[part 5 of 12: package /Cluster]
AUTOSAR XML (schema 4-3-0)
package /Cluster  (continued)
  can cluster HCP5_CANFD01: baudrate=500000, protocol-name=CAN, protocol-version=2.0, bus-off-recovery={bor-counter-l-1-to-l-2=1, bor-time-l-1=0.05, bor-time-l-2=0.2}, can-fd-baudrate=2000000  (continued)
    can physical channel CHNL: comm-connectors=CN_HCP5_CANFD01  (continued)
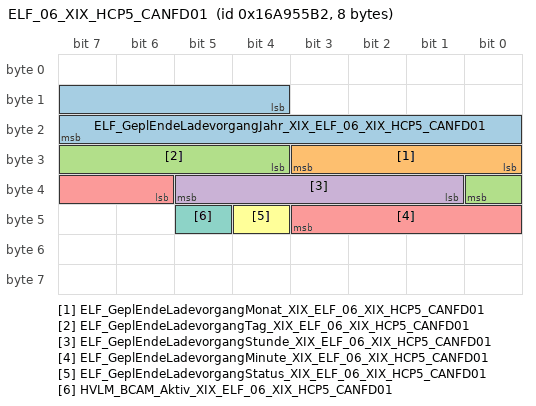
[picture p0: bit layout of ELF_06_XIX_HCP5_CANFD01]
      frame ELF_06_XIX_HCP5_CANFD01: id 0x16A955B2, to BMC_HV, frame-length=8, can-addressing-mode=EXTENDED, can-frame-rx-behavior=CAN-FD, can-frame-tx-behavior=CAN-FD
        pdu ELF_06_XIX_HCP5_CANFD01: length=8, transmission-mode-true-timing=cyclic-timing={time-offset=0, time-period=0.2}, unused-bit-pattern=0
          signal ELF_GeplEndeLadevorgangJahr_XIX_ELF_06_XIX_HCP5_CANFD01: start 12, 12 bit, little-endian, data-type-policy=OVERRIDE, i-signal-type=PRIMITIVE, init-value=4095, base-type=BT_ELF_GeplEndeLadevorgangJahr, compu {phys=raw for raw 0..4094, 4095=Cxfff_InitWert (CM_ELF_GeplEndeLadevorgangJahr_Cxfff_InitWert); unit Unit_Year}, range phys 0..4094 Unit_Year, raw 0..4095, unit=Unit_Year, transfer-property=PENDING  # Geplantes Ende des Ladevorgangs bei Laden nach Ladeplan, Jahr.
          signal ELF_GeplEndeLadevorgangMonat_XIX_ELF_06_XIX_HCP5_CANFD01: start 24, 4 bit, little-endian, data-type-policy=OVERRIDE, i-signal-type=PRIMITIVE, init-value=15, base-type=BT_ELF_GeplEndeLadevorgangMonat, compu {phys=raw for raw 1..12, 15=Cxf_Init (CM_ELF_GeplEndeLadevorgangMonat_Cxf_Init); unit Unit_Month}, range phys 1..12 Unit_Month, raw 1..15, unit=Unit_Month, transfer-property=PENDING  # Geplantes Ende bei Laden nach Ladeplan(Monat).
          signal ELF_GeplEndeLadevorgangTag_XIX_ELF_06_XIX_HCP5_CANFD01: start 28, 5 bit, little-endian, data-type-policy=OVERRIDE, i-signal-type=PRIMITIVE, init-value=0, base-type=BT_ELF_GeplEndeLadevorgangTag, compu {0=Cx0_Init (CM_ELF_GeplEndeLadevorgangTag_Cx0_Init), phys=raw for raw 1..31; unit Unit_Day}, range phys 1..31 Unit_Day, raw 0..31, unit=Unit_Day, transfer-property=PENDING  # Geplantes Ladeende bei Laden nach Ladeplan (Tag).
          signal ELF_GeplEndeLadevorgangStunde_XIX_ELF_06_XIX_HCP5_CANFD01: start 33, 5 bit, little-endian, data-type-policy=OVERRIDE, i-signal-type=PRIMITIVE, init-value=31, base-type=BT_ELF_GeplEndeLadevorgangStunde, compu {phys=raw for raw 0..23, 31=Cx1f_InitWert (CM_ELF_GeplEndeLadevorgangStunde_Cx1f_InitWert); unit Unit_Hours}, range phys 0..23 Unit_Hours, raw 0..31, unit=Unit_Hours, transfer-property=PENDING  # Geplantes Ladeende bei Laden nach Ladeplan, Stunde.
          signal ELF_GeplEndeLadevorgangMinute_XIX_ELF_06_XIX_HCP5_CANFD01: start 38, 6 bit, little-endian, data-type-policy=OVERRIDE, i-signal-type=PRIMITIVE, init-value=63, base-type=BT_ELF_GeplEndeLadevorgangMinute, compu {phys=raw for raw 0..59, 63=Cx3f_InitWert (CM_ELF_GeplEndeLadevorgangMinute_Cx3f_InitWert); unit Unit_Minut}, range phys 0..59 Unit_Minut, raw 0..63, unit=Unit_Minut, transfer-property=PENDING  # Geplantes Ladeende bei Laden nach Ladeplan, Minute.
          signal ELF_GeplEndeLadevorgangStatus_XIX_ELF_06_XIX_HCP5_CANFD01: start 44, 1 bit, little-endian, data-type-policy=OVERRIDE, i-signal-type=PRIMITIVE, init-value=0, base-type=BT_ELF_GeplEndeLadevorgangStatus, compu {0=Cx0_Startzeit_nicht_beruecksichtigen (CM_ELF_GeplEndeLadevorgangStatus_Cx0_Startzeit_nicht_beruecksichtigen), 1=Cx1_Startzeit_beruecksichtigen (CM_ELF_GeplEndeLadevorgangStatus_Cx1_Startzeit_beruecksichtigen)}, range raw 0..1, transfer-property=PENDING  # Gibt den Status des geplanten Ladeendes an und ob die hinterlegte Startzeit berücksichtigt werden soll.
          signal HVLM_BCAM_Aktiv_XIX_ELF_06_XIX_HCP5_CANFD01: start 45, 1 bit, little-endian, data-type-policy=OVERRIDE, i-signal-type=PRIMITIVE, init-value=0, base-type=BT_HVLM_BCAM_Aktiv, compu {0=Cx0_inaktiv (CM_HVLM_BCAM_Aktiv_Cx0_inaktiv), 1=Cx1_aktiv (CM_HVLM_BCAM_Aktiv_Cx1_aktiv)}, range raw 0..1, transfer-property=PENDING, to BMC_HV(timeout 2 s)  # Dieses Signal gibt den Aktivierungsstatus des Battery Charging Care Modes an und gehört zum HV-Laden
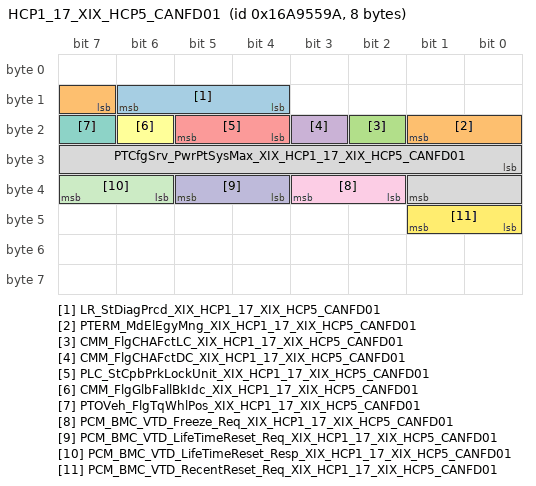
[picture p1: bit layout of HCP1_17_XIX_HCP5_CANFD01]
      frame HCP1_17_XIX_HCP5_CANFD01: id 0x16A9559A, to BMC_HV, frame-length=8, can-addressing-mode=EXTENDED, can-frame-rx-behavior=CAN-FD, can-frame-tx-behavior=CAN-FD
        pdu HCP1_17_XIX_HCP5_CANFD01: length=8, minimum-delay=0.1, transmission-mode-true-timing={cyclic-timing={time-offset=0, time-period=1}, event-controlled-timing={number-of-repetitions=0, repetition-period=0}}, unused-bit-pattern=0
          signal LR_StDiagPrcd_XIX_HCP1_17_XIX_HCP5_CANFD01: start 12, 3 bit, little-endian, data-type-policy=OVERRIDE, i-signal-type=PRIMITIVE, init-value=6, base-type=BT_LR_StDiagPrcd, invalid-value=Invalid_LR_StDiagPrcd_XIX_HCP1_17_XIX_HCP5_CANFD01:7, compu {0=Cx0_Inactive (CM_LR_StDiagPrcd_Cx0_Inactive), 1=Cx1_Not_available (CM_LR_StDiagPrcd_Cx1_Not_available), 2=Cx2_Conditions_not_fulfilled (CM_LR_StDiagPrcd_Cx2_Conditions_not_fulfilled), 3=Cx3_Running (CM_LR_StDiagPrcd_Cx3_Running), 4=Cx4_Finished_successful (CM_LR_StDiagPrcd_Cx4_Finished_successful), 5=Cx5_Finished_failed (CM_LR_StDiagPrcd_Cx5_Finished_failed), 6=Cx6_Init (CM_LR_StDiagPrcd_Cx6_Init), 7=Cx7_Fehler (CM_LR_StDiagPrcd_Cx7_Fehler)}, range raw 0..7, transfer-property=PENDING  # State of DMPLR component test
          signal PTERM_MdElEgyMng_XIX_HCP1_17_XIX_HCP5_CANFD01: start 15, 3 bit, little-endian, data-type-policy=OVERRIDE, i-signal-type=PRIMITIVE, init-value=0, base-type=BT_PTERM_MdElEgyMng, compu {0=Cx0_No_Hybrid (CM_PTERM_MdElEgyMng_Cx0_No_Hybrid), 1=Cx1_Depleting (CM_PTERM_MdElEgyMng_Cx1_Depleting), 2=Cx2_Soft_Depleting (CM_PTERM_MdElEgyMng_Cx2_Soft_Depleting), 3=Cx3_Sustaining (CM_PTERM_MdElEgyMng_Cx3_Sustaining), 4=Cx4_Increasing (CM_PTERM_MdElEgyMng_Cx4_Increasing), 5=Cx5_External_Control (CM_PTERM_MdElEgyMng_Cx5_External_Control)}, range raw 0..5, transfer-property=TRIGGERED-ON-CHANGE-WITHOUT-REPETITION  # mode of electic engergy management
          signal CMM_FlgCHAFctLC_XIX_HCP1_17_XIX_HCP5_CANFD01: start 18, 1 bit, little-endian, data-type-policy=OVERRIDE, i-signal-type=PRIMITIVE, init-value=0, base-type=BT_CMM_FlgCHAFctLC, compu {0=Cx0_charisma_off (CM_CMM_FlgCHAFctLC_Cx0_charisma_off), 1=Cx1_charisma_on (CM_CMM_FlgCHAFctLC_Cx1_charisma_on)}, range raw 0..1, transfer-property=TRIGGERED-ON-CHANGE-WITHOUT-REPETITION  # Signal to distinguish between LC system low and high. Information if LC is coded for charisma or not.
          signal CMM_FlgCHAFctDC_XIX_HCP1_17_XIX_HCP5_CANFD01: start 19, 1 bit, little-endian, data-type-policy=OVERRIDE, i-signal-type=PRIMITIVE, init-value=0, base-type=BT_CMM_FlgCHAFctDC, compu {0=Cx0_charisma_off (CM_CMM_FlgCHAFctDC_Cx0_charisma_off), 1=Cx1_charisma_on (CM_CMM_FlgCHAFctDC_Cx1_charisma_on)}, range raw 0..1, transfer-property=TRIGGERED-ON-CHANGE-WITHOUT-REPETITION  # Signal to distinguish between DC system low and high. Information if DC is coded for charisma or not.
          signal PLC_StCpbPrkLockUnit_XIX_HCP1_17_XIX_HCP5_CANFD01: start 20, 2 bit, little-endian, data-type-policy=OVERRIDE, i-signal-type=PRIMITIVE, init-value=2, base-type=BT_PLC_StCpbPrkLockUnit, invalid-value=Invalid_PLC_StCpbPrkLockUnit_XIX_HCP1_17_XIX_HCP5_CANFD01:3, compu {0=Cx0_Nicht_Verfuegbar (CM_PLC_StCpbPrkLockUnit_Cx0_Nicht_Verfuegbar) (Nicht Verfügbar), 1=Cx1_Verfuegbar (CM_PLC_StCpbPrkLockUnit_Cx1_Verfuegbar) (Verfügbar), 2=Cx2_Init (CM_PLC_StCpbPrkLockUnit_Cx2_Init), 3=Cx3_Fehler (CM_PLC_StCpbPrkLockUnit_Cx3_Fehler)}, range raw 0..3, transfer-property=TRIGGERED-ON-CHANGE-WITHOUT-REPETITION  # Beschreibt die Fähigkeit der Parksperreneinheit zu Verfahren und die eingenommene Position korrekt zu melden.
          signal CMM_FlgGlbFallBkIdc_XIX_HCP1_17_XIX_HCP5_CANFD01: start 22, 1 bit, little-endian, data-type-policy=OVERRIDE, i-signal-type=PRIMITIVE, init-value=0, base-type=BT_CMM_FlgGlbFallBkIdc, compu {0=Cx0_no_fallback (CM_CMM_FlgGlbFallBkIdc_Cx0_no_fallback), 1=Cx1_fallback_requested (CM_CMM_FlgGlbFallBkIdc_Cx1_fallback_requested)}, range raw 0..1, transfer-property=PENDING  # Signal to request a global fallback of the Charisma mode to default value.
          signal PTOVeh_FlgTqWhlPos_XIX_HCP1_17_XIX_HCP5_CANFD01: start 23, 1 bit, little-endian, data-type-policy=OVERRIDE, i-signal-type=PRIMITIVE, init-value=0, base-type=BT_PTOVeh_FlgTqWhlPos, compu {0=Cx0_overall_static_wheel_torque_is_negative_or_zero (CM_PTOVeh_FlgTqWhlPos_Cx0_overall_static_wheel_torque_is_negative_or_zero), 1=Cx1_overall_static_wheel_torque_is_positive (CM_PTOVeh_FlgTqWhlPos_Cx1_overall_static_wheel_torque_is_positive)}, range raw 0..1, transfer-property=PENDING  # flag indicating overall static wheel torque is positive
          signal PTCfgSrv_PwrPtSysMax_XIX_HCP1_17_XIX_HCP5_CANFD01: start 24, 10 bit, little-endian, data-type-policy=OVERRIDE, i-signal-type=PRIMITIVE, init-value=0, base-type=BT_PTCfgSrv_PwrPtSysMax, compu {phys=raw*2 for raw 0..1000; unit Unit_KiloWatt}, range phys 0..2000 Unit_KiloWatt, raw 0..1000, unit=Unit_KiloWatt, transfer-property=PENDING  # Gesamtleistung des Antriebsstrangs in kW
          signal PCM_BMC_VTD_Freeze_Req_XIX_HCP1_17_XIX_HCP5_CANFD01: start 34, 2 bit, little-endian, data-type-policy=OVERRIDE, i-signal-type=PRIMITIVE, init-value=2, base-type=BT_PCM_BMC_VTD_Freeze_Req, invalid-value=Invalid_PCM_BMC_VTD_Freeze_Req_XIX_HCP1_17_XIX_HCP5_CANFD01:3, compu {0=Cx0_NoResetResponse (CM_PCM_BMC_VTD_Freeze_Req_Cx0_NoResetResponse), 1=Cx1_ResetResponse (CM_PCM_BMC_VTD_Freeze_Req_Cx1_ResetResponse), 2=Cx2_Init (CM_PCM_BMC_VTD_Freeze_Req_Cx2_Init), 3=Cx3_Fehler (CM_PCM_BMC_VTD_Freeze_Req_Cx3_Fehler)}, range raw 0..3, transfer-property=PENDING, to BMC_HV(timeout 5 s)  # Synchronissation of Freeze-Condition for VTD-ITs between HCP1 and BMC
          signal PCM_BMC_VTD_LifeTimeReset_Req_XIX_HCP1_17_XIX_HCP5_CANFD01: start 36, 2 bit, little-endian, data-type-policy=OVERRIDE, i-signal-type=PRIMITIVE, init-value=2, base-type=BT_PCM_BMC_VTD_LifeTimeReset_Req, invalid-value=Invalid_PCM_BMC_VTD_LifeTimeReset_Req_XIX_HCP1_17_XIX_HCP5_CANFD01:3, compu {0=Cx0_NoResetResponse (CM_PCM_BMC_VTD_LifeTimeReset_Req_Cx0_NoResetResponse), 1=Cx1_ResetResponse (CM_PCM_BMC_VTD_LifeTimeReset_Req_Cx1_ResetResponse), 2=Cx2_Init (CM_PCM_BMC_VTD_LifeTimeReset_Req_Cx2_Init), 3=Cx3_Fehler (CM_PCM_BMC_VTD_LifeTimeReset_Req_Cx3_Fehler)}, range raw 0..3, transfer-property=PENDING, to BMC_HV(timeout 5 s)  # Synchronissation of Freeze-Condition for VTD-ITs between HCP1 and BMC
          signal PCM_BMC_VTD_LifeTimeReset_Resp_XIX_HCP1_17_XIX_HCP5_CANFD01: start 38, 2 bit, little-endian, data-type-policy=OVERRIDE, i-signal-type=PRIMITIVE, init-value=2, base-type=BT_PCM_BMC_VTD_LifeTimeReset_Resp, invalid-value=Invalid_PCM_BMC_VTD_LifeTimeReset_Resp_XIX_HCP1_17_XIX_HCP5_CANFD01:3, compu {0=Cx0_NoResetResponse (CM_PCM_BMC_VTD_LifeTimeReset_Resp_Cx0_NoResetResponse), 1=Cx1_ResetResponse (CM_PCM_BMC_VTD_LifeTimeReset_Resp_Cx1_ResetResponse), 2=Cx2_Init (CM_PCM_BMC_VTD_LifeTimeReset_Resp_Cx2_Init), 3=Cx3_Fehler (CM_PCM_BMC_VTD_LifeTimeReset_Resp_Cx3_Fehler)}, range raw 0..3, transfer-property=PENDING, to BMC_HV(timeout 5 s)  # Synchronissation of Freeze-Condition for VTD-ITs between HCP1 and BMC
          signal PCM_BMC_VTD_RecentReset_Req_XIX_HCP1_17_XIX_HCP5_CANFD01: start 40, 2 bit, little-endian, data-type-policy=OVERRIDE, i-signal-type=PRIMITIVE, init-value=2, base-type=BT_PCM_BMC_VTD_RecentReset_Req, invalid-value=Invalid_PCM_BMC_VTD_RecentReset_Req_XIX_HCP1_17_XIX_HCP5_CANFD01:3, compu {0=Cx0_NoResetResponse (CM_PCM_BMC_VTD_RecentReset_Req_Cx0_NoResetResponse), 1=Cx1_ResetResponse (CM_PCM_BMC_VTD_RecentReset_Req_Cx1_ResetResponse), 2=Cx2_Init (CM_PCM_BMC_VTD_RecentReset_Req_Cx2_Init), 3=Cx3_Fehler (CM_PCM_BMC_VTD_RecentReset_Req_Cx3_Fehler)}, range raw 0..3, transfer-property=PENDING, to BMC_HV(timeout 5 s)  # Synchronissation of Freeze-Condition for VTD-ITs between HCP1 and BMC
      frame HVEM_07_XIX_HCP5_CANFD01: id 0xAF954C7, to BMC_HV, frame-length=32, can-addressing-mode=EXTENDED, can-frame-rx-behavior=CAN-FD, can-frame-tx-behavior=CAN-FD
        pdu HVEM_07_XIX_HCP5_CANFD01: length=32, minimum-delay=0.01, transmission-mode-true-timing={cyclic-timing={time-offset=0, time-period=0.08}, event-controlled-timing={number-of-repetitions=0, repetition-period=0}}, unused-bit-pattern=0
          signal HVEM_Nachladen_Anf_XIX_HVEM_07_XIX_HCP5_CANFD01: start 12, 1 bit, little-endian, data-type-policy=OVERRIDE, i-signal-type=PRIMITIVE, init-value=0, base-type=BT_HVEM_Nachladen_Anf, compu {0=Cx0_keine_Anforderung (CM_HVEM_Nachladen_Anf_Cx0_keine_Anforderung), 1=Cx1_Nachladen_angefordert (CM_HVEM_Nachladen_Anf_Cx1_Nachladen_angefordert)}, range raw 0..1, transfer-property=TRIGGERED-ON-CHANGE-WITHOUT-REPETITION  # Anforderung für HV Laden bei gestecktem Stecker und deaktivierter Ladeanforderung
          signal HVEM_IstLeistung_HVVerbraucher_XIX_HVEM_07_XIX_HCP5_CANFD01: start 13, 12 bit, little-endian, data-type-policy=OVERRIDE, i-signal-type=PRIMITIVE, init-value=4094, base-type=BT_HVEM_IstLeistung_HVVerbraucher, invalid-value=Invalid_HVEM_IstLeistung_HVVerbraucher_XIX_HVEM_07_XIX_HCP5_CANFD01:4095, compu {phys=raw*50-102300 for raw 0..4093, 4094=Cxffe_Init (CM_HVEM_IstLeistung_HVVerbraucher_Cxffe_Init), 4095=Cxfff_Fehler (CM_HVEM_IstLeistung_HVVerbraucher_Cxfff_Fehler); unit Unit_Watt}, range phys -102300..102350 Unit_Watt, raw 0..4095, unit=Unit_Watt, transfer-property=PENDING  # Ist Verbrauch der Nebenverbraucher (hochvoltseitig)
          signal HVEM_Nachlad_Status_XIX_HVEM_07_XIX_HCP5_CANFD01: start 25, 2 bit, little-endian, data-type-policy=OVERRIDE, i-signal-type=PRIMITIVE, init-value=3, base-type=BT_HVEM_Nachlad_Status, compu {0=Cx0_nicht_moeglich_Fehler (CM_HVEM_Nachlad_Status_Cx0_nicht_moeglich_Fehler) (nicht_moeglich__Fehler), 1=Cx1_moeglich_begonnen (CM_HVEM_Nachlad_Status_Cx1_moeglich_begonnen) (moeglich__begonnen), 2=Cx2_Beendet (CM_HVEM_Nachlad_Status_Cx2_Beendet), 3=Cx3_Init (CM_HVEM_Nachlad_Status_Cx3_Init)}, range raw 0..3, transfer-property=TRIGGERED-ON-CHANGE-WITHOUT-REPETITION  # Status der Umsetzung der Nachladeanforderung der NV-Seite.
          signal HVEM_TME_Energie_Vorgabe_XIX_HVEM_07_XIX_HCP5_CANFD01: start 27, 11 bit, little-endian, data-type-policy=OVERRIDE, i-signal-type=PRIMITIVE, init-value=2046, base-type=BT_HVEM_TME_Energie_Vorgabe, invalid-value=Invalid_HVEM_TME_Energie_Vorgabe_XIX_HVEM_07_XIX_HCP5_CANFD01:2047, compu {phys=raw*10 for raw 0..2045, 2046=Cx7fe_Init (CM_HVEM_TME_Energie_Vorgabe_Cx7fe_Init), 2047=Cx7ff_Fehler (CM_HVEM_TME_Energie_Vorgabe_Cx7ff_Fehler); unit Unit_WattHour}, range phys 0..20450 Unit_WattHour, raw 0..2047, unit=Unit_WattHour, transfer-property=PENDING  # Erweiterte Auflösung von 10Wh für Signal HVEM_Energie_Klima_Vorgabe.
          signal HVEM_TME_Leistung_Vorgabe_XIX_HVEM_07_XIX_HCP5_CANFD01: start 38, 10 bit, little-endian, data-type-policy=OVERRIDE, i-signal-type=PRIMITIVE, init-value=1022, base-type=BT_HVEM_TME_Leistung_Vorgabe, invalid-value=Invalid_HVEM_TME_Leistung_Vorgabe_XIX_HVEM_07_XIX_HCP5_CANFD01:1023, compu {phys=raw*50 for raw 0..1021, 1022=Cx3fe_Init (CM_HVEM_TME_Leistung_Vorgabe_Cx3fe_Init), 1023=Cx3ff_Fehler (CM_HVEM_TME_Leistung_Vorgabe_Cx3ff_Fehler); unit Unit_Watt}, range phys 0..51050 Unit_Watt, raw 0..1023, unit=Unit_Watt, transfer-property=PENDING  # Die Leistung, welche das HVEM der TME zur Verfügung stellt.
          signal HVEM_IstStrom_HVVerbraucher_XIX_HVEM_07_XIX_HCP5_CANFD01: start 48, 12 bit, little-endian, data-type-policy=OVERRIDE, i-signal-type=PRIMITIVE, init-value=4094, base-type=BT_HVEM_IstStrom_HVVerbraucher, invalid-value=Invalid_HVEM_IstStrom_HVVerbraucher_XIX_HVEM_07_XIX_HCP5_CANFD01:4095, compu {phys=raw*0.1-204.7 for raw 0..4093, 4094=Cxffe_Init (CM_HVEM_IstStrom_HVVerbraucher_Cxffe_Init), 4095=Cxfff_Fehler (CM_HVEM_IstStrom_HVVerbraucher_Cxfff_Fehler); unit Unit_Amper}, range phys -204.7..204.6 Unit_Amper, raw 0..4095, unit=Unit_Amper, transfer-property=PENDING  # Iststromaufnahme der elektrischen Nebenaggregate aus dem HV Zwischenkreis
          signal HVEM_AIAD_Energieinhalt_XIX_HVEM_07_XIX_HCP5_CANFD01: start 60, 11 bit, little-endian, data-type-policy=OVERRIDE, i-signal-type=PRIMITIVE, init-value=2046, base-type=BT_HVEM_AIAD_Energieinhalt, invalid-value=Invalid_HVEM_AIAD_Energieinhalt_XIX_HVEM_07_XIX_HCP5_CANFD01:2047, compu {phys=raw*50 for raw 0..2045, 2046=Cx7fe_Init (CM_HVEM_AIAD_Energieinhalt_Cx7fe_Init), 2047=Cx7ff_Fehler (CM_HVEM_AIAD_Energieinhalt_Cx7ff_Fehler); unit Unit_WattHour}, range phys 0..102250 Unit_WattHour, raw 0..2047, unit=Unit_WattHour, transfer-property=PENDING  # Erweiterte Auflösung
          signal HVEM_AIAD_Leistungsvorgabe_XIX_HVEM_07_XIX_HCP5_CANFD01: start 71, 9 bit, little-endian, data-type-policy=OVERRIDE, i-signal-type=PRIMITIVE, init-value=510, base-type=BT_HVEM_AIAD_Leistungsvorgabe, invalid-value=Invalid_HVEM_AIAD_Leistungsvorgabe_XIX_HVEM_07_XIX_HCP5_CANFD01:511, compu {phys=raw*50 for raw 0..509, 510=Cx1fe_Init (CM_HVEM_AIAD_Leistungsvorgabe_Cx1fe_Init), 511=Cx1ff_Fehler (CM_HVEM_AIAD_Leistungsvorgabe_Cx1ff_Fehler); unit Unit_Watt}, range phys 0..25450 Unit_Watt, raw 0..511, unit=Unit_Watt, transfer-property=PENDING  # Leistungsvorgabe vom HVEM an das ADC
          signal HVEM_STK_Leistung_verfuegbar_XIX_HVEM_07_XIX_HCP5_CANFD01: start 80, 8 bit, little-endian, data-type-policy=OVERRIDE, i-signal-type=PRIMITIVE, init-value=254, base-type=BT_HVEM_STK_Leistung_verfuegbar, invalid-value=Invalid_HVEM_STK_Leistung_verfuegbar_XIX_HVEM_07_XIX_HCP5_CANFD01:255, compu {phys=raw*50 for raw 0..253, 254=Cxfe_Init (CM_HVEM_STK_Leistung_verfuegbar_Cxfe_Init), 255=Cxff_Fehler (CM_HVEM_STK_Leistung_verfuegbar_Cxff_Fehler); unit Unit_Watt}, range phys 0..12650 Unit_Watt, raw 0..255, unit=Unit_Watt, transfer-property=PENDING  # Verfügbare Leistung seitens Ladeinfrastruktur für die Standklimatisierung
          signal HVEM_Abschaltstufe_XIX_HVEM_07_XIX_HCP5_CANFD01: start 88, 3 bit, little-endian, data-type-policy=OVERRIDE, i-signal-type=PRIMITIVE, init-value=6, base-type=BT_HVEM_Abschaltstufe, invalid-value=Invalid_HVEM_Abschaltstufe_XIX_HVEM_07_XIX_HCP5_CANFD01:7, compu {0=Cx0_Stufe0 (CM_HVEM_Abschaltstufe_Cx0_Stufe0), 1=Cx1_Stufe1 (CM_HVEM_Abschaltstufe_Cx1_Stufe1), 2=Cx2_Stufe2 (CM_HVEM_Abschaltstufe_Cx2_Stufe2), 3=Cx3_Stufe3 (CM_HVEM_Abschaltstufe_Cx3_Stufe3), 4=Cx4_Stufe4 (CM_HVEM_Abschaltstufe_Cx4_Stufe4), 5=Cx5_Stufe5 (CM_HVEM_Abschaltstufe_Cx5_Stufe5), 6=Cx6_Init (CM_HVEM_Abschaltstufe_Cx6_Init), 7=Cx7_Fehler (CM_HVEM_Abschaltstufe_Cx7_Fehler)}, range raw 0..7, transfer-property=TRIGGERED-ON-CHANGE-WITHOUT-REPETITION  # Abschaltstufen an die Hochvoltteilnehmer
          signal HVEM_TME_Sollstatus_XIX_HVEM_07_XIX_HCP5_CANFD01: start 91, 2 bit, little-endian, data-type-policy=OVERRIDE, i-signal-type=PRIMITIVE, init-value=0, base-type=BT_HVEM_TME_Sollstatus, compu {0=Cx0_Regelbetrieb (CM_HVEM_TME_Sollstatus_Cx0_Regelbetrieb), 1=Cx1_Leistung_reduzieren (CM_HVEM_TME_Sollstatus_Cx1_Leistung_reduzieren), 2=Cx2_Verzoegerung_Lastabwurf (CM_HVEM_TME_Sollstatus_Cx2_Verzoegerung_Lastabwurf), 3=Cx3_Leistung_erhoehen (CM_HVEM_TME_Sollstatus_Cx3_Leistung_erhoehen)}, range raw 0..3, transfer-property=TRIGGERED-ON-CHANGE-WITHOUT-REPETITION  # Leistungskommandierung der TME aufgrund externer Einfluesse. Es kann eine Leistungserhöhung (Mindestschub), eine Leistungsreduzierung (Kick Down) oder ein verzoegerter Lastabwurf angefragt werden.
          signal HVEM_StCpbDrv_XIX_HVEM_07_XIX_HCP5_CANFD01: start 93, 3 bit, little-endian, data-type-policy=OVERRIDE, i-signal-type=PRIMITIVE, init-value=0, base-type=BT_HVEM_StCpbDrv, compu {0=Cx0_Init (CM_HVEM_StCpbDrv_Cx0_Init), 1=Cx1_erweiterte_Performance_verfuegbar (CM_HVEM_StCpbDrv_Cx1_erweiterte_Performance_verfuegbar) (erweiterte_Performance_verfügbar), 2=Cx2_normale_Performance_verfuegbar (CM_HVEM_StCpbDrv_Cx2_normale_Performance_verfuegbar) (normale_Performance_verfügbar), 3=Cx3_geringfuegige_Leistungseinschraenkung (CM_HVEM_StCpbDrv_Cx3_geringfuegige_Leistungseinschraenkung) (geringfügige_Leistungseinschränkung), 4=Cx4_Warnung_erhebliche_Leistungseinschraenkung (CM_HVEM_StCpbDrv_Cx4_Warnung_erhebliche_Leistungseinschraenkung) (Warnung_erhebliche_Leistungseinschränkung), 5=Cx5_Fehler_schwerwiegende_Leistungseinschraenkung (CM_HVEM_StCpbDrv_Cx5_Fehler_schwerwiegende_Leistungseinschraenkung) (Fehler_schwerwiegende_Leistungseinschränkung)}, range raw 0..5, transfer-property=PENDING  # Leistungsfähigkeit der HVB für Antrieb
          signal HVEM_ETM_Max_Ladeleistung_XIX_HVEM_07_XIX_HCP5_CANFD01: start 96, 13 bit, little-endian, data-type-policy=OVERRIDE, i-signal-type=PRIMITIVE, init-value=8190, base-type=BT_HVEM_ETM_Max_Ladeleistung, invalid-value=Invalid_HVEM_ETM_Max_Ladeleistung_XIX_HVEM_07_XIX_HCP5_CANFD01:8191, compu {phys=raw*100 for raw 0..8189, 8190=Cx1ffe_Init (CM_HVEM_ETM_Max_Ladeleistung_Cx1ffe_Init), 8191=Cx1fff_Fehler (CM_HVEM_ETM_Max_Ladeleistung_Cx1fff_Fehler); unit Unit_Watt}, range phys 0..818900 Unit_Watt, raw 0..8191, unit=Unit_Watt, transfer-property=TRIGGERED-ON-CHANGE-WITHOUT-REPETITION  # Elektrische Leistung, die dem ETM vom HVEM zur Abgabe von den elektrischen Antriebsmaschinen freigegeben wird (generatorischer Betrieb)
          signal HVEM_Leistungsvorhalt_Entladen_XIX_HVEM_07_XIX_HCP5_CANFD01: start 109, 11 bit, little-endian, data-type-policy=OVERRIDE, i-signal-type=PRIMITIVE, init-value=2046, base-type=BT_HVEM_Leistungsvorhalt_Entladen, invalid-value=Invalid_HVEM_Leistungsvorhalt_Entladen_XIX_HVEM_07_XIX_HCP5_CANFD01:2047, compu {phys=raw*50-51100 for raw 0..2045, 2046=Cx7fe_Init (CM_HVEM_Leistungsvorhalt_Entladen_Cx7fe_Init), 2047=Cx7ff_Fehler (CM_HVEM_Leistungsvorhalt_Entladen_Cx7ff_Fehler); unit Unit_Watt}, range phys -51100..51150 Unit_Watt, raw 0..2047, unit=Unit_Watt, transfer-property=PENDING  # Elektrische Leistung, die vom ETM auf der Entladegrenze der Traktionsbatterie zu berücksichtigen ist und sich somit auf die Leistungsaufnahme durch die elektrischen Antriebsmaschinen auswirkt
          signal HVEM_Leistungsvorhalt_Laden_XIX_HVEM_07_XIX_HCP5_CANFD01: start 120, 11 bit, little-endian, data-type-policy=OVERRIDE, i-signal-type=PRIMITIVE, init-value=2046, base-type=BT_HVEM_Leistungsvorhalt_Laden, invalid-value=Invalid_HVEM_Leistungsvorhalt_Laden_XIX_HVEM_07_XIX_HCP5_CANFD01:2047, compu {phys=raw*50-51100 for raw 0..2045, 2046=Cx7fe_Init (CM_HVEM_Leistungsvorhalt_Laden_Cx7fe_Init), 2047=Cx7ff_Fehler (CM_HVEM_Leistungsvorhalt_Laden_Cx7ff_Fehler); unit Unit_Watt}, range phys -51100..51150 Unit_Watt, raw 0..2047, unit=Unit_Watt, transfer-property=PENDING  # Elektrische Leistung, die vom ETM auf der Ladegrenze der Traktionsbatterie zu berücksichtigen ist und sich somit auf die Leistungsabgabe von den elektrischen Antriebsmaschinen auswirkt
          signal HVEM_ETM_Max_Entladeleistung_XIX_HVEM_07_XIX_HCP5_CANFD01: start 131, 13 bit, little-endian, data-type-policy=OVERRIDE, i-signal-type=PRIMITIVE, init-value=8190, base-type=BT_HVEM_ETM_Max_Entladeleistung, invalid-value=Invalid_HVEM_ETM_Max_Entladeleistung_XIX_HVEM_07_XIX_HCP5_CANFD01:8191, compu {phys=raw*100 for raw 0..8189, 8190=Cx1ffe_Init (CM_HVEM_ETM_Max_Entladeleistung_Cx1ffe_Init), 8191=Cx1fff_Fehler (CM_HVEM_ETM_Max_Entladeleistung_Cx1fff_Fehler); unit Unit_Watt}, range phys 0..818900 Unit_Watt, raw 0..8191, unit=Unit_Watt, transfer-property=TRIGGERED-ON-CHANGE-WITHOUT-REPETITION  # Elektrische Leistung, die dem ETM zur Aufnahme durch die elektrischen Antriebsmaschinen freigegeben wird (i.d.R. motorischer Betrieb)
          signal HVEM_AIAD_RekuVerbot_XIX_HVEM_07_XIX_HCP5_CANFD01: start 144, 2 bit, little-endian, data-type-policy=OVERRIDE, i-signal-type=PRIMITIVE, init-value=0, base-type=BT_HVEM_AIAD_RekuVerbot, compu {0=Cx0_kein_Verbot (CM_HVEM_AIAD_RekuVerbot_Cx0_kein_Verbot), 1=Cx1_Reku_Verbot (CM_HVEM_AIAD_RekuVerbot_Cx1_Reku_Verbot), 2=Cx2_reserviert (CM_HVEM_AIAD_RekuVerbot_Cx2_reserviert), 3=Cx3_reserviert (CM_HVEM_AIAD_RekuVerbot_Cx3_reserviert)}, range raw 0..3, transfer-property=PENDING  # Rückspeiseeinschränkung für ADR
          signal HVEM_TME_MSF_aktiv_XIX_HVEM_07_XIX_HCP5_CANFD01: start 146, 1 bit, little-endian, data-type-policy=OVERRIDE, i-signal-type=PRIMITIVE, init-value=0, base-type=BT_HVEM_TME_MSF_aktiv, compu {0=Cx0_InitWert_MSF_nicht_aktiv (CM_HVEM_TME_MSF_aktiv_Cx0_InitWert_MSF_nicht_aktiv), 1=Cx1_MSF_aktiv (CM_HVEM_TME_MSF_aktiv_Cx1_MSF_aktiv)}, range raw 0..1, transfer-property=PENDING  # Aufforderung an TME Leistung zu erhöhen aufgrund aktiver Mindestschubfunktion.
          signal HVEM_BMC_CHA_Wunschleistung_XIX_HVEM_07_XIX_HCP5_CANFD01: start 147, 13 bit, little-endian, data-type-policy=OVERRIDE, i-signal-type=PRIMITIVE, init-value=8190, base-type=BT_HVEM_BMC_CHA_Wunschleistung, invalid-value=Invalid_HVEM_BMC_CHA_Wunschleistung_XIX_HVEM_07_XIX_HCP5_CANFD01:8191, compu {phys=raw*100 for raw 0..8189, 8190=Cx1ffe_Init (CM_HVEM_BMC_CHA_Wunschleistung_Cx1ffe_Init), 8191=Cx1fff_Fehler (CM_HVEM_BMC_CHA_Wunschleistung_Cx1fff_Fehler); unit Unit_Watt}, range phys 0..818900 Unit_Watt, raw 0..8191, unit=Unit_Watt, transfer-property=PENDING, to BMC_HV(timeout 0.8 s)  # Charisma abhängiger Systemleistungsbedarf. Je nach Charismaeinstellung soll die Batterie so temperiert werden, dass die Systemleistung erreicht werden kann.
          signal HVEM_SystemMinLeistungsgrenze_XIX_HVEM_07_XIX_HCP5_CANFD01: start 160, 7 bit, little-endian, data-type-policy=OVERRIDE, i-signal-type=PRIMITIVE, init-value=126, base-type=BT_HVEM_SystemMinLeistungsgrenze, invalid-value=Invalid_HVEM_SystemMinLeistungsgrenze_XIX_HVEM_07_XIX_HCP5_CANFD01:127, compu {phys=raw*1000 for raw 0..125, 126=Cx7e_Init (CM_HVEM_SystemMinLeistungsgrenze_Cx7e_Init), 127=Cx7f_Fehler (CM_HVEM_SystemMinLeistungsgrenze_Cx7f_Fehler); unit Unit_Watt}, range phys 0..125000 Unit_Watt, raw 0..127, unit=Unit_Watt, transfer-property=PENDING, to BMC_HV(timeout 0.8 s)  # Benötigte Mindestleistung für den elektrischen Fahrzeugbetrieb. Diese Leistung besteht aus LimpHome-Grenze, TME_Minleistung, NVEM-FuSi-Grenze und ADR-Vorhalt.
          signal HVEM_StLimElAcy_XIX_HVEM_07_XIX_HCP5_CANFD01: start 167, 1 bit, little-endian, data-type-policy=OVERRIDE, i-signal-type=PRIMITIVE, init-value=0, base-type=BT_HVEM_StLimElAcy, compu {0=Cx0_InitWert_nicht_aktiv (CM_HVEM_StLimElAcy_Cx0_InitWert_nicht_aktiv), 1=Cx1_aktiv (CM_HVEM_StLimElAcy_Cx1_aktiv)}, range raw 0..1, transfer-property=PENDING  # Das HVEM kündigt an, dass das Kontingent für ETM vergrößert wird. (Acknowledge)
          signal HVEM_StCpbElAcy_XIX_HVEM_07_XIX_HCP5_CANFD01: start 168, 1 bit, little-endian, data-type-policy=OVERRIDE, i-signal-type=PRIMITIVE, init-value=0, base-type=BT_HVEM_StCpbElAcy, compu {0=Cx0_InitWert_keine_Abschaltung_moeglich (CM_HVEM_StCpbElAcy_Cx0_InitWert_keine_Abschaltung_moeglich) (InitWert_keine_Abschaltung_möglich), 1=Cx1_Abschaltung_moeglich (CM_HVEM_StCpbElAcy_Cx1_Abschaltung_moeglich) (Abschaltung_möglich)}, range raw 0..1, transfer-property=PENDING  # HVEM signalisiert, ob eine Abschaltung der Verbraucher möglich ist
          signal HVEM_ETM_Max_Leistung_Verteiler_XIX_HVEM_07_XIX_HCP5_CANFD01: start 169, 10 bit, little-endian, data-type-policy=OVERRIDE, i-signal-type=PRIMITIVE, init-value=1022, base-type=BT_HVEM_ETM_Max_Leistung_Verteiler, invalid-value=Invalid_HVEM_ETM_Max_Leistung_Verteiler_XIX_HVEM_07_XIX_HCP5_CANFD01:1023, compu {phys=raw*50 for raw 0..1021, 1022=Cx3fe_Init (CM_HVEM_ETM_Max_Leistung_Verteiler_Cx3fe_Init), 1023=Cx3ff_Fehler (CM_HVEM_ETM_Max_Leistung_Verteiler_Cx3ff_Fehler); unit Unit_Watt}, range phys 0..51050 Unit_Watt, raw 0..1023, unit=Unit_Watt, transfer-property=PENDING  # Maximal zulässige Leistung für die Verbraucher eKat und eTV
          signal HVEM_MMTR_State_XIX_HVEM_07_XIX_HCP5_CANFD01: start 179, 4 bit, little-endian, data-type-policy=OVERRIDE, i-signal-type=PRIMITIVE, init-value=0, base-type=BT_HVEM_MMTR_State, invalid-value=Invalid_HVEM_MMTR_State_XIX_HVEM_07_XIX_HCP5_CANFD01:15, compu {0=Cx0_Nicht_verfuegbar (CM_HVEM_MMTR_State_Cx0_Nicht_verfuegbar), 1=Cx1_Inaktiv (CM_HVEM_MMTR_State_Cx1_Inaktiv), 2=Cx2_Aktiv_Vorkonditionierung (CM_HVEM_MMTR_State_Cx2_Aktiv_Vorkonditionierung), 3=Cx3_Abgeschlossen_Vorkonditionierung (CM_HVEM_MMTR_State_Cx3_Abgeschlossen_Vorkonditionierung), 4=Cx4_Aktiv_TrackSession (CM_HVEM_MMTR_State_Cx4_Aktiv_TrackSession), 5=Cx5_Aktiv_Endurance (CM_HVEM_MMTR_State_Cx5_Aktiv_Endurance), 6=Cx6_Aktiv_HotLap (CM_HVEM_MMTR_State_Cx6_Aktiv_HotLap), 7=Cx7_Beendet_TrackSession (CM_HVEM_MMTR_State_Cx7_Beendet_TrackSession), 14=Cxe_Init (CM_HVEM_MMTR_State_Cxe_Init), 15=Cxf_Fehler (CM_HVEM_MMTR_State_Cxf_Fehler)}, range raw 0..15, transfer-property=PENDING, to BMC_HV(timeout 0.8 s)  # Signal zur Signalisierung des Status der MMTR Funktion durch das Mastermodul HVEM
          signal HVEM_ETM_Max_Ladeleistung_02_XIX_HVEM_07_XIX_HCP5_CANFD01: start 183, 15 bit, little-endian, data-type-policy=OVERRIDE, i-signal-type=PRIMITIVE, init-value=32766, base-type=BT_HVEM_ETM_Max_Ladeleistung_02, invalid-value=Invalid_HVEM_ETM_Max_Ladeleistung_02_XIX_HVEM_07_XIX_HCP5_CANFD01:32767, compu {phys=raw*100 for raw 0..32500, 32766=Cx7ffe_Init (CM_HVEM_ETM_Max_Ladeleistung_02_Cx7ffe_Init), 32767=Cx7fff_Fehler (CM_HVEM_ETM_Max_Ladeleistung_02_Cx7fff_Fehler); unit Unit_Watt}, range phys 0..3250000 Unit_Watt, raw 0..32767, unit=Unit_Watt, transfer-property=TRIGGERED-ON-CHANGE-WITHOUT-REPETITION  # Elektrische Leistung, die dem ETM vom HVEM zur Abgabe von den elektrischen Antriebsmaschinen freigegeben wird (generatorischer Betrieb)
          signal HVEM_ETM_Max_Entladeleistung_02_XIX_HVEM_07_XIX_HCP5_CANFD01: start 198, 15 bit, little-endian, data-type-policy=OVERRIDE, i-signal-type=PRIMITIVE, init-value=32766, base-type=BT_HVEM_ETM_Max_Entladeleistung_02, invalid-value=Invalid_HVEM_ETM_Max_Entladeleistung_02_XIX_HVEM_07_XIX_HCP5_CANFD01:32767, compu {phys=raw*100 for raw 0..32500, 32766=Cx7ffe_Init (CM_HVEM_ETM_Max_Entladeleistung_02_Cx7ffe_Init), 32767=Cx7fff_Fehler (CM_HVEM_ETM_Max_Entladeleistung_02_Cx7fff_Fehler); unit Unit_Watt}, range phys 0..3250000 Unit_Watt, raw 0..32767, unit=Unit_Watt, transfer-property=TRIGGERED-ON-CHANGE-WITHOUT-REPETITION  # Elektrische Leistung, die dem ETM zur Aufnahme durch die elektrischen Antriebsmaschinen freigegeben wird (i.d.R. motorischer Betrieb)
          signal HVEM_BMC_CHA_Wunschleistung_02_XIX_HVEM_07_XIX_HCP5_CANFD01: start 213, 15 bit, little-endian, data-type-policy=OVERRIDE, i-signal-type=PRIMITIVE, init-value=32766, base-type=BT_HVEM_BMC_CHA_Wunschleistung_02, invalid-value=Invalid_HVEM_BMC_CHA_Wunschleistung_02_XIX_HVEM_07_XIX_HCP5_CANFD01:32767, compu {phys=raw*100 for raw 0..32500, 32766=Cx7ffe_Init (CM_HVEM_BMC_CHA_Wunschleistung_02_Cx7ffe_Init), 32767=Cx7fff_Fehler (CM_HVEM_BMC_CHA_Wunschleistung_02_Cx7fff_Fehler); unit Unit_Watt}, range phys 0..3250000 Unit_Watt, raw 0..32767, unit=Unit_Watt, transfer-property=PENDING, to BMC_HV(timeout 0.8 s)  # Charisma abhängiger Systemleistungsbedarf. Je nach Charismaeinstellung soll die Batterie so temperiert werden, dass die Systemleistung erreicht werden kann.
      frame HVK_03_SOK_XIX_HCP5_CANFD01: id 0xAF954C9, to BMC_HV, frame-length=12, can-addressing-mode=EXTENDED, can-frame-rx-behavior=CAN-FD, can-frame-tx-behavior=CAN-FD
        secured i pdu HVK_03_E2E_SOK_XIX_HCP5_CANFD01:
          length=12
          authentication-props=SecureCommunicationAuthenticationProps_XIX_32
          freshness-props=SecureCommunicationFreshnessProps
          payload=PT_HVK_03_E2E
          secure-communication-props={auth-data-freshness-length=0, auth-data-freshness-start-position=0, auth-info-tx-length=32, authentication-build-attempts=1, authentication-retries=4, data-id=715, freshness-value-id=1, freshness-value-length=64, freshness-value-tx-length=0}
          use-as-cryptographic-i-pdu=false
      frame HVLM_13_XIX_HCP5_CANFD01: id 0x271, to BMC_HV, frame-length=32, can-addressing-mode=STANDARD, can-frame-rx-behavior=CAN-FD, can-frame-tx-behavior=CAN-FD
        pdu HVLM_13_XIX_HCP5_CANFD01: length=32, minimum-delay=0.01, transmission-mode-true-timing={cyclic-timing={time-offset=0, time-period=0.1}, event-controlled-timing={number-of-repetitions=5, repetition-period=0}}, unused-bit-pattern=0
          signal HVLM_13_CRC_XIX_HVLM_13_XIX_HCP5_CANFD01: start 0, 8 bit, little-endian, data-type-policy=OVERRIDE, i-signal-type=PRIMITIVE, init-value=0, base-type=BT_HVLM_13_CRC, compu {phys=raw for raw 0..255}, range phys 0..255, raw 0..255, transfer-property=PENDING  # Für MLB: Berechnung siehe Lastenheft "Kommunikationsabsicherung für FlexRay und CAN" Ab MQB und MLBevo: Berechnung siehe Lastenheft "End-to-End Kommunikationsabsicherung" Endwerte siehe Begleitdokument "S-PDU Kennungsfolgen"
          signal HVLM_13_BZ_XIX_HVLM_13_XIX_HCP5_CANFD01: start 8, 4 bit, little-endian, data-type-policy=OVERRIDE, i-signal-type=PRIMITIVE, init-value=0, base-type=BT_HVLM_13_BZ, compu {phys=raw for raw 0..15}, range phys 0..15, raw 0..15, transfer-property=PENDING  # 4bit Botschaftszähler, wird mit jeder Sendebotschaft inkrementiert
          signal HVLM_Stecker_VerEntriegelnAnf_A_XIX_HVLM_13_XIX_HCP5_CANFD01: start 12, 2 bit, little-endian, data-type-policy=OVERRIDE, i-signal-type=PRIMITIVE, init-value=0, base-type=BT_HVLM_Stecker_VerEntriegelnAnf_A, compu {0=Cx0_keine_Anforderung (CM_HVLM_Stecker_VerEntriegelnAnf_A_Cx0_keine_Anforderung), 1=Cx1_Ladestecker_verriegeln (CM_HVLM_Stecker_VerEntriegelnAnf_A_Cx1_Ladestecker_verriegeln), 2=Cx2_Ladestecker_entriegeln (CM_HVLM_Stecker_VerEntriegelnAnf_A_Cx2_Ladestecker_entriegeln), 3=Cx3_reserve (CM_HVLM_Stecker_VerEntriegelnAnf_A_Cx3_reserve)}, range raw 0..3, transfer-property=TRIGGERED-ON-CHANGE-WITHOUT-REPETITION  # Anforderung Ladestecker zu verriegeln für Ladedose A
          signal HVLM_Stecker_VerEntriegelnAnf_B_XIX_HVLM_13_XIX_HCP5_CANFD01: start 14, 2 bit, little-endian, data-type-policy=OVERRIDE, i-signal-type=PRIMITIVE, init-value=0, base-type=BT_HVLM_Stecker_VerEntriegelnAnf_B, compu {0=Cx0_keine_Anforderung (CM_HVLM_Stecker_VerEntriegelnAnf_B_Cx0_keine_Anforderung), 1=Cx1_Ladestecker_verriegeln (CM_HVLM_Stecker_VerEntriegelnAnf_B_Cx1_Ladestecker_verriegeln), 2=Cx2_Ladestecker_entriegeln (CM_HVLM_Stecker_VerEntriegelnAnf_B_Cx2_Ladestecker_entriegeln), 3=Cx3_reserve (CM_HVLM_Stecker_VerEntriegelnAnf_B_Cx3_reserve)}, range raw 0..3, transfer-property=TRIGGERED-ON-CHANGE-WITHOUT-REPETITION  # Anforderung Ladestecker zu verriegeln für Ladedose B
          signal HVLM_DC_SollStrom_XIX_HVLM_13_XIX_HCP5_CANFD01: start 16, 11 bit, little-endian, data-type-policy=OVERRIDE, i-signal-type=PRIMITIVE, init-value=2046, base-type=BT_HVLM_DC_SollStrom, invalid-value=Invalid_HVLM_DC_SollStrom_XIX_HVLM_13_XIX_HCP5_CANFD01:2047, compu {phys=raw*0.1 for raw 0..1600, 2046=Cx7fe_Init (CM_HVLM_DC_SollStrom_Cx7fe_Init), 2047=Cx7ff_Fehler (CM_HVLM_DC_SollStrom_Cx7ff_Fehler); unit Unit_Amper}, range phys 0..160 Unit_Amper, raw 0..2047, unit=Unit_Amper, transfer-property=PENDING  # Sollstromanforderung für DC-Laden 0.. 160A
          signal HVLM_OBG_SollModus_XIX_HVLM_13_XIX_HCP5_CANFD01: start 27, 3 bit, little-endian, data-type-policy=OVERRIDE, i-signal-type=PRIMITIVE, init-value=0, base-type=BT_HVLM_OBG_SollModus, compu {0=Cx0_Standby (CM_HVLM_OBG_SollModus_Cx0_Standby), 1=Cx1_Netzladung_Anforderung (CM_HVLM_OBG_SollModus_Cx1_Netzladung_Anforderung), 2=Cx2_Rueckspeisung_solo (CM_HVLM_OBG_SollModus_Cx2_Rueckspeisung_solo), 3=Cx3_Rueckspeisung_grid (CM_HVLM_OBG_SollModus_Cx3_Rueckspeisung_grid), 4=Cx4_Vorladen_Anforderung (CM_HVLM_OBG_SollModus_Cx4_Vorladen_Anforderung)}, range raw 0..4, transfer-property=PENDING  # Anforderung des Sollmodus an das Ladegerät.
          signal HVLM_SF4OeffnenAnf_A_XIX_HVLM_13_XIX_HCP5_CANFD01: start 30, 1 bit, little-endian, data-type-policy=OVERRIDE, i-signal-type=PRIMITIVE, init-value=0, base-type=BT_HVLM_SF4OeffnenAnf_A, compu {0=Cx0_schliessen (CM_HVLM_SF4OeffnenAnf_A_Cx0_schliessen), 1=Cx1_oeffnen (CM_HVLM_SF4OeffnenAnf_A_Cx1_oeffnen)}, range raw 0..1, transfer-property=TRIGGERED-ON-CHANGE-WITHOUT-REPETITION  # Anforderung zum Öffnen/Schliessen des Schalters SF4 am ControlPilot Pin am Verbauort A 0= schliessen 1= oeffnen
          signal HVLM_SF4OeffnenAnf_B_XIX_HVLM_13_XIX_HCP5_CANFD01: start 31, 1 bit, little-endian, data-type-policy=OVERRIDE, i-signal-type=PRIMITIVE, init-value=0, base-type=BT_HVLM_SF4OeffnenAnf_B, compu {0=Cx0_schliessen (CM_HVLM_SF4OeffnenAnf_B_Cx0_schliessen), 1=Cx1_oeffnen (CM_HVLM_SF4OeffnenAnf_B_Cx1_oeffnen)}, range raw 0..1, transfer-property=TRIGGERED-ON-CHANGE-WITHOUT-REPETITION  # Anforderung zum Öffnen/Schliessen des Schalters SF4 am ControlPilot Pin am Verbauort B 0= schliessen 1= oeffnen
          signal HVLM_S2SchliessenAnf_A_XIX_HVLM_13_XIX_HCP5_CANFD01: start 32, 1 bit, little-endian, data-type-policy=OVERRIDE, i-signal-type=PRIMITIVE, init-value=0, base-type=BT_HVLM_S2SchliessenAnf_A, compu {0=Cx0_oeffnen (CM_HVLM_S2SchliessenAnf_A_Cx0_oeffnen), 1=Cx1_schliessen (CM_HVLM_S2SchliessenAnf_A_Cx1_schliessen)}, range raw 0..1, transfer-property=TRIGGERED-ON-CHANGE  # Anforderung zum Öffnen/Schliessen des Schalters S2 am ControlPilot Pin am Verbauort A 0= oeffnen 1= schliessen
          signal HVLM_S2SchliessenAnf_B_XIX_HVLM_13_XIX_HCP5_CANFD01: start 33, 1 bit, little-endian, data-type-policy=OVERRIDE, i-signal-type=PRIMITIVE, init-value=0, base-type=BT_HVLM_S2SchliessenAnf_B, compu {0=Cx0_oeffnen (CM_HVLM_S2SchliessenAnf_B_Cx0_oeffnen), 1=Cx1_schliessen (CM_HVLM_S2SchliessenAnf_B_Cx1_schliessen)}, range raw 0..1, transfer-property=TRIGGERED-ON-CHANGE  # Anforderung zum Öffnen/Schliessen des Schalters S2 am ControlPilot Pin am Verbauort B 0= oeffnen 1= schliessen
          signal HVLM_CP_Fehlerzustand_A_XIX_HVLM_13_XIX_HCP5_CANFD01: start 34, 3 bit, little-endian, data-type-policy=OVERRIDE, i-signal-type=PRIMITIVE, init-value=0, base-type=BT_HVLM_CP_Fehlerzustand_A, compu {0=Cx0_Init (CM_HVLM_CP_Fehlerzustand_A_Cx0_Init), 1=Cx1_kein_Fehler (CM_HVLM_CP_Fehlerzustand_A_Cx1_kein_Fehler), 2=Cx2_Spannung_niO (CM_HVLM_CP_Fehlerzustand_A_Cx2_Spannung_niO), 3=Cx3_Frequenz_niO (CM_HVLM_CP_Fehlerzustand_A_Cx3_Frequenz_niO), 4=Cx4_Tastgrad_niO (CM_HVLM_CP_Fehlerzustand_A_Cx4_Tastgrad_niO), 5=Cx5_State_niO (CM_HVLM_CP_Fehlerzustand_A_Cx5_State_niO)}, range raw 0..5, transfer-property=PENDING  # Fehler in der CP-Kommunikation
          signal HVLM_CP_Fehlerzustand_B_XIX_HVLM_13_XIX_HCP5_CANFD01: start 37, 3 bit, little-endian, data-type-policy=OVERRIDE, i-signal-type=PRIMITIVE, init-value=0, base-type=BT_HVLM_CP_Fehlerzustand_B, compu {0=Cx0_Init (CM_HVLM_CP_Fehlerzustand_B_Cx0_Init), 1=Cx1_kein_Fehler (CM_HVLM_CP_Fehlerzustand_B_Cx1_kein_Fehler), 2=Cx2_Spannung_niO (CM_HVLM_CP_Fehlerzustand_B_Cx2_Spannung_niO), 3=Cx3_Frequenz_niO (CM_HVLM_CP_Fehlerzustand_B_Cx3_Frequenz_niO), 4=Cx4_Tastgrad_niO (CM_HVLM_CP_Fehlerzustand_B_Cx4_Tastgrad_niO), 5=Cx5_State_niO (CM_HVLM_CP_Fehlerzustand_B_Cx5_State_niO)}, range raw 0..5, transfer-property=PENDING  # Fehler in der CP-Kommunikation
          signal HVLM_CP_MaxStrom_A_XIX_HVLM_13_XIX_HCP5_CANFD01: start 40, 10 bit, little-endian, data-type-policy=OVERRIDE, i-signal-type=PRIMITIVE, init-value=1022, base-type=BT_HVLM_CP_MaxStrom_A, compu {phys=raw*0.1 for raw 0..800, 1021=Cx3fd_nicht_bekannt (CM_HVLM_CP_MaxStrom_A_Cx3fd_nicht_bekannt), 1022=Cx3fe_Init (CM_HVLM_CP_MaxStrom_A_Cx3fe_Init); unit Unit_Amper}, range phys 0..80 Unit_Amper, raw 0..1022, unit=Unit_Amper, transfer-property=PENDING  # maximaler AC-Aufnahmestrom, durch die Ladesäule vorgegeben
          signal HVLM_CP_KommProtokoll_A_XIX_HVLM_13_XIX_HCP5_CANFD01: start 50, 2 bit, little-endian, data-type-policy=OVERRIDE, i-signal-type=PRIMITIVE, init-value=0, base-type=BT_HVLM_CP_KommProtokoll_A, compu {0=Cx0_Init (CM_HVLM_CP_KommProtokoll_A_Cx0_Init), 1=Cx1_Basis_PWM (CM_HVLM_CP_KommProtokoll_A_Cx1_Basis_PWM), 2=Cx2_HLC_Datenkommunikation (CM_HVLM_CP_KommProtokoll_A_Cx2_HLC_Datenkommunikation), 3=Cx3_unbekannt (CM_HVLM_CP_KommProtokoll_A_Cx3_unbekannt)}, range raw 0..3, transfer-property=PENDING  # Kommunikationsart vom CP signalisiert
          signal HVLM_CP_State_A_XIX_HVLM_13_XIX_HCP5_CANFD01: start 52, 4 bit, little-endian, data-type-policy=OVERRIDE, i-signal-type=PRIMITIVE, init-value=0, base-type=BT_HVLM_CP_State_A, compu {0=Cx0_Init (CM_HVLM_CP_State_A_Cx0_Init), 1=Cx1_A (CM_HVLM_CP_State_A_Cx1_A), 2=Cx2_B1 (CM_HVLM_CP_State_A_Cx2_B1), 3=Cx3_B2 (CM_HVLM_CP_State_A_Cx3_B2), 4=Cx4_C1 (CM_HVLM_CP_State_A_Cx4_C1), 5=Cx5_C2 (CM_HVLM_CP_State_A_Cx5_C2), 6=Cx6_E (CM_HVLM_CP_State_A_Cx6_E), 7=Cx7_F (CM_HVLM_CP_State_A_Cx7_F), 8=Cx8_kein_Zustand_erkannt (CM_HVLM_CP_State_A_Cx8_kein_Zustand_erkannt)}, range raw 0..8, transfer-property=PENDING  # Zustand der CP-Kommunikation der Ladedose A
          signal HVLM_CP_MaxStrom_B_XIX_HVLM_13_XIX_HCP5_CANFD01: start 56, 10 bit, little-endian, data-type-policy=OVERRIDE, i-signal-type=PRIMITIVE, init-value=1022, base-type=BT_HVLM_CP_MaxStrom_B, compu {phys=raw*0.1 for raw 0..800, 1021=Cx3fd_nicht_bekannt (CM_HVLM_CP_MaxStrom_B_Cx3fd_nicht_bekannt), 1022=Cx3fe_Init (CM_HVLM_CP_MaxStrom_B_Cx3fe_Init); unit Unit_Amper}, range phys 0..80 Unit_Amper, raw 0..1022, unit=Unit_Amper, transfer-property=PENDING  # maximaler AC-Aufnahmestrom, durch die Ladesäule vorgegeben
          signal HVLM_CP_KommProtokoll_B_XIX_HVLM_13_XIX_HCP5_CANFD01: start 66, 2 bit, little-endian, data-type-policy=OVERRIDE, i-signal-type=PRIMITIVE, init-value=0, base-type=BT_HVLM_CP_KommProtokoll_B, compu {0=Cx0_Init (CM_HVLM_CP_KommProtokoll_B_Cx0_Init), 1=Cx1_Basis_PWM (CM_HVLM_CP_KommProtokoll_B_Cx1_Basis_PWM), 2=Cx2_HLC_Datenkommunikation (CM_HVLM_CP_KommProtokoll_B_Cx2_HLC_Datenkommunikation), 3=Cx3_unbekannt (CM_HVLM_CP_KommProtokoll_B_Cx3_unbekannt)}, range raw 0..3, transfer-property=PENDING  # Kommunikationsart vom CP signalisiert
          signal HVLM_CP_State_B_XIX_HVLM_13_XIX_HCP5_CANFD01: start 68, 4 bit, little-endian, data-type-policy=OVERRIDE, i-signal-type=PRIMITIVE, init-value=0, base-type=BT_HVLM_CP_State_B, compu {0=Cx0_Init (CM_HVLM_CP_State_B_Cx0_Init), 1=Cx1_A (CM_HVLM_CP_State_B_Cx1_A), 2=Cx2_B1 (CM_HVLM_CP_State_B_Cx2_B1), 3=Cx3_B2 (CM_HVLM_CP_State_B_Cx3_B2), 4=Cx4_C1 (CM_HVLM_CP_State_B_Cx4_C1), 5=Cx5_C2 (CM_HVLM_CP_State_B_Cx5_C2), 6=Cx6_E (CM_HVLM_CP_State_B_Cx6_E), 7=Cx7_F (CM_HVLM_CP_State_B_Cx7_F), 8=Cx8_kein_Zustand_erkannt (CM_HVLM_CP_State_B_Cx8_kein_Zustand_erkannt)}, range raw 0..8, transfer-property=PENDING  # Zustand der CP-Kommunikation der Ladedose B
          signal HVLM_Max_Strom_Netz_L1_XIX_HVLM_13_XIX_HCP5_CANFD01: start 72, 10 bit, little-endian, data-type-policy=OVERRIDE, i-signal-type=PRIMITIVE, init-value=1022, base-type=BT_HVLM_Max_Strom_Netz_L1, invalid-value=Invalid_HVLM_Max_Strom_Netz_L1_XIX_HVLM_13_XIX_HCP5_CANFD01:1023, compu {phys=raw*0.1 for raw 0..630, 1022=Cx3fe_Init (CM_HVLM_Max_Strom_Netz_L1_Cx3fe_Init), 1023=Cx3ff_Fehler (CM_HVLM_Max_Strom_Netz_L1_Cx3ff_Fehler); unit Unit_Amper}, range phys 0..63 Unit_Amper, raw 0..1023, unit=Unit_Amper, transfer-property=PENDING  # Gibt den maximal zulässigen Aufnahmestrom aus der Infrastruktur auf L1 an.
          signal HVLM_Max_Strom_Netz_L2_XIX_HVLM_13_XIX_HCP5_CANFD01: start 82, 10 bit, little-endian, data-type-policy=OVERRIDE, i-signal-type=PRIMITIVE, init-value=1022, base-type=BT_HVLM_Max_Strom_Netz_L2, invalid-value=Invalid_HVLM_Max_Strom_Netz_L2_XIX_HVLM_13_XIX_HCP5_CANFD01:1023, compu {phys=raw*0.1 for raw 0..630, 1022=Cx3fe_Init (CM_HVLM_Max_Strom_Netz_L2_Cx3fe_Init), 1023=Cx3ff_Fehler (CM_HVLM_Max_Strom_Netz_L2_Cx3ff_Fehler); unit Unit_Amper}, range phys 0..63 Unit_Amper, raw 0..1023, unit=Unit_Amper, transfer-property=PENDING  # Gibt den maximal zulässigen Aufnahmestrom aus der Infrastruktur auf L2 an.
          signal HVLM_Max_Strom_Netz_L3_XIX_HVLM_13_XIX_HCP5_CANFD01: start 92, 10 bit, little-endian, data-type-policy=OVERRIDE, i-signal-type=PRIMITIVE, init-value=1022, base-type=BT_HVLM_Max_Strom_Netz_L3, invalid-value=Invalid_HVLM_Max_Strom_Netz_L3_XIX_HVLM_13_XIX_HCP5_CANFD01:1023, compu {phys=raw*0.1 for raw 0..630, 1022=Cx3fe_Init (CM_HVLM_Max_Strom_Netz_L3_Cx3fe_Init), 1023=Cx3ff_Fehler (CM_HVLM_Max_Strom_Netz_L3_Cx3ff_Fehler); unit Unit_Amper}, range phys 0..63 Unit_Amper, raw 0..1023, unit=Unit_Amper, transfer-property=PENDING  # Gibt den maximal zulässigen Aufnahmestrom aus der Infrastruktur auf L3 an.
          signal HVLM_MaxSpannung_OBG_HV_XIX_HVLM_13_XIX_HCP5_CANFD01: start 102, 10 bit, little-endian, data-type-policy=OVERRIDE, i-signal-type=PRIMITIVE, init-value=1022, base-type=BT_HVLM_MaxSpannung_OBG_HV, invalid-value=Invalid_HVLM_MaxSpannung_OBG_HV_XIX_HVLM_13_XIX_HCP5_CANFD01:1023, compu {phys=raw for raw 0..1021, 1022=Cx3fe_Init (CM_HVLM_MaxSpannung_OBG_HV_Cx3fe_Init), 1023=Cx3ff_Fehler (CM_HVLM_MaxSpannung_OBG_HV_Cx3ff_Fehler); unit Unit_Volt}, range phys 0..1021 Unit_Volt, raw 0..1023, unit=Unit_Volt, transfer-property=PENDING  # Maximal zulässige Ausgangsspannung des Onboardgleichrichters
          signal HVLM_Stecker_Notentriegeln_Anf_A_XIX_HVLM_13_XIX_HCP5_CANFD01: start 112, 2 bit, little-endian, data-type-policy=OVERRIDE, i-signal-type=PRIMITIVE, init-value=0, base-type=BT_HVLM_Stecker_Notentriegeln_Anf_A, compu {0=Cx0_Init (CM_HVLM_Stecker_Notentriegeln_Anf_A_Cx0_Init), 1=Cx1_keine_Notentriegelung (CM_HVLM_Stecker_Notentriegeln_Anf_A_Cx1_keine_Notentriegelung), 2=Cx2_Ladestecker_notentriegeln (CM_HVLM_Stecker_Notentriegeln_Anf_A_Cx2_Ladestecker_notentriegeln)}, range raw 0..2, transfer-property=TRIGGERED-ON-CHANGE-WITHOUT-REPETITION  # Anforderung zur Notentriegelung des Ladesteckers in Ladedose A
          signal HVLM_Stecker_Notentriegeln_Anf_B_XIX_HVLM_13_XIX_HCP5_CANFD01: start 114, 2 bit, little-endian, data-type-policy=OVERRIDE, i-signal-type=PRIMITIVE, init-value=0, base-type=BT_HVLM_Stecker_Notentriegeln_Anf_B, compu {0=Cx0_Init (CM_HVLM_Stecker_Notentriegeln_Anf_B_Cx0_Init), 1=Cx1_keine_Notentriegelung (CM_HVLM_Stecker_Notentriegeln_Anf_B_Cx1_keine_Notentriegelung), 2=Cx2_Ladestecker_notentriegeln (CM_HVLM_Stecker_Notentriegeln_Anf_B_Cx2_Ladestecker_notentriegeln)}, range raw 0..2, transfer-property=TRIGGERED-ON-CHANGE-WITHOUT-REPETITION  # Anforderung zur Notentriegelung des Ladesteckers in Ladedose B
          signal HVLM_Ladeklappe_VerEntriegeAnf_1_XIX_HVLM_13_XIX_HCP5_CANFD01: start 116, 2 bit, little-endian, data-type-policy=OVERRIDE, i-signal-type=PRIMITIVE, init-value=0, base-type=BT_HVLM_Ladeklappe_VerEntriegeAnf_1, compu {0=Cx0_Init (CM_HVLM_Ladeklappe_VerEntriegeAnf_1_Cx0_Init), 1=Cx1_Ladeklappe_verriegeln (CM_HVLM_Ladeklappe_VerEntriegeAnf_1_Cx1_Ladeklappe_verriegeln), 2=Cx2_Ladeklappe_entriegeln (CM_HVLM_Ladeklappe_VerEntriegeAnf_1_Cx2_Ladeklappe_entriegeln), 3=Cx3_keine_Anforderung (CM_HVLM_Ladeklappe_VerEntriegeAnf_1_Cx3_keine_Anforderung)}, range raw 0..3, transfer-property=TRIGGERED-ON-CHANGE-WITHOUT-REPETITION  # Anforderung die Ladeklappe der Ladedose 1 zu verriegeln oder zu entriegeln.
          signal HVLM_Ladeklappe_VerEntriegeAnf_2_XIX_HVLM_13_XIX_HCP5_CANFD01: start 118, 2 bit, little-endian, data-type-policy=OVERRIDE, i-signal-type=PRIMITIVE, init-value=0, base-type=BT_HVLM_Ladeklappe_VerEntriegeAnf_2, compu {0=Cx0_Init (CM_HVLM_Ladeklappe_VerEntriegeAnf_2_Cx0_Init), 1=Cx1_Ladeklappe_verriegeln (CM_HVLM_Ladeklappe_VerEntriegeAnf_2_Cx1_Ladeklappe_verriegeln), 2=Cx2_Ladeklappe_entriegeln (CM_HVLM_Ladeklappe_VerEntriegeAnf_2_Cx2_Ladeklappe_entriegeln), 3=Cx3_keine_Anforderung (CM_HVLM_Ladeklappe_VerEntriegeAnf_2_Cx3_keine_Anforderung)}, range raw 0..3, transfer-property=TRIGGERED-ON-CHANGE-WITHOUT-REPETITION  # Anforderung die Ladeklappe der Ladedose 2 zu verriegeln oder zu entriegeln.
          signal LVB_Ladegeschw_XIX_HVLM_13_XIX_HCP5_CANFD01: start 120, 13 bit, little-endian, data-type-policy=OVERRIDE, i-signal-type=PRIMITIVE, init-value=8190, base-type=BT_LVB_Ladegeschw, compu {phys=raw for raw 0..5000, 8190=Cx1ffe_Init (CM_LVB_Ladegeschw_Cx1ffe_Init); unit Unit_None}, range phys 0..5000 Unit_None, raw 0..8190, unit=Unit_None, transfer-property=PENDING  # Gibt die Geschwindigkeit des Ladevorgangs an. Einheit siehe Signal LVB_LadegeschwEinheit.
          signal LVB_LadegeschwEinheit_XIX_HVLM_13_XIX_HCP5_CANFD01: start 133, 3 bit, little-endian, data-type-policy=OVERRIDE, i-signal-type=PRIMITIVE, init-value=0, base-type=BT_LVB_LadegeschwEinheit, compu {0=Cx0_Init (CM_LVB_LadegeschwEinheit_Cx0_Init), 1=Cx1_Kilometer_pro_Minute (CM_LVB_LadegeschwEinheit_Cx1_Kilometer_pro_Minute), 2=Cx2_Kilometer_pro_Stunde (CM_LVB_LadegeschwEinheit_Cx2_Kilometer_pro_Stunde), 3=Cx3_Meilen_pro_Minute (CM_LVB_LadegeschwEinheit_Cx3_Meilen_pro_Minute), 4=Cx4_Meilen_pro_Stunde (CM_LVB_LadegeschwEinheit_Cx4_Meilen_pro_Stunde)}, range raw 0..4, transfer-property=PENDING  # Einheit der Ladegeschwindigkeit
          signal LVB_StatusLadegeschw_XIX_HVLM_13_XIX_HCP5_CANFD01: start 136, 2 bit, little-endian, data-type-policy=OVERRIDE, i-signal-type=PRIMITIVE, init-value=2, base-type=BT_LVB_StatusLadegeschw, compu {0=Cx0_calculating (CM_LVB_StatusLadegeschw_Cx0_calculating), 1=Cx1_valid (CM_LVB_StatusLadegeschw_Cx1_valid), 2=Cx2_invalid (CM_LVB_StatusLadegeschw_Cx2_invalid)}, range raw 0..2, transfer-property=PENDING  # Gibt Informationen über die Gültigkeit der Ladegeschwindigkeit.
          signal LVB_StatusRestladezeit_XIX_HVLM_13_XIX_HCP5_CANFD01: start 138, 2 bit, little-endian, data-type-policy=OVERRIDE, i-signal-type=PRIMITIVE, init-value=2, base-type=BT_LVB_StatusRestladezeit, compu {0=Cx0_calculating (CM_LVB_StatusRestladezeit_Cx0_calculating), 1=Cx1_valid (CM_LVB_StatusRestladezeit_Cx1_valid), 2=Cx2_invalid (CM_LVB_StatusRestladezeit_Cx2_invalid)}, range raw 0..2, transfer-property=PENDING  # Gibt Informationen über die Gültigkeit der Restladezeit.
          signal LVB_Restladezeit_XIX_HVLM_13_XIX_HCP5_CANFD01: start 140, 12 bit, little-endian, data-type-policy=OVERRIDE, i-signal-type=PRIMITIVE, init-value=4094, base-type=BT_LVB_Restladezeit, invalid-value=Invalid_LVB_Restladezeit_XIX_HVLM_13_XIX_HCP5_CANFD01:4095, compu {phys=raw for raw 0..3000, 4094=Cxffe_Init (CM_LVB_Restladezeit_Cxffe_Init), 4095=Cxfff_Fehler (CM_LVB_Restladezeit_Cxfff_Fehler); unit Unit_Minut}, range phys 0..3000 Unit_Minut, raw 0..4095, unit=Unit_Minut, transfer-property=PENDING  # Restladezeit des Ladevorgangs bis gewünschter Ladezustand erreicht ist.
          signal HVLM_LadedosenSuchlicht_XIX_HVLM_13_XIX_HCP5_CANFD01: start 152, 3 bit, little-endian, data-type-policy=OVERRIDE, i-signal-type=PRIMITIVE, init-value=0, base-type=BT_HVLM_LadedosenSuchlicht, compu {0=Cx0_Suchlicht_aus (CM_HVLM_LadedosenSuchlicht_Cx0_Suchlicht_aus), 1=Cx1_Suchlicht_an (CM_HVLM_LadedosenSuchlicht_Cx1_Suchlicht_an), 2=Cx2_Stecker_erkannt (CM_HVLM_LadedosenSuchlicht_Cx2_Stecker_erkannt)}, range raw 0..2, transfer-property=TRIGGERED-ON-CHANGE-WITHOUT-REPETITION  # Signal zur Ansteuerung des Suchlichtes in der Ladedose
          signal HVLM_VA_Sollmodus_XIX_HVLM_13_XIX_HCP5_CANFD01: start 155, 2 bit, little-endian, data-type-policy=OVERRIDE, i-signal-type=PRIMITIVE, init-value=0, base-type=BT_HVLM_VA_Sollmodus, compu {0=Cx0_Nicht_aktivieren (CM_HVLM_VA_Sollmodus_Cx0_Nicht_aktivieren), 1=Cx1_Aktivieren (CM_HVLM_VA_Sollmodus_Cx1_Aktivieren), 2=Cx2_Reserviert (CM_HVLM_VA_Sollmodus_Cx2_Reserviert), 3=Cx3_Reserviert (CM_HVLM_VA_Sollmodus_Cx3_Reserviert)}, range raw 0..3, transfer-property=TRIGGERED-ON-CHANGE-WITHOUT-REPETITION  # Anforderung des Sollmodus an die VA beim induktiven Laden
          signal LVB_Ladegeschw_VZ_XIX_HVLM_13_XIX_HCP5_CANFD01: start 157, 1 bit, little-endian, data-type-policy=OVERRIDE, i-signal-type=PRIMITIVE, init-value=1, base-type=BT_LVB_Ladegeschw_VZ, compu {0=Cx0_Wertebereich_positiv (CM_LVB_Ladegeschw_VZ_Cx0_Wertebereich_positiv), 1=Cx1_Wertebereich_negativ (CM_LVB_Ladegeschw_VZ_Cx1_Wertebereich_negativ)}, range raw 0..1, transfer-property=PENDING  # Vorzeichen Bit zur Wertebereichseinstellung des Signals LVB_Ladegeschw. Als Hilfsgröße zur Umschaltung in einen positiven oder negativen Wertebereich
          signal HVLM_SpannungsModusDc_Anf_XIX_HVLM_13_XIX_HCP5_CANFD01: start 158, 2 bit, little-endian, data-type-policy=OVERRIDE, i-signal-type=PRIMITIVE, init-value=0, base-type=BT_HVLM_SpannungsModusDc_Anf, compu {0=Cx0_Keine_Anforderung_DC_Laden_oder_Init (CM_HVLM_SpannungsModusDc_Anf_Cx0_Keine_Anforderung_DC_Laden_oder_Init) (Keine Anforderung DC-Laden oder Init), 1=Cx1_Anforderung_des_seriellen_Spannungsmodus_volle_Spannung (CM_HVLM_SpannungsModusDc_Anf_Cx1_Anforderung_des_seriellen_Spannungsmodus_volle_Spannung) (Anforderung des seriellen Spannungsmodus (volle Spannung)), 2=Cx2_Anforderung_des_parallelen_Spannungsmodus_halbe_Spannung (CM_HVLM_SpannungsModusDc_Anf_Cx2_Anforderung_des_parallelen_Spannungsmodus_halbe_Spannung) (Anforderung des parallelen Spannungsmodus (halbe Spannung))}, range raw 0..2, transfer-property=PENDING  # Art des angeforderten Spannungsmodus beim DC-Laden an den HVK mit dem das Fahrzeug geladen werden soll
          signal HVLM_GAFrequenz_XIX_HVLM_13_XIX_HCP5_CANFD01: start 160, 14 bit, little-endian, data-type-policy=OVERRIDE, i-signal-type=PRIMITIVE, init-value=16382, base-type=BT_HVLM_GAFrequenz, invalid-value=Invalid_HVLM_GAFrequenz_XIX_HVLM_13_XIX_HCP5_CANFD01:16383, compu {phys=raw*10 for raw 0..16380, 16381=Cx3ffd_keine_Angabe (CM_HVLM_GAFrequenz_Cx3ffd_keine_Angabe), 16382=Cx3ffe_Init (CM_HVLM_GAFrequenz_Cx3ffe_Init), 16383=Cx3fff_Fehler (CM_HVLM_GAFrequenz_Cx3fff_Fehler); unit Unit_Hertz}, range phys 0..163800 Unit_Hertz, raw 0..16383, unit=Unit_Hertz, transfer-property=TRIGGERED-ON-CHANGE-WITHOUT-REPETITION  # Gewünschte Übertragungsfrequenz der GA beim induktiven Laden
          signal HVLM_GASpulenstrom_XIX_HVLM_13_XIX_HCP5_CANFD01: start 174, 10 bit, little-endian, data-type-policy=OVERRIDE, i-signal-type=PRIMITIVE, init-value=1022, base-type=BT_HVLM_GASpulenstrom, invalid-value=Invalid_HVLM_GASpulenstrom_XIX_HVLM_13_XIX_HCP5_CANFD01:1023, compu {phys=raw*0.1 for raw 0..1020, 1021=Cx3fd_keine_Angabe (CM_HVLM_GASpulenstrom_Cx3fd_keine_Angabe), 1022=Cx3fe_Init (CM_HVLM_GASpulenstrom_Cx3fe_Init), 1023=Cx3ff_Fehler (CM_HVLM_GASpulenstrom_Cx3ff_Fehler); unit Unit_Amper}, range phys 0..102 Unit_Amper, raw 0..1023, unit=Unit_Amper, transfer-property=TRIGGERED-ON-CHANGE-WITHOUT-REPETITION  # Gewünschter Strom in der GA Spule beim induktiven Laden
          signal HVLM_VALeistungFzg_XIX_HVLM_13_XIX_HCP5_CANFD01: start 184, 12 bit, little-endian, data-type-policy=OVERRIDE, i-signal-type=PRIMITIVE, init-value=4094, base-type=BT_HVLM_VALeistungFzg, invalid-value=Invalid_HVLM_VALeistungFzg_XIX_HVLM_13_XIX_HCP5_CANFD01:4095, compu {phys=raw*10 for raw 0..4092, 4093=Cxffd_keine_Angabe (CM_HVLM_VALeistungFzg_Cxffd_keine_Angabe), 4094=Cxffe_Init (CM_HVLM_VALeistungFzg_Cxffe_Init), 4095=Cxfff_Fehler (CM_HVLM_VALeistungFzg_Cxfff_Fehler); unit Unit_Watt}, range phys 0..40920 Unit_Watt, raw 0..4095, unit=Unit_Watt, transfer-property=TRIGGERED-ON-CHANGE-WITHOUT-REPETITION  # Gewünschte Leistung am Gleichrichter VA beim induktiven Laden
          signal HVLM_VASpannungFzg_XIX_HVLM_13_XIX_HCP5_CANFD01: start 196, 10 bit, little-endian, data-type-policy=OVERRIDE, i-signal-type=PRIMITIVE, init-value=1022, base-type=BT_HVLM_VASpannungFzg, invalid-value=Invalid_HVLM_VASpannungFzg_XIX_HVLM_13_XIX_HCP5_CANFD01:1023, compu {phys=raw for raw 0..1020, 1021=Cx3fd_keine_Angabe (CM_HVLM_VASpannungFzg_Cx3fd_keine_Angabe), 1022=Cx3fe_Init (CM_HVLM_VASpannungFzg_Cx3fe_Init), 1023=Cx3ff_Fehler (CM_HVLM_VASpannungFzg_Cx3ff_Fehler); unit Unit_Volt}, range phys 0..1020 Unit_Volt, raw 0..1023, unit=Unit_Volt, transfer-property=TRIGGERED-ON-CHANGE-WITHOUT-REPETITION  # Sollspannung am DC Ausgang der VA
          signal HVLM_VAStromFzg_XIX_HVLM_13_XIX_HCP5_CANFD01: start 206, 10 bit, little-endian, data-type-policy=OVERRIDE, i-signal-type=PRIMITIVE, init-value=1022, base-type=BT_HVLM_VAStromFzg, invalid-value=Invalid_HVLM_VAStromFzg_XIX_HVLM_13_XIX_HCP5_CANFD01:1023, compu {phys=raw*0.1 for raw 0..1020, 1021=Cx3fd_keine_Angabe (CM_HVLM_VAStromFzg_Cx3fd_keine_Angabe), 1022=Cx3fe_Init (CM_HVLM_VAStromFzg_Cx3fe_Init), 1023=Cx3ff_Fehler (CM_HVLM_VAStromFzg_Cx3ff_Fehler); unit Unit_Amper}, range phys 0..102 Unit_Amper, raw 0..1023, unit=Unit_Amper, transfer-property=TRIGGERED-ON-CHANGE-WITHOUT-REPETITION  # Sollstrom am DC Ausgang der VA
          signal HVLM_Intensitaet_Lk3_XIX_HVLM_13_XIX_HCP5_CANFD01: start 216, 7 bit, little-endian, data-type-policy=OVERRIDE, i-signal-type=PRIMITIVE, init-value=126, base-type=BT_HVLM_Intensitaet_Lk3, invalid-value=Invalid_HVLM_Intensitaet_Lk3_XIX_HVLM_13_XIX_HCP5_CANFD01:127, compu {phys=raw for raw 0..100, 126=Cx7e_Init (CM_HVLM_Intensitaet_Lk3_Cx7e_Init), 127=Cx7f_Fehler (CM_HVLM_Intensitaet_Lk3_Cx7f_Fehler); unit Unit_PerCent}, range phys 0..100 Unit_PerCent, raw 0..127, unit=Unit_PerCent, transfer-property=TRIGGERED-ON-CHANGE-WITHOUT-REPETITION  # Über dieses Signal wird eine Information über die Beleuchtungsintensität an der LED der Ladeklappe 2 gesendet. Suffix 3 bezieht sich auf virtuelle Ladeklappe 3, welche die zweite Ladeklappe bei einer Ansteuerung beider Ladeklappen durch ein Steuergerät ist.
          signal HVLM_BidiLadeModus_XIX_HVLM_13_XIX_HCP5_CANFD01: start 224, 2 bit, little-endian, data-type-policy=OVERRIDE, i-signal-type=PRIMITIVE, init-value=0, base-type=BT_HVLM_BidiLadeModus, compu {0=Cx0_InitWert_kein_bidi_Laden (CM_HVLM_BidiLadeModus_Cx0_InitWert_kein_bidi_Laden), 1=Cx1_bidi_Laden_kleine_Leistung (CM_HVLM_BidiLadeModus_Cx1_bidi_Laden_kleine_Leistung), 2=Cx2_bidi_Laden_mittlere_Leistung (CM_HVLM_BidiLadeModus_Cx2_bidi_Laden_mittlere_Leistung)}, range raw 0..2, transfer-property=PENDING, to BMC_HV(timeout 1 s)  # Es signalisiert dass das bidirektionale Laden aktiv ist und ob mit kleiner oder mittlerer Leistung geladen wird. Bei aktivem bidirektionalen Laden kann das Fahrzeug sowohl entladen als auch geladen werden.
          signal HVLM_ALF_PosAnforderung_XIX_HVLM_13_XIX_HCP5_CANFD01: start 226, 3 bit, little-endian, data-type-policy=OVERRIDE, i-signal-type=PRIMITIVE, init-value=0, base-type=BT_HVLM_ALF_PosAnforderung, invalid-value=Invalid_HVLM_ALF_PosAnforderung_XIX_HVLM_13_XIX_HCP5_CANFD01:7, compu {0=Cx0_inaktiv (CM_HVLM_ALF_PosAnforderung_Cx0_inaktiv), 1=Cx1_Aktivierungsanforderung_ManuellesParken (CM_HVLM_ALF_PosAnforderung_Cx1_Aktivierungsanforderung_ManuellesParken), 2=Cx2_Aktivierungsanforderung_AssistiertesParken (CM_HVLM_ALF_PosAnforderung_Cx2_Aktivierungsanforderung_AssistiertesParken), 3=Cx3_Umschaltung_Nahbereich_ManuellesParken (CM_HVLM_ALF_PosAnforderung_Cx3_Umschaltung_Nahbereich_ManuellesParken), 7=Cx7_Fehler (CM_HVLM_ALF_PosAnforderung_Cx7_Fehler)}, range raw 0..7, transfer-property=TRIGGERED-ON-CHANGE-WITHOUT-REPETITION  # Anforderung des induktiven Ladesystems an die Parkfunktionen zur Aktivierung der Positionierung und Rückmeldung über den Status des Positionierungsvorgangs.
          signal HVLM_Ladeklappe_VerEntriegeAnf_3_XIX_HVLM_13_XIX_HCP5_CANFD01: start 229, 2 bit, little-endian, data-type-policy=OVERRIDE, i-signal-type=PRIMITIVE, init-value=0, base-type=BT_HVLM_Ladeklappe_VerEntriegeAnf_3, compu {0=Cx0_Init (CM_HVLM_Ladeklappe_VerEntriegeAnf_3_Cx0_Init), 1=Cx1_Ladeklappe_verriegeln (CM_HVLM_Ladeklappe_VerEntriegeAnf_3_Cx1_Ladeklappe_verriegeln), 2=Cx2_Ladeklappe_entriegeln (CM_HVLM_Ladeklappe_VerEntriegeAnf_3_Cx2_Ladeklappe_entriegeln), 3=Cx3_keine_Anforderung (CM_HVLM_Ladeklappe_VerEntriegeAnf_3_Cx3_keine_Anforderung)}, range raw 0..3, transfer-property=TRIGGERED-ON-CHANGE-WITHOUT-REPETITION  # Anforderung die Ladeklappe der Ladedose 2 zu verriegeln oder zu entriegeln. Suffix 3 bezieht sich auf virtuelle Ladeklappe 3, welche die zweite Ladeklappe bei einer Ansteuerung beider Ladeklappen durch ein Steuergerät ist.
          signal HVLM_ALF_AktiverLadeniveauwunsch_XIX_HVLM_13_XIX_HCP5_CANFD01: start 231, 1 bit, little-endian, data-type-policy=OVERRIDE, i-signal-type=PRIMITIVE, init-value=0, base-type=BT_HVLM_ALF_AktiverLadeniveauwunsch, compu {0=Cx0_Keine_Kundenanforderung (CM_HVLM_ALF_AktiverLadeniveauwunsch_Cx0_Keine_Kundenanforderung), 1=Cx1_Aktive_Kundenanforderung (CM_HVLM_ALF_AktiverLadeniveauwunsch_Cx1_Aktive_Kundenanforderung)}, range raw 0..1, transfer-property=PENDING  # Bestätigung des manuellen ALF Ladeniveauwunsches durch Kunden
          signal HVLM_ALF_Ladestatus_Niveau_XIX_HVLM_13_XIX_HCP5_CANFD01: start 232, 3 bit, little-endian, data-type-policy=OVERRIDE, i-signal-type=PRIMITIVE, init-value=6, base-type=BT_HVLM_ALF_Ladestatus_Niveau, invalid-value=Invalid_HVLM_ALF_Ladestatus_Niveau_XIX_HVLM_13_XIX_HCP5_CANFD01:7, compu {0=Cx0_Kein_Laden_aktiv (CM_HVLM_ALF_Ladestatus_Niveau_Cx0_Kein_Laden_aktiv), 1=Cx1_Ladestrom_aktiv (CM_HVLM_ALF_Ladestatus_Niveau_Cx1_Ladestrom_aktiv), 2=Cx2_Laden_pausiert (CM_HVLM_ALF_Ladestatus_Niveau_Cx2_Laden_pausiert), 3=Cx3_Objekterkennung_aktiv (CM_HVLM_ALF_Ladestatus_Niveau_Cx3_Objekterkennung_aktiv), 4=Cx4_Ladeniveau_herstellen (CM_HVLM_ALF_Ladestatus_Niveau_Cx4_Ladeniveau_herstellen), 6=Cx6_Init (CM_HVLM_ALF_Ladestatus_Niveau_Cx6_Init), 7=Cx7_Fehler (CM_HVLM_ALF_Ladestatus_Niveau_Cx7_Fehler)}, range raw 0..7, transfer-property=PENDING  # Genauer Status von "Laden Aktiv" an LC zur Unterscheidung von Ladepause, Ladestrom aktiv und Objektevent
          signal HVLM_ALF_PosStatus_XIX_HVLM_13_XIX_HCP5_CANFD01: start 235, 3 bit, little-endian, data-type-policy=OVERRIDE, i-signal-type=PRIMITIVE, init-value=0, base-type=BT_HVLM_ALF_PosStatus, invalid-value=Invalid_HVLM_ALF_PosStatus_XIX_HVLM_13_XIX_HCP5_CANFD01:7, compu {0=Cx0_Inaktiv (CM_HVLM_ALF_PosStatus_Cx0_Inaktiv), 1=Cx1_Ladebereich_nicht_erreicht (CM_HVLM_ALF_PosStatus_Cx1_Ladebereich_nicht_erreicht), 2=Cx2_Ladebereich_erreicht (CM_HVLM_ALF_PosStatus_Cx2_Ladebereich_erreicht), 7=Cx7_Fehler (CM_HVLM_ALF_PosStatus_Cx7_Fehler)}, range raw 0..7, transfer-property=TRIGGERED-ON-CHANGE-WITHOUT-REPETITION  # Rückmeldung der AWC-VA zum Status der Positionierung.
          signal HVLM_WLAN_Verbinden_XIX_HVLM_13_XIX_HCP5_CANFD01: start 238, 2 bit, little-endian, data-type-policy=OVERRIDE, i-signal-type=PRIMITIVE, init-value=0, base-type=BT_HVLM_WLAN_Verbinden, compu {0=Cx0_Nicht_Verbinden (CM_HVLM_WLAN_Verbinden_Cx0_Nicht_Verbinden), 1=Cx1_Verbinden (CM_HVLM_WLAN_Verbinden_Cx1_Verbinden), 2=Cx2_Reserviert (CM_HVLM_WLAN_Verbinden_Cx2_Reserviert), 3=Cx3_Reserviert (CM_HVLM_WLAN_Verbinden_Cx3_Reserviert)}, range raw 0..3, transfer-property=TRIGGERED-ON-CHANGE  # Anforderung zum Aufbau der WLAN Kommunikation
          signal HVLM_WLAN_Aktivieren_XIX_HVLM_13_XIX_HCP5_CANFD01: start 244, 1 bit, little-endian, data-type-policy=OVERRIDE, i-signal-type=PRIMITIVE, init-value=0, base-type=BT_HVLM_WLAN_Aktivieren, compu {0=Cx0_Nicht_aktivieren (CM_HVLM_WLAN_Aktivieren_Cx0_Nicht_aktivieren), 1=Cx1_Aktivieren (CM_HVLM_WLAN_Aktivieren_Cx1_Aktivieren)}, range raw 0..1, transfer-property=TRIGGERED-ON-CHANGE  # Anforderung zur Aktivierung des WLAN Moduls
          signal HVLM_ALF_PosLadeart_XIX_HVLM_13_XIX_HCP5_CANFD01: start 245, 3 bit, little-endian, data-type-policy=OVERRIDE, i-signal-type=PRIMITIVE, init-value=0, base-type=BT_HVLM_ALF_PosLadeart, invalid-value=Invalid_HVLM_ALF_PosLadeart_XIX_HVLM_13_XIX_HCP5_CANFD01:7, compu {0=Cx0_keine_ALF (CM_HVLM_ALF_PosLadeart_Cx0_keine_ALF), 1=Cx1_AWC (CM_HVLM_ALF_PosLadeart_Cx1_AWC), 2=Cx2_ACD_U (CM_HVLM_ALF_PosLadeart_Cx2_ACD_U) (ACD-U), 3=Cx3_ACD_S (CM_HVLM_ALF_PosLadeart_Cx3_ACD_S) (ACD-S), 7=Cx7_Fehler (CM_HVLM_ALF_PosLadeart_Cx7_Fehler)}, range raw 0..7, transfer-property=TRIGGERED-ON-CHANGE-WITHOUT-REPETITION  # Gibt an, für welche automatisierte Ladefunktion die Positionierung des Fahrzeugs vorgenommen werden soll (Auswahl entsprechend der verfügbaren automatisierten Ladearten)
          signal HVLM_Schluessel_Anfrage_XIX_HVLM_13_XIX_HCP5_CANFD01: start 248, 2 bit, little-endian, data-type-policy=OVERRIDE, i-signal-type=PRIMITIVE, init-value=0, base-type=BT_HVLM_Schluessel_Anfrage, compu {0=Cx0_Keine_Anfrage_Init (CM_HVLM_Schluessel_Anfrage_Cx0_Keine_Anfrage_Init), 1=Cx1_Suchanfrage_LKL_1_aktiv (CM_HVLM_Schluessel_Anfrage_Cx1_Suchanfrage_LKL_1_aktiv), 2=Cx2_Suchanfrage_LKL_2_aktiv (CM_HVLM_Schluessel_Anfrage_Cx2_Suchanfrage_LKL_2_aktiv), 3=Cx3_Reserve (CM_HVLM_Schluessel_Anfrage_Cx3_Reserve)}, range raw 0..3, transfer-property=PENDING  # Anforderung HVLM an BCM für Schlüsselsuche über Kessy
          signal HVLM_Stecker_Notentriegeln_Anf_C_XIX_HVLM_13_XIX_HCP5_CANFD01: start 250, 2 bit, little-endian, data-type-policy=OVERRIDE, i-signal-type=PRIMITIVE, init-value=0, base-type=BT_HVLM_Stecker_Notentriegeln_Anf_C, compu {0=Cx0_Init (CM_HVLM_Stecker_Notentriegeln_Anf_C_Cx0_Init), 1=Cx1_keine_Notentriegelung (CM_HVLM_Stecker_Notentriegeln_Anf_C_Cx1_keine_Notentriegelung), 2=Cx2_Ladestecker_notentriegeln (CM_HVLM_Stecker_Notentriegeln_Anf_C_Cx2_Ladestecker_notentriegeln)}, range raw 0..2, transfer-property=TRIGGERED-ON-CHANGE-WITHOUT-REPETITION  # Anforderung zur Notentriegelung des Ladesteckers in Ladedose C
          signal HVLM_Stecker_VerEntriegelnAnf_C_XIX_HVLM_13_XIX_HCP5_CANFD01: start 252, 2 bit, little-endian, data-type-policy=OVERRIDE, i-signal-type=PRIMITIVE, init-value=0, base-type=BT_HVLM_Stecker_VerEntriegelnAnf_C, compu {0=Cx0_keine_Anforderung (CM_HVLM_Stecker_VerEntriegelnAnf_C_Cx0_keine_Anforderung), 1=Cx1_Ladestecker_verriegeln (CM_HVLM_Stecker_VerEntriegelnAnf_C_Cx1_Ladestecker_verriegeln), 2=Cx2_Ladestecker_entriegeln (CM_HVLM_Stecker_VerEntriegelnAnf_C_Cx2_Ladestecker_entriegeln)}, range raw 0..2, transfer-property=TRIGGERED-ON-CHANGE-WITHOUT-REPETITION  # Anforderung Ladestecker zu verriegeln fuer Ladedose C
      frame HVLM_14_XIX_HCP5_CANFD01: id 0x272, to BMC_HV, frame-length=8, can-addressing-mode=STANDARD, can-frame-rx-behavior=CAN-FD, can-frame-tx-behavior=CAN-FD
        pdu HVLM_14_XIX_HCP5_CANFD01_E2E: length=8, minimum-delay=0.01, transmission-mode-true-timing=event-controlled-timing={number-of-repetitions=0, repetition-period=0}, unused-bit-pattern=0  # Fuer die Botschaft ist das Cyclic-Timing 0.1 zu verwenden.
          signal HVLM_14_CRC_XIX_HVLM_14_XIX_HCP5_CANFD01: start 0, 8 bit, little-endian, data-type-policy=OVERRIDE, i-signal-type=PRIMITIVE, init-value=0, base-type=BT_HVLM_14_CRC, compu {phys=raw for raw 0..255}, range phys 0..255, raw 0..255, to BMC_HV(timeout 1 s)
          signal HVLM_14_BZ_XIX_HVLM_14_XIX_HCP5_CANFD01: start 8, 4 bit, little-endian, data-type-policy=OVERRIDE, i-signal-type=PRIMITIVE, init-value=0, base-type=BT_HVLM_14_BZ, compu {phys=raw for raw 0..15}, range phys 0..15, raw 0..15, to BMC_HV(timeout 1 s)
          signal HVLM_Aktive_Ladeart_XIX_HVLM_14_XIX_HCP5_CANFD01: start 12, 3 bit, little-endian, data-type-policy=OVERRIDE, i-signal-type=PRIMITIVE, init-value=0, base-type=BT_HVLM_Aktive_Ladeart, invalid-value=Invalid_HVLM_Aktive_Ladeart_XIX_HVLM_14_XIX_HCP5_CANFD01:7, compu {0=Cx0_Kein_Laden_aktiv (CM_HVLM_Aktive_Ladeart_Cx0_Kein_Laden_aktiv), 1=Cx1_AC_Laden_aktiv (CM_HVLM_Aktive_Ladeart_Cx1_AC_Laden_aktiv), 2=Cx2_DC_Laden_aktiv (CM_HVLM_Aktive_Ladeart_Cx2_DC_Laden_aktiv), 3=Cx3_AWC (CM_HVLM_Aktive_Ladeart_Cx3_AWC), 4=Cx4_Reserve (CM_HVLM_Aktive_Ladeart_Cx4_Reserve), 5=Cx5_Reserve (CM_HVLM_Aktive_Ladeart_Cx5_Reserve), 6=Cx6_Reserve (CM_HVLM_Aktive_Ladeart_Cx6_Reserve), 7=Cx7_Fehler (CM_HVLM_Aktive_Ladeart_Cx7_Fehler)}, range raw 0..7  # informs about the used charging infrastructure - AC - DC - AWC.
          signal HVLM_Grundladen_Anf_XIX_HVLM_14_XIX_HCP5_CANFD01: start 15, 1 bit, little-endian, data-type-policy=OVERRIDE, i-signal-type=PRIMITIVE, init-value=0, base-type=BT_HVLM_Grundladen_Anf, compu {0=Cx0_Keine_Anforderung_Sofortladen (CM_HVLM_Grundladen_Anf_Cx0_Keine_Anforderung_Sofortladen), 1=Cx1_Sofortladen_Kundenwunsch (CM_HVLM_Grundladen_Anf_Cx1_Sofortladen_Kundenwunsch)}, range raw 0..1  # Anforderung des Grundladens
          signal ISignalVoid_HVLM_14_XIX_HCP5_CANFD01_0: start 16, 1 bit, little-endian, system signal SignalVoid_HVLM_14_0, data-type-policy=OVERRIDE, i-signal-type=PRIMITIVE, base-type=BT_SignalVoid
          signal HVLM_Pulsierstufe_XIX_HVLM_14_XIX_HCP5_CANFD01: start 17, 3 bit, little-endian, data-type-policy=OVERRIDE, i-signal-type=PRIMITIVE, init-value=0, base-type=BT_HVLM_Pulsierstufe, compu {0=Cx0_keine_Anforderung (CM_HVLM_Pulsierstufe_Cx0_keine_Anforderung), 1=Cx1_Stufe_0 (CM_HVLM_Pulsierstufe_Cx1_Stufe_0), 2=Cx2_Stufe_1 (CM_HVLM_Pulsierstufe_Cx2_Stufe_1), 3=Cx3_Stufe_2 (CM_HVLM_Pulsierstufe_Cx3_Stufe_2), 4=Cx4_Stufe_3 (CM_HVLM_Pulsierstufe_Cx4_Stufe_3), 5=Cx5_Stufe_4 (CM_HVLM_Pulsierstufe_Cx5_Stufe_4), 6=Cx6_Stufe_5 (CM_HVLM_Pulsierstufe_Cx6_Stufe_5), 7=Cx7_Stufe_6 (CM_HVLM_Pulsierstufe_Cx7_Stufe_6)}, range raw 0..7  # Über dieses Signal wird eine Information über die Frequenz der Ladedosen LED bei verschiedenen Leuchtmustern gesendet.
          signal HVLM_Intensitaet_Lk2_XIX_HVLM_14_XIX_HCP5_CANFD01: start 20, 7 bit, little-endian, data-type-policy=OVERRIDE, i-signal-type=PRIMITIVE, init-value=126, base-type=BT_HVLM_Intensitaet_Lk2, invalid-value=Invalid_HVLM_Intensitaet_Lk2_XIX_HVLM_14_XIX_HCP5_CANFD01:127, compu {phys=raw for raw 0..100, 126=Cx7e_Init (CM_HVLM_Intensitaet_Lk2_Cx7e_Init), 127=Cx7f_Fehler (CM_HVLM_Intensitaet_Lk2_Cx7f_Fehler); unit Unit_PerCent}, range phys 0..100 Unit_PerCent, raw 0..127, unit=Unit_PerCent  # Über dieses Signal wird eine Information über die Beleuchtungsintensität an der LED der Ladeklappe 2 gesendet.
          signal HVLM_PrkCtl_StAlyReq_XIX_HVLM_14_XIX_HCP5_CANFD01: start 27, 3 bit, little-endian, data-type-policy=OVERRIDE, i-signal-type=PRIMITIVE, init-value=6, base-type=BT_HVLM_PrkCtl_StAlyReq, invalid-value=Invalid_HVLM_PrkCtl_StAlyReq_XIX_HVLM_14_XIX_HCP5_CANFD01:7, compu {0=Cx0_NoReq (CM_HVLM_PrkCtl_StAlyReq_Cx0_NoReq), 1=Cx1_Park (CM_HVLM_PrkCtl_StAlyReq_Cx1_Park), 2=Cx2_ParkWithPPosn (CM_HVLM_PrkCtl_StAlyReq_Cx2_ParkWithPPosn), 3=Cx3_State3 (CM_HVLM_PrkCtl_StAlyReq_Cx3_State3), 4=Cx4_State4 (CM_HVLM_PrkCtl_StAlyReq_Cx4_State4), 5=Cx5_State5 (CM_HVLM_PrkCtl_StAlyReq_Cx5_State5), 6=Cx6_Init (CM_HVLM_PrkCtl_StAlyReq_Cx6_Init), 7=Cx7_Fehler (CM_HVLM_PrkCtl_StAlyReq_Cx7_Fehler)}, range raw 0..7  # Request to apply the park actuators.
          signal HVLM_PrkCtl_StPrkLockReq_XIX_HVLM_14_XIX_HCP5_CANFD01: start 30, 2 bit, little-endian, data-type-policy=OVERRIDE, i-signal-type=PRIMITIVE, init-value=2, base-type=BT_HVLM_PrkCtl_StPrkLockReq, invalid-value=Invalid_HVLM_PrkCtl_StPrkLockReq_XIX_HVLM_14_XIX_HCP5_CANFD01:3, compu {0=Cx0_NoReq (CM_HVLM_PrkCtl_StPrkLockReq_Cx0_NoReq), 1=Cx1_ParkLock (CM_HVLM_PrkCtl_StPrkLockReq_Cx1_ParkLock), 2=Cx2_Init (CM_HVLM_PrkCtl_StPrkLockReq_Cx2_Init), 3=Cx3_Fehler (CM_HVLM_PrkCtl_StPrkLockReq_Cx3_Fehler)}, range raw 0..3  # Request to keep the park aktuators locked in applied position if they are applied.
          signal HVLM_WakeUpZaehlerResetAnf_XIX_HVLM_14_XIX_HCP5_CANFD01: start 32, 1 bit, little-endian, data-type-policy=OVERRIDE, i-signal-type=PRIMITIVE, init-value=0, base-type=BT_HVLM_WakeUpZaehlerResetAnf, compu {0=Cx0_keine_Anforderung (CM_HVLM_WakeUpZaehlerResetAnf_Cx0_keine_Anforderung), 1=Cx1_Reset_Zaehler (CM_HVLM_WakeUpZaehlerResetAnf_Cx1_Reset_Zaehler)}, range raw 0..1  # Dieses Signal kann den Wakeup-Verhinderungszähler zurücksetzen
          signal ISignalVoid_HVLM_14_XIX_HCP5_CANFD01_1: start 33, 2 bit, little-endian, system signal SignalVoid_HVLM_14_1, data-type-policy=OVERRIDE, i-signal-type=PRIMITIVE, base-type=BT_SignalVoid
          signal HVLM_Steckerstatus_XIX_HVLM_14_XIX_HCP5_CANFD01: start 35, 2 bit, little-endian, data-type-policy=OVERRIDE, i-signal-type=PRIMITIVE, init-value=0, base-type=BT_HVLM_Steckerstatus, invalid-value=Invalid_HVLM_Steckerstatus_XIX_HVLM_14_XIX_HCP5_CANFD01:3, compu {0=Cx0_Init (CM_HVLM_Steckerstatus_Cx0_Init), 1=Cx1_kein_Stecker_erkannt (CM_HVLM_Steckerstatus_Cx1_kein_Stecker_erkannt), 2=Cx2_Stecker_erkannt (CM_HVLM_Steckerstatus_Cx2_Stecker_erkannt), 3=Cx3_Fehler (CM_HVLM_Steckerstatus_Cx3_Fehler)}, range raw 0..3, to BMC_HV(timeout 1 s)  # Stellt den Status eines Ladesteckers im Fahrzeug hinsichtlich Präsenz zur Verfügung
          signal HVLM_Ladeniveau_Anf_XIX_HVLM_14_XIX_HCP5_CANFD01: start 37, 3 bit, little-endian, data-type-policy=OVERRIDE, i-signal-type=PRIMITIVE, init-value=6, base-type=BT_HVLM_Ladeniveau_Anf, invalid-value=Invalid_HVLM_Ladeniveau_Anf_XIX_HVLM_14_XIX_HCP5_CANFD01:7, compu {0=Cx0_Keine_Ladeniveau_Anf (CM_HVLM_Ladeniveau_Anf_Cx0_Keine_Ladeniveau_Anf), 1=Cx1_Bevorsteh_Ladevorgang_erkannt (CM_HVLM_Ladeniveau_Anf_Cx1_Bevorsteh_Ladevorgang_erkannt), 2=Cx2_Ladeposition_wird_angefahren (CM_HVLM_Ladeniveau_Anf_Cx2_Ladeposition_wird_angefahren), 3=Cx3_Ladeposition_erreicht (CM_HVLM_Ladeniveau_Anf_Cx3_Ladeposition_erreicht), 4=Cx4_Ladevorgang_aktiv (CM_HVLM_Ladeniveau_Anf_Cx4_Ladevorgang_aktiv), 5=Cx5_Ladevorgang_abgeschlossen (CM_HVLM_Ladeniveau_Anf_Cx5_Ladevorgang_abgeschlossen), 6=Cx6_Init (CM_HVLM_Ladeniveau_Anf_Cx6_Init), 7=Cx7_Fehler (CM_HVLM_Ladeniveau_Anf_Cx7_Fehler)}, range raw 0..7  # Anforderung des HVLM an die Niveauregelung eine für das Laden spezifische Fahrzeughöhe einzustellen.
          signal HVLM_Ladenaktiv_Standzyklus_XIX_HVLM_14_XIX_HCP5_CANFD01: start 40, 1 bit, little-endian, data-type-policy=OVERRIDE, i-signal-type=PRIMITIVE, init-value=0, base-type=BT_HVLM_Ladenaktiv_Standzyklus, compu {0=Cx0_inaktiv (CM_HVLM_Ladenaktiv_Standzyklus_Cx0_inaktiv), 1=Cx1_aktiv (CM_HVLM_Ladenaktiv_Standzyklus_Cx1_aktiv)}, range raw 0..1  # Signalisiert ob im aktuellen Standzyklus (Fahrzeug wurde nicht bewegt) mindestens einmal HV-Ladevorgang stattgefunden hat.
          signal HVLM_Start_Pulserkennung_XIX_HVLM_14_XIX_HCP5_CANFD01: start 41, 1 bit, little-endian, data-type-policy=OVERRIDE, i-signal-type=PRIMITIVE, init-value=0, base-type=BT_HVLM_Start_Pulserkennung, compu {0=Cx0_keine_Anforderung (CM_HVLM_Start_Pulserkennung_Cx0_keine_Anforderung), 1=Cx1_Pulserkennung_starten (CM_HVLM_Start_Pulserkennung_Cx1_Pulserkennung_starten)}, range raw 0..1, to BMC_HV(timeout 1 s)  # Startanforderung für die Pulserkennung
          signal HVLM_ZustandLadeablauf_XIX_HVLM_14_XIX_HCP5_CANFD01: start 42, 4 bit, little-endian, data-type-policy=OVERRIDE, i-signal-type=PRIMITIVE, init-value=0, base-type=BT_HVLM_ZustandLadeablauf, invalid-value=Invalid_HVLM_ZustandLadeablauf_XIX_HVLM_14_XIX_HCP5_CANFD01:3, compu {0=Cx0_Init (CM_HVLM_ZustandLadeablauf_Cx0_Init), 1=Cx1_Stby_Ladevorbed_erfuellt (CM_HVLM_ZustandLadeablauf_Cx1_Stby_Ladevorbed_erfuellt), 2=Cx2_Stby_Ladevorbed_nicht_erfuellt (CM_HVLM_ZustandLadeablauf_Cx2_Stby_Ladevorbed_nicht_erfuellt), 3=Cx3_Fehler (CM_HVLM_ZustandLadeablauf_Cx3_Fehler), 4=Cx4_Laden_starten (CM_HVLM_ZustandLadeablauf_Cx4_Laden_starten), 5=Cx5_Laden_beenden (CM_HVLM_ZustandLadeablauf_Cx5_Laden_beenden), 6=Cx6_HVBatterie_Laden (CM_HVLM_ZustandLadeablauf_Cx6_HVBatterie_Laden), 7=Cx7_HVBatterie_Entladen (CM_HVLM_ZustandLadeablauf_Cx7_HVBatterie_Entladen), 8=Cx8_Erhaltungsladen (CM_HVLM_ZustandLadeablauf_Cx8_Erhaltungsladen)}, range raw 0..8, to BMC_HV(timeout 1 s)  # Zustand im Ablauf des Ladevorganges 0 = Init 1 = Standby_Ladevorbedingungen erfuellt 2 = Standby_Ladevorbedingungen_nicht_erfuellt 3 = Fehler 4 = Laden_starten 5 = Laden_beenden 6 = HVBatterie_Laden 7 = HVBatterie_Entladen 8 = Erhaltungsladen
          signal HVLM_DC_Aufstartmodus_XIX_HVLM_14_XIX_HCP5_CANFD01: start 46, 2 bit, little-endian, data-type-policy=OVERRIDE, i-signal-type=PRIMITIVE, init-value=0, base-type=BT_HVLM_DC_Aufstartmodus, compu {0=Cx0_keine_Anforderung (CM_HVLM_DC_Aufstartmodus_Cx0_keine_Anforderung), 1=Cx1_Angleich_Fahrzeug (CM_HVLM_DC_Aufstartmodus_Cx1_Angleich_Fahrzeug), 2=Cx2_Angleich_LS_1 (CM_HVLM_DC_Aufstartmodus_Cx2_Angleich_LS_1), 3=Cx3_Angleich_LS_2 (CM_HVLM_DC_Aufstartmodus_Cx3_Angleich_LS_2)}, range raw 0..3, to BMC_HV(timeout 1 s)  # Aufstartmodus zum Aktivieren des HV-Modus für DC-Laden
          signal HVLM_Ladeszenario_XIX_HVLM_14_XIX_HCP5_CANFD01: start 48, 5 bit, little-endian, data-type-policy=OVERRIDE, i-signal-type=PRIMITIVE, init-value=30, base-type=BT_HVLM_Ladeszenario, invalid-value=Invalid_HVLM_Ladeszenario_XIX_HVLM_14_XIX_HCP5_CANFD01:31, compu {0=Cx0_Aus (CM_HVLM_Ladeszenario_Cx0_Aus), 1=Cx1_Timerladen_abgeschlossen (CM_HVLM_Ladeszenario_Cx1_Timerladen_abgeschlossen), 2=Cx2_Sofortladen_abgeschlossen (CM_HVLM_Ladeszenario_Cx2_Sofortladen_abgeschlossen), 3=Cx3_Optimiertes_Laden_abgeschlossen (CM_HVLM_Ladeszenario_Cx3_Optimiertes_Laden_abgeschlossen), 4=Cx4_Timerladen_aktiv (CM_HVLM_Ladeszenario_Cx4_Timerladen_aktiv), 5=Cx5_Sofortladen_aktiv (CM_HVLM_Ladeszenario_Cx5_Sofortladen_aktiv), 6=Cx6_Optimiertes_Laden_aktiv (CM_HVLM_Ladeszenario_Cx6_Optimiertes_Laden_aktiv), 7=Cx7_Timerladen_warten (CM_HVLM_Ladeszenario_Cx7_Timerladen_warten), 8=Cx8_Optimiertes_Laden_warten (CM_HVLM_Ladeszenario_Cx8_Optimiertes_Laden_warten), 9=Cx9_Keine_Netzspannung (CM_HVLM_Ladeszenario_Cx9_Keine_Netzspannung), 10=Cxa_Fehler_Verriegelung (CM_HVLM_Ladeszenario_Cxa_Fehler_Verriegelung), 11=Cxb_Fehler_Ladesytem (CM_HVLM_Ladeszenario_Cxb_Fehler_Ladesytem), 12=Cxc_Init_Ladekommunikation (CM_HVLM_Ladeszenario_Cxc_Init_Ladekommunikation), 15=Cxf_Notladen (CM_HVLM_Ladeszenario_Cxf_Notladen), 16=Cx10_Ladeunterbrechung_Kunde (CM_HVLM_Ladeszenario_Cx10_Ladeunterbrechung_Kunde), 17=Cx11_Stecker_abziehbar (CM_HVLM_Ladeszenario_Cx11_Stecker_abziehbar), 18=Cx12_Kompatibilitaets_Umschaltung_aktiv (CM_HVLM_Ladeszenario_Cx12_Kompatibilitaets_Umschaltung_aktiv), 30=Cx1e_Init (CM_HVLM_Ladeszenario_Cx1e_Init), 31=Cx1f_Fehler (CM_HVLM_Ladeszenario_Cx1f_Fehler)}, range raw 0..31  # Über dieses Signal wird das einzustellende Szenario für die Visualisierung gesendet.
          signal HVLM_Ladevorgang_Anf_XIX_HVLM_14_XIX_HCP5_CANFD01: start 53, 3 bit, little-endian, data-type-policy=OVERRIDE, i-signal-type=PRIMITIVE, init-value=0, base-type=BT_HVLM_Ladevorgang_Anf, compu {0=Cx0_Laden_nicht_angefordert (CM_HVLM_Ladevorgang_Anf_Cx0_Laden_nicht_angefordert), 1=Cx1_AC_Laden_Angefordert (CM_HVLM_Ladevorgang_Anf_Cx1_AC_Laden_Angefordert), 2=Cx2_DC_Laden_Angefordert (CM_HVLM_Ladevorgang_Anf_Cx2_DC_Laden_Angefordert), 3=Cx3_AC_und_DC_Angefordert (CM_HVLM_Ladevorgang_Anf_Cx3_AC_und_DC_Angefordert), 4=Cx4_Induktiv_Laden_Angef (CM_HVLM_Ladevorgang_Anf_Cx4_Induktiv_Laden_Angef), 5=Cx5_AC_und_Induktiv_Angef (CM_HVLM_Ladevorgang_Anf_Cx5_AC_und_Induktiv_Angef), 6=Cx6_DC_und_Induktiv_Angef (CM_HVLM_Ladevorgang_Anf_Cx6_DC_und_Induktiv_Angef), 7=Cx7_AC_DC_und_Induktiv_Angef (CM_HVLM_Ladevorgang_Anf_Cx7_AC_DC_und_Induktiv_Angef)}, range raw 0..7  # Art der angeforderten Ladeart 0 = Laden_nicht_angefordert 1 = AC_Laden_Angefordert 2 = DC_Laden_Angefordert 3 = AC_und_DC_Angefordert 4 = Induktiv_Laden_Angef 5 = AC_und_Induktiv_Angef 6 = DC_und_Induktiv_Angef 7 = AC_DC_und_Induktiv_Angef
          signal HVLM_Intensitaet_Lk1_XIX_HVLM_14_XIX_HCP5_CANFD01: start 56, 7 bit, little-endian, data-type-policy=OVERRIDE, i-signal-type=PRIMITIVE, init-value=126, base-type=BT_HVLM_Intensitaet_Lk1, invalid-value=Invalid_HVLM_Intensitaet_Lk1_XIX_HVLM_14_XIX_HCP5_CANFD01:127, compu {phys=raw for raw 0..100, 126=Cx7e_Init (CM_HVLM_Intensitaet_Lk1_Cx7e_Init), 127=Cx7f_Fehler (CM_HVLM_Intensitaet_Lk1_Cx7f_Fehler); unit Unit_PerCent}, range phys 0..100 Unit_PerCent, raw 0..127, unit=Unit_PerCent  # Über dieses Signal wird eine Information über die Beleuchtungsintensität an der LED der Ladeklappe 1 gesendet.
          signal HVLM_Laden_ISO_Messung_Anf_XIX_HVLM_14_XIX_HCP5_CANFD01: start 63, 1 bit, little-endian, data-type-policy=OVERRIDE, i-signal-type=PRIMITIVE, init-value=1, base-type=BT_HVLM_Laden_ISO_Messung_Anf, compu {0=Cx0_Anforderung (CM_HVLM_Laden_ISO_Messung_Anf_Cx0_Anforderung), 1=Cx1_keine_Anforderung (CM_HVLM_Laden_ISO_Messung_Anf_Cx1_keine_Anforderung)}, range raw 0..1  # Messung des Isolationswiderstandes des Ladesystems (Fzg und Ladesäule) während des Ladevorganges durch das Fahrzeug 0= Anforderung 1= keine_Anforderung
          mapping SG_HVLM_14_XIX_HCP5_CANFD01: i-signal-group=SG_HVLM_14_XIX_HCP5_CANFD01, transfer-property=TRIGGERED-WITHOUT-REPETITION
      frame ISO_Funktionaler_Req_All_XIX_HCP5_CANFD01: id 0x700, to BMC_HV, frame-length=8, can-addressing-mode=STANDARD, can-frame-rx-behavior=CAN-FD, can-frame-tx-behavior=CAN-FD
        n pdu ISO_Funktionaler_Req_All_XIX_HCP5_CANFD01: length=8
      frame ISOx_Funkt_Req_All_FD_XIX_HCP5_CANFD01: id 0x1C410000, to BMC_HV, frame-length=64, can-addressing-mode=EXTENDED, can-frame-rx-behavior=CAN-FD, can-frame-tx-behavior=CAN-FD
        n pdu ISOx_Funkt_Req_All_FD_XIX_HCP5_CANFD01: length=64
      frame ISOx_Hybrid_01_Req_XIX_HCP5_CANFD01: id 0x17FC007B, to BMC_HV, frame-length=8, can-addressing-mode=EXTENDED, can-frame-rx-behavior=CAN-FD, can-frame-tx-behavior=CAN-FD
        n pdu ISOx_Hybrid_01_Req_XIX_HCP5_CANFD01: length=8
      frame ISOx_Hybrid_01_Req_FD_XIX_HCP5_CANFD01: id 0x1C40007B, to BMC_HV, frame-length=64, can-addressing-mode=EXTENDED, can-frame-rx-behavior=CAN-FD, can-frame-tx-behavior=CAN-FD
        n pdu ISOx_Hybrid_01_Req_FD_XIX_HCP5_CANFD01: length=64
      frame ISOx_Hybrid_01_Resp_XIX_HCP5_CANFD01: id 0x17FE007B, from BMC_HV, frame-length=8, can-addressing-mode=EXTENDED, can-frame-rx-behavior=CAN-FD, can-frame-tx-behavior=CAN-FD
        n pdu ISOx_Hybrid_01_Resp_XIX_HCP5_CANFD01: length=8
      frame ISOx_Hybrid_01_Resp_FD_XIX_HCP5_CANFD01: id 0x1C42007B, from BMC_HV, frame-length=64, can-addressing-mode=EXTENDED, can-frame-rx-behavior=CAN-FD, can-frame-tx-behavior=CAN-FD
        n pdu ISOx_Hybrid_01_Resp_FD_XIX_HCP5_CANFD01: length=64
      frame KN_Hybrid_01_XIX_HCP5_CANFD01: id 0x17F0007B, from BMC_HV, frame-length=16, can-addressing-mode=EXTENDED, can-frame-rx-behavior=CAN-FD, can-frame-tx-behavior=CAN-FD
        pdu KN_Hybrid_01_XIX_HCP5_CANFD01: length=16, transmission-mode-true-timing=cyclic-timing={time-offset=0, time-period=0.5}, unused-bit-pattern=0
          signal Hybrid_01_KompSchutz_XIX_KN_Hybrid_01_XIX_HCP5_CANFD01: start 0, 1 bit, little-endian, data-type-policy=OVERRIDE, i-signal-type=PRIMITIVE, init-value=0, base-type=BT_Hybrid_01_KompSchutz, compu {0=Cx0_KS_nicht_aktiv (CM_Hybrid_01_KompSchutz_Cx0_KS_nicht_aktiv), 1=Cx1_KS_sktiv (CM_Hybrid_01_KompSchutz_Cx1_KS_sktiv)}, range raw 0..1, transfer-property=PENDING  # Signal wird gesetzt wenn Komponentenschutz (KS) im Steuergerät aktiv ist.
          signal Hybrid_01_Abschaltstufe_XIX_KN_Hybrid_01_XIX_HCP5_CANFD01: start 1, 1 bit, little-endian, data-type-policy=OVERRIDE, i-signal-type=PRIMITIVE, init-value=0, base-type=BT_Hybrid_01_Abschaltstufe, compu {0=Cx0_keine_Einschraenkung (CM_Hybrid_01_Abschaltstufe_Cx0_keine_Einschraenkung), 1=Cx1_Funktionseinschraenkung (CM_Hybrid_01_Abschaltstufe_Cx1_Funktionseinschraenkung)}, range raw 0..1, transfer-property=PENDING  # Funktionseinschränkung aufgrund aktiver Abschaltstufe
          signal Hybrid_01_Transport_Mode_XIX_KN_Hybrid_01_XIX_HCP5_CANFD01: start 2, 1 bit, little-endian, data-type-policy=OVERRIDE, i-signal-type=PRIMITIVE, init-value=0, base-type=BT_Hybrid_01_Transport_Mode, compu {0=Cx0_keine_Einschraenkung (CM_Hybrid_01_Transport_Mode_Cx0_keine_Einschraenkung), 1=Cx1_Funktionseinschraenkung (CM_Hybrid_01_Transport_Mode_Cx1_Funktionseinschraenkung)}, range raw 0..1, transfer-property=PENDING  # Funktionseinschränkung aufgrund aktivem Transport Mode und/oder Transport Schutz
          signal Hybrid_01_Nachlauftyp_XIX_KN_Hybrid_01_XIX_HCP5_CANFD01: start 4, 4 bit, little-endian, data-type-policy=OVERRIDE, i-signal-type=PRIMITIVE, init-value=2, base-type=BT_Hybrid_01_Nachlauftyp, compu {0=Cx0_Komm_bei_KL15_EIN (CM_Hybrid_01_Nachlauftyp_Cx0_Komm_bei_KL15_EIN), 1=Cx1_Komm_nach_KL15_AUS (CM_Hybrid_01_Nachlauftyp_Cx1_Komm_nach_KL15_AUS), 2=Cx2_Komm_bei_KL15_AUS (CM_Hybrid_01_Nachlauftyp_Cx2_Komm_bei_KL15_AUS)}, range raw 0..2, transfer-property=PENDING  # Abgebildet wird die von der Hardware vorgegebene Möglichkeit, die Kommunikation nach Klemme 15 = AUS aufrecht zu erhalten. Es wird ein Init-Wert gesendet.
          signal Hybrid_01_SNI_10_XIX_KN_Hybrid_01_XIX_HCP5_CANFD01: start 8, 10 bit, little-endian, data-type-policy=OVERRIDE, i-signal-type=PRIMITIVE, init-value=123, base-type=BT_Hybrid_01_SNI_10, compu {phys=raw for raw 0..1023; unit Unit_None}, range phys 0..1023 Unit_None, raw 0..1023, unit=Unit_None, transfer-property=PENDING  # Source Node-Identifier (SNI) identifiziert den Sender der NM-Botschaft (Knotenadresse) eindeutig im Fahrzeug
          signal KN_Hybrid_01_ECUKnockOut_XIX_KN_Hybrid_01_XIX_HCP5_CANFD01: start 18, 2 bit, little-endian, data-type-policy=OVERRIDE, i-signal-type=PRIMITIVE, init-value=0, base-type=BT_KN_Hybrid_01_ECUKnockOut, compu {0=Cx0_Funktion_nicht_ausgeloest (CM_KN_Hybrid_01_ECUKnockOut_Cx0_Funktion_nicht_ausgeloest), 1=Cx1_Veto_war_aktiv (CM_KN_Hybrid_01_ECUKnockOut_Cx1_Veto_war_aktiv), 2=Cx2_Funktion_ausgeloest (CM_KN_Hybrid_01_ECUKnockOut_Cx2_Funktion_ausgeloest), 3=Cx3_Funktion_deaktiviert (CM_KN_Hybrid_01_ECUKnockOut_Cx3_Funktion_deaktiviert)}, range raw 0..3, transfer-property=PENDING  # Ausgabe des ECUKnockout-Status
          signal KN_Hybrid_01_DiagPfad_V12_XIX_KN_Hybrid_01_XIX_HCP5_CANFD01: start 20, 1 bit, little-endian, data-type-policy=OVERRIDE, i-signal-type=PRIMITIVE, init-value=0, base-type=BT_KN_Hybrid_01_DiagPfad_V12, compu {0=Cx0_Aktiv (CM_KN_Hybrid_01_DiagPfad_V12_Cx0_Aktiv), 1=Cx1_inaktiv (CM_KN_Hybrid_01_DiagPfad_V12_Cx1_inaktiv)}, range raw 0..1, transfer-property=PENDING  # Kennzeichnung der Diagnosefaehigkeit des BusInterfaces eines Steuergeraetes (Knoten) Umfang LAH 80127 Bei Nutzung des Signal explizit pro angebundenem BusInterface zu setzen
          signal NM_Hybrid_01_Lokalaktiv_XIX_KN_Hybrid_01_XIX_HCP5_CANFD01: start 21, 1 bit, little-endian, data-type-policy=OVERRIDE, i-signal-type=PRIMITIVE, init-value=0, base-type=BT_NM_Hybrid_01_Lokalaktiv, compu {0=Cx0_war_nicht_lokal_aktiv (CM_NM_Hybrid_01_Lokalaktiv_Cx0_war_nicht_lokal_aktiv), 1=Cx1_war_lokal_aktiv (CM_NM_Hybrid_01_Lokalaktiv_Cx1_war_lokal_aktiv)}, range raw 0..1, transfer-property=PENDING  # Zeigt an ob das SG nach Klemme15 AUS und nach entsprechender MAX Aktivzeit noch aktiv war.
          signal NM_Hybrid_01_Subsystemaktiv_XIX_KN_Hybrid_01_XIX_HCP5_CANFD01: start 22, 1 bit, little-endian, data-type-policy=OVERRIDE, i-signal-type=PRIMITIVE, init-value=0, base-type=BT_NM_Hybrid_01_Subsystemaktiv, compu {0=Cx0_war_nicht_lokal_aktiv (CM_NM_Hybrid_01_Subsystemaktiv_Cx0_war_nicht_lokal_aktiv), 1=Cx1_war_lokal_aktiv (CM_NM_Hybrid_01_Subsystemaktiv_Cx1_war_lokal_aktiv)}, range raw 0..1, transfer-property=PENDING  # Zeigt an ob ein Subsystem des SGs nach Klemme15 AUS und nach entsprechender MAX Aktivzeit noch aktiv war
          signal Hybrid_01_KD_Fehler_XIX_KN_Hybrid_01_XIX_HCP5_CANFD01: start 23, 1 bit, little-endian, data-type-policy=OVERRIDE, i-signal-type=PRIMITIVE, init-value=0, base-type=BT_Hybrid_01_KD_Fehler, compu {0=Cx0_Kein_KD_Fehler (CM_Hybrid_01_KD_Fehler_Cx0_Kein_KD_Fehler), 1=Cx1_KD_Fehler (CM_Hybrid_01_KD_Fehler_Cx1_KD_Fehler)}, range raw 0..1, transfer-property=PENDING  # Bei gesetztem Bit ist mindestens ein Kundendienstfehler eingetragen
          signal KN_Hybrid_01_ECUKnockOutTimer_XIX_KN_Hybrid_01_XIX_HCP5_CANFD01: start 24, 6 bit, little-endian, data-type-policy=OVERRIDE, i-signal-type=PRIMITIVE, init-value=15, base-type=BT_KN_Hybrid_01_ECUKnockOutTimer, compu {phys=raw for raw 0..62, 63=Cx3f_ECUKnockOut_deaktiviert (CM_KN_Hybrid_01_ECUKnockOutTimer_Cx3f_ECUKnockOut_deaktiviert)}, range phys 0..62, raw 0..63, transfer-property=PENDING  # Ausgabe des ECUKnockOut-Timer
          signal KN_Hybrid_01_BusKnockOut_XIX_KN_Hybrid_01_XIX_HCP5_CANFD01: start 30, 2 bit, little-endian, data-type-policy=OVERRIDE, i-signal-type=PRIMITIVE, init-value=0, base-type=BT_KN_Hybrid_01_BusKnockOut, compu {0=Cx0_Funktion_nicht_ausgeloest (CM_KN_Hybrid_01_BusKnockOut_Cx0_Funktion_nicht_ausgeloest), 1=Cx1_Veto_aktiv (CM_KN_Hybrid_01_BusKnockOut_Cx1_Veto_aktiv), 2=Cx2_Funktion_ausgeloest (CM_KN_Hybrid_01_BusKnockOut_Cx2_Funktion_ausgeloest), 3=Cx3_Funktion_deaktiviert (CM_KN_Hybrid_01_BusKnockOut_Cx3_Funktion_deaktiviert)}, range raw 0..3, transfer-property=PENDING  # Ausgabe des BusKnockout-Status
          signal KN_Hybrid_01_BusKnockOutTimer_XIX_KN_Hybrid_01_XIX_HCP5_CANFD01: start 32, 8 bit, little-endian, data-type-policy=OVERRIDE, i-signal-type=PRIMITIVE, init-value=15, base-type=BT_KN_Hybrid_01_BusKnockOutTimer, compu {phys=raw for raw 0..254, 255=Cxff_BusKnockOut_deaktiviert (CM_KN_Hybrid_01_BusKnockOutTimer_Cxff_BusKnockOut_deaktiviert)}, range phys 0..254, raw 0..255, transfer-property=PENDING  # Ausgabe des BusKnockOut-Timer
          signal NM_Hybrid_01_FCIB_XIX_KN_Hybrid_01_XIX_HCP5_CANFD01: start 40, 56 bit, opaque, data-type-policy=OVERRIDE, i-signal-type=ARRAY, init-value=[1, 0, 0, 34, 128, 0, 0], base-type=BT_NM_Hybrid_01_FCIB, compu {1=Cx1_01_CarWakeUp (CM_NM_Hybrid_01_FCIB_Cx1_01_CarWakeUp), 2=Cx2_02_Basefunction_Powertrain (CM_NM_Hybrid_01_FCIB_Cx2_02_Basefunction_Powertrain), 4=Cx4_03_Basefunction_Chassis (CM_NM_Hybrid_01_FCIB_Cx4_03_Basefunction_Chassis), 8=Cx8_04_Basefunction_DrivingAssistance (CM_NM_Hybrid_01_FCIB_Cx8_04_Basefunction_DrivingAssistance), 16=Cx10_05_Basefunction_Infotainment (CM_NM_Hybrid_01_FCIB_Cx10_05_Basefunction_Infotainment), 32=Cx20_06_Basefunction_ComfortLight (CM_NM_Hybrid_01_FCIB_Cx20_06_Basefunction_ComfortLight), 64=Cx40_07_Basefunction_CrossSection (CM_NM_Hybrid_01_FCIB_Cx40_07_Basefunction_CrossSection), 128=Cx80_08_Basefunction_Connectivity (CM_NM_Hybrid_01_FCIB_Cx80_08_Basefunction_Connectivity), 256=Cx100_09_reserved (CM_NM_Hybrid_01_FCIB_Cx100_09_reserved) (09_<reserved>), 512=Cx200_10_Powertrain (CM_NM_Hybrid_01_FCIB_Cx200_10_Powertrain), 1024=Cx400_11_Chassis (CM_NM_Hybrid_01_FCIB_Cx400_11_Chassis), 2048=Cx800_12_GearSelector (CM_NM_Hybrid_01_FCIB_Cx800_12_GearSelector), 4096=Cx1000_13_Airbag (CM_NM_Hybrid_01_FCIB_Cx1000_13_Airbag), 8192=Cx2000_14_InfotainmentExtensions (CM_NM_Hybrid_01_FCIB_Cx2000_14_InfotainmentExtensions), 16384=Cx4000_15_InstrumentclusterDisplay (CM_NM_Hybrid_01_FCIB_Cx4000_15_InstrumentclusterDisplay), 32768=Cx8000_16_InfotainmentDisplay (CM_NM_Hybrid_01_FCIB_Cx8000_16_InfotainmentDisplay), 65536=Cx10000_17_Audio (CM_NM_Hybrid_01_FCIB_Cx10000_17_Audio), 131072=Cx20000_18_VirtualSideMirrors (CM_NM_Hybrid_01_FCIB_Cx20000_18_VirtualSideMirrors), 262144=Cx40000_19_Doors_Hatches (CM_NM_Hybrid_01_FCIB_Cx40000_19_Doors_Hatches), 524288=Cx80000_20_OptionalComfort (CM_NM_Hybrid_01_FCIB_Cx80000_20_OptionalComfort), 1048576=Cx100000_21_AirSuspension (CM_NM_Hybrid_01_FCIB_Cx100000_21_AirSuspension), 2097152=Cx200000_22_ExteriorLights (CM_NM_Hybrid_01_FCIB_Cx200000_22_ExteriorLights), 4194304=Cx400000_23_Climate (CM_NM_Hybrid_01_FCIB_Cx400000_23_Climate), 8388608=Cx800000_24_ThermoManagement (CM_NM_Hybrid_01_FCIB_Cx800000_24_ThermoManagement), 16777216=Cx1000000_25_AccessSystemSensors (CM_NM_Hybrid_01_FCIB_Cx1000000_25_AccessSystemSensors), 33554432=Cx2000000_26_HighVoltage_Charging (CM_NM_Hybrid_01_FCIB_Cx2000000_26_HighVoltage_Charging), 67108864=Cx4000000_27_Timemaster_Timer (CM_NM_Hybrid_01_FCIB_Cx4000000_27_Timemaster_Timer), 134217728=Cx8000000_28_OnboardTester_DataCollector (CM_NM_Hybrid_01_FCIB_Cx8000000_28_OnboardTester_DataCollector), 268435456=Cx10000000_29_SteeringColumnLock (CM_NM_Hybrid_01_FCIB_Cx10000000_29_SteeringColumnLock), 536870912=Cx20000000_30_EnergyManagement (CM_NM_Hybrid_01_FCIB_Cx20000000_30_EnergyManagement), 1073741824=Cx40000000_31_MultifunctionalSteeringWheel (CM_NM_Hybrid_01_FCIB_Cx40000000_31_MultifunctionalSteeringWheel), 2147483648=Cx80000000_32_OnlineAccess (CM_NM_Hybrid_01_FCIB_Cx80000000_32_OnlineAccess), 4294967296=Cx100000000_33_ExternalWirelessCommunication (CM_NM_Hybrid_01_FCIB_Cx100000000_33_ExternalWirelessCommunication), 8589934592=Cx200000000_34_GPS_Localization (CM_NM_Hybrid_01_FCIB_Cx200000000_34_GPS_Localization), 17179869184=Cx400000000_35_ExteriorSound (CM_NM_Hybrid_01_FCIB_Cx400000000_35_ExteriorSound), 34359738368=Cx800000000_36_Preheater (CM_NM_Hybrid_01_FCIB_Cx800000000_36_Preheater), 68719476736=Cx1000000000_37_HighVoltage_WirelessChargingStation (CM_NM_Hybrid_01_FCIB_Cx1000000000_37_HighVoltage_WirelessChargingStation), 549755813888=Cx8000000000_40_Diagnosis_Energy (CM_NM_Hybrid_01_FCIB_Cx8000000000_40_Diagnosis_Energy), 550326239233=Cx8022000001_InitValueFCIB (CM_NM_Hybrid_01_FCIB_Cx8022000001_InitValueFCIB), 1099511627776=Cx10000000000_41_Diagnosis_Powertrain (CM_NM_Hybrid_01_FCIB_Cx10000000000_41_Diagnosis_Powertrain), 2199023255552=Cx20000000000_42_Diagnosis_FlexRay (CM_NM_Hybrid_01_FCIB_Cx20000000000_42_Diagnosis_FlexRay), 4398046511104=Cx40000000000_43_Diagnosis_DrivingAssistance (CM_NM_Hybrid_01_FCIB_Cx40000000000_43_Diagnosis_DrivingAssistance), 8796093022208=Cx80000000000_44_Diagnosis_Infotainment (CM_NM_Hybrid_01_FCIB_Cx80000000000_44_Diagnosis_Infotainment), 17592186044416=Cx100000000000_45_Diagnosis_Comfort (CM_NM_Hybrid_01_FCIB_Cx100000000000_45_Diagnosis_Comfort), 35184372088832=Cx200000000000_46_Diagnosis_Light (CM_NM_Hybrid_01_FCIB_Cx200000000000_46_Diagnosis_Light), 70368744177664=Cx400000000000_47_Diagnosis_ComfortLINs (CM_NM_Hybrid_01_FCIB_Cx400000000000_47_Diagnosis_ComfortLINs), 140737488355328=Cx800000000000_48_Diagnosis_ClimateTmeLINs (CM_NM_Hybrid_01_FCIB_Cx800000000000_48_Diagnosis_ClimateTmeLINs), 281474976710656=Cx1000000000000_49_reserved (CM_NM_Hybrid_01_FCIB_Cx1000000000000_49_reserved) (49_<reserved>), 4503599627370500.0=Cx10000000000000_53_Lock_Unlock (CM_NM_Hybrid_01_FCIB_Cx10000000000000_53_Lock_Unlock), 9007199254740990.0=Cx20000000000000_54_reserved (CM_NM_Hybrid_01_FCIB_Cx20000000000000_54_reserved) (54_<reserved>), 1.8014398509482e+16=Cx40000000000000_55_Dimming (CM_NM_Hybrid_01_FCIB_Cx40000000000000_55_Dimming), 3.6028797018964e+16=Cx80000000000000_56_ChargingStatus (CM_NM_Hybrid_01_FCIB_Cx80000000000000_56_ChargingStatus)}, range raw 1..36028797018963968, transfer-property=PENDING  # FCIB = Funktions-Cluster-Initialisierungs-Bits
      frame KS_Hybrid_01_Challenge_K_XIX_HCP5_CANFD01: id 0x1A5555D6, from BMC_HV, frame-length=12, can-addressing-mode=EXTENDED, can-frame-rx-behavior=CAN-FD, can-frame-tx-behavior=CAN-FD
        pdu KS_Hybrid_01_Challenge_K_XIX_HCP5_CANFD01: length=12, transmission-mode-true-timing=event-controlled-timing={number-of-repetitions=0, repetition-period=0}, unused-bit-pattern=0
          signal KS_Hybrid_01_ChK_SID_XIX_KS_Hybrid_01_Challenge_K_XIX_HCP5_CANFD01: start 0, 16 bit, little-endian, data-type-policy=OVERRIDE, i-signal-type=PRIMITIVE, init-value=0, base-type=BT_KS_Hybrid_01_ChK_SID, compu {phys=raw for raw 0..65535; unit Unit_None}, range phys 0..65535 Unit_None, raw 0..65535, unit=Unit_None  # KS: ServiceID Challenge_K
          signal KS_Hybrid_01_ChK_IKACtr_XIX_KS_Hybrid_01_Challenge_K_XIX_HCP5_CANFD01: start 16, 8 bit, little-endian, data-type-policy=OVERRIDE, i-signal-type=PRIMITIVE, init-value=0, base-type=BT_KS_Hybrid_01_ChK_IKACtr, compu {phys=raw for raw 0..255; unit Unit_None}, range phys 0..255 Unit_None, raw 0..255, unit=Unit_None  # KS: IKA-Counter zur Korrelation der Authentifikation
          signal KS_Hybrid_01_ChK_XIX_KS_Hybrid_01_Challenge_K_XIX_HCP5_CANFD01: start 24, 64 bit, opaque, data-type-policy=OVERRIDE, i-signal-type=ARRAY, init-value=8 x 0, base-type=BT_KS_Hybrid_01_ChK, compu {phys=raw for raw 0..1.84467440737096e+19; unit Unit_None}, range phys 0..18446744073709551615 Unit_None, raw 0..18446744073709551615, unit=Unit_None  # KS: Challenge/Zufallszahl KS-Slave
          mapping SG_KS_Hybrid_01_Challenge_K_XIX_HCP5_CANFD01: i-signal-group=SG_KS_Hybrid_01_Challenge_K_XIX_HCP5_CANFD01, transfer-property=TRIGGERED-WITHOUT-REPETITION
      frame KS_Hybrid_01_Challenge_M_XIX_HCP5_CANFD01: id 0x1A5555D7, to BMC_HV, frame-length=12, can-addressing-mode=EXTENDED, can-frame-rx-behavior=CAN-FD, can-frame-tx-behavior=CAN-FD
        pdu KS_Hybrid_01_Challenge_M_XIX_HCP5_CANFD01: length=12, transmission-mode-true-timing=event-controlled-timing={number-of-repetitions=0, repetition-period=0}, unused-bit-pattern=0
          signal KS_Hybrid_01_ChM_SID_XIX_KS_Hybrid_01_Challenge_M_XIX_HCP5_CANFD01: start 0, 16 bit, little-endian, data-type-policy=OVERRIDE, i-signal-type=PRIMITIVE, init-value=0, base-type=BT_KS_Hybrid_01_ChM_SID, compu {phys=raw for raw 0..65535; unit Unit_None}, range phys 0..65535 Unit_None, raw 0..65535, unit=Unit_None, to BMC_HV  # KS: ServiceID Challenge_M
          signal KS_Hybrid_01_ChM_IKACtr_XIX_KS_Hybrid_01_Challenge_M_XIX_HCP5_CANFD01: start 16, 8 bit, little-endian, data-type-policy=OVERRIDE, i-signal-type=PRIMITIVE, init-value=0, base-type=BT_KS_Hybrid_01_ChM_IKACtr, compu {phys=raw for raw 0..255; unit Unit_None}, range phys 0..255 Unit_None, raw 0..255, unit=Unit_None, to BMC_HV  # KS: IKA-Counter zur Korrelation der Authentifikation
          signal KS_Hybrid_01_ChM_XIX_KS_Hybrid_01_Challenge_M_XIX_HCP5_CANFD01: start 24, 64 bit, opaque, data-type-policy=OVERRIDE, i-signal-type=ARRAY, init-value=8 x 0, base-type=BT_KS_Hybrid_01_ChM, compu {phys=raw for raw 0..1.84467440737096e+19; unit Unit_None}, range phys 0..18446744073709551615 Unit_None, raw 0..18446744073709551615, unit=Unit_None, to BMC_HV  # KS: Challenge/Zufallszahl KS-Master
          mapping SG_KS_Hybrid_01_Challenge_M_XIX_HCP5_CANFD01: i-signal-group=SG_KS_Hybrid_01_Challenge_M_XIX_HCP5_CANFD01, transfer-property=TRIGGERED-WITHOUT-REPETITION
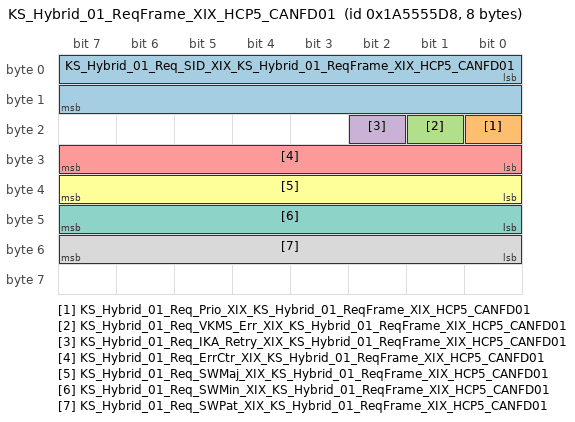
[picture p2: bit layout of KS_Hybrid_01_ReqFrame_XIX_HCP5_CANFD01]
      frame KS_Hybrid_01_ReqFrame_XIX_HCP5_CANFD01: id 0x1A5555D8, from BMC_HV, frame-length=8, can-addressing-mode=EXTENDED, can-frame-rx-behavior=CAN-FD, can-frame-tx-behavior=CAN-FD
        pdu KS_Hybrid_01_ReqFrame_XIX_HCP5_CANFD01: length=8, transmission-mode-true-timing=event-controlled-timing={number-of-repetitions=0, repetition-period=0}, unused-bit-pattern=0
          signal KS_Hybrid_01_Req_SID_XIX_KS_Hybrid_01_ReqFrame_XIX_HCP5_CANFD01: start 0, 16 bit, little-endian, data-type-policy=OVERRIDE, i-signal-type=PRIMITIVE, init-value=0, base-type=BT_KS_Hybrid_01_Req_SID, compu {phys=raw for raw 0..65535; unit Unit_None}, range phys 0..65535 Unit_None, raw 0..65535, unit=Unit_None  # KS: ServiceID Anfrage-Frame
          signal KS_Hybrid_01_Req_Prio_XIX_KS_Hybrid_01_ReqFrame_XIX_HCP5_CANFD01: start 16, 1 bit, little-endian, data-type-policy=OVERRIDE, i-signal-type=PRIMITIVE, init-value=0, base-type=BT_KS_Hybrid_01_Req_Prio, compu {0=Cx0_KS_Slave_wird_normal_authentifiziert (CM_KS_Hybrid_01_Req_Prio_Cx0_KS_Slave_wird_normal_authentifiziert) (KS-Slave wird normal authentifiziert), 1=Cx1_KS_Slave_fordert_priorisierte_Authentifikation (CM_KS_Hybrid_01_Req_Prio_Cx1_KS_Slave_fordert_priorisierte_Authentifikation) (KS-Slave fordert priorisierte Authentifikation)}, range raw 0..1  # KS: KS-Slave ist priorisiert
          signal KS_Hybrid_01_Req_VKMS_Err_XIX_KS_Hybrid_01_ReqFrame_XIX_HCP5_CANFD01: start 17, 1 bit, little-endian, data-type-policy=OVERRIDE, i-signal-type=PRIMITIVE, init-value=0, base-type=BT_KS_Hybrid_01_Req_VKMS_Err, compu {0=Cx0_Im_KS_Slave_liegt_kein_VKMS_Fehler_vor_VKMS_Type_Id_Ready_VKMS_ERR_NONE (CM_KS_Hybrid_01_Req_VKMS_Err_Cx0_Im_KS_Slave_liegt_kein_VKMS_Fehler_vor_VKMS_Type_Id_Ready_VKMS_ERR_NONE) (Im KS-Slave liegt kein VKMS Fehler vor (VKMS Type Id Ready = VKMS_ERR_NONE)), 1=Cx1_Im_KS_Slave_liegt_ein_VKMS_Fehler_vor_VKMS_Type_Id_Ready_VKMS_ERR_NONE (CM_KS_Hybrid_01_Req_VKMS_Err_Cx1_Im_KS_Slave_liegt_ein_VKMS_Fehler_vor_VKMS_Type_Id_Ready_VKMS_ERR_NONE) (Im KS-Slave liegt ein VKMS Fehler vor (VKMS Type Id Ready != VKMS_ERR_NONE))}, range raw 0..1  # KS: KS-Slave meldet VKMS-Fehler
          signal KS_Hybrid_01_Req_IKA_Retry_XIX_KS_Hybrid_01_ReqFrame_XIX_HCP5_CANFD01: start 18, 1 bit, little-endian, data-type-policy=OVERRIDE, i-signal-type=PRIMITIVE, init-value=0, base-type=BT_KS_Hybrid_01_Req_IKA_Retry, compu {0=Cx0_Erste_IKA_Anfrage_des_KS_Slave (CM_KS_Hybrid_01_Req_IKA_Retry_Cx0_Erste_IKA_Anfrage_des_KS_Slave) (Erste IKA-Anfrage des KS-Slave), 1=Cx1_Wiederholte_IKA_Anfrage_des_KS_Slave_AuthRetryCounter_0 (CM_KS_Hybrid_01_Req_IKA_Retry_Cx1_Wiederholte_IKA_Anfrage_des_KS_Slave_AuthRetryCounter_0) (Wiederholte IKA-Anfrage des KS-Slave (AuthRetryCounter > 0))}, range raw 0..1  # KS: KS-Slave fordert wiederholte IKS Anfrage an
          signal KS_Hybrid_01_Req_ErrCtr_XIX_KS_Hybrid_01_ReqFrame_XIX_HCP5_CANFD01: start 24, 8 bit, little-endian, data-type-policy=OVERRIDE, i-signal-type=PRIMITIVE, init-value=0, base-type=BT_KS_Hybrid_01_Req_ErrCtr, compu {phys=raw for raw 0..255; unit Unit_None}, range phys 0..255 Unit_None, raw 0..255, unit=Unit_None  # KS: Wert des KS-ErrorCounter im Secondary
          signal KS_Hybrid_01_Req_SWMaj_XIX_KS_Hybrid_01_ReqFrame_XIX_HCP5_CANFD01: start 32, 8 bit, little-endian, data-type-policy=OVERRIDE, i-signal-type=PRIMITIVE, init-value=0, base-type=BT_KS_Hybrid_01_Req_SWMaj, compu {phys=raw for raw 0..255; unit Unit_None}, range phys 0..255 Unit_None, raw 0..255, unit=Unit_None  # KS: SW-Version Major
          signal KS_Hybrid_01_Req_SWMin_XIX_KS_Hybrid_01_ReqFrame_XIX_HCP5_CANFD01: start 40, 8 bit, little-endian, data-type-policy=OVERRIDE, i-signal-type=PRIMITIVE, init-value=0, base-type=BT_KS_Hybrid_01_Req_SWMin, compu {phys=raw for raw 0..255; unit Unit_None}, range phys 0..255 Unit_None, raw 0..255, unit=Unit_None  # KS: SW-Version Minor
          signal KS_Hybrid_01_Req_SWPat_XIX_KS_Hybrid_01_ReqFrame_XIX_HCP5_CANFD01: start 48, 8 bit, little-endian, data-type-policy=OVERRIDE, i-signal-type=PRIMITIVE, init-value=0, base-type=BT_KS_Hybrid_01_Req_SWPat, compu {phys=raw for raw 0..255; unit Unit_None}, range phys 0..255 Unit_None, raw 0..255, unit=Unit_None  # KS: SW-Version Patch
          mapping SG_KS_Hybrid_01_ReqFrame_XIX_HCP5_CANFD01: i-signal-group=SG_KS_Hybrid_01_ReqFrame_XIX_HCP5_CANFD01, transfer-property=TRIGGERED-WITHOUT-REPETITION
      frame KS_Hybrid_01_Response_K_XIX_HCP5_CANFD01: id 0x1A5555D9, from BMC_HV, frame-length=12, can-addressing-mode=EXTENDED, can-frame-rx-behavior=CAN-FD, can-frame-tx-behavior=CAN-FD
        pdu KS_Hybrid_01_Response_K_XIX_HCP5_CANFD01: length=12, transmission-mode-true-timing=event-controlled-timing={number-of-repetitions=0, repetition-period=0}, unused-bit-pattern=0
          signal KS_Hybrid_01_ReK_SID_XIX_KS_Hybrid_01_Response_K_XIX_HCP5_CANFD01: start 0, 16 bit, little-endian, data-type-policy=OVERRIDE, i-signal-type=PRIMITIVE, init-value=0, base-type=BT_KS_Hybrid_01_ReK_SID, compu {phys=raw for raw 0..65535; unit Unit_None}, range phys 0..65535 Unit_None, raw 0..65535, unit=Unit_None  # KS: ServiceID Response_K
          signal KS_Hybrid_01_ReK_IKACtr_XIX_KS_Hybrid_01_Response_K_XIX_HCP5_CANFD01: start 16, 8 bit, little-endian, data-type-policy=OVERRIDE, i-signal-type=PRIMITIVE, init-value=0, base-type=BT_KS_Hybrid_01_ReK_IKACtr, compu {phys=raw for raw 0..255; unit Unit_None}, range phys 0..255 Unit_None, raw 0..255, unit=Unit_None  # KS: IKA-Counter zur Korrelation der Authentifikation
          signal KS_Hybrid_01_ReK_XIX_KS_Hybrid_01_Response_K_XIX_HCP5_CANFD01: start 24, 64 bit, opaque, data-type-policy=OVERRIDE, i-signal-type=ARRAY, init-value=8 x 0, base-type=BT_KS_Hybrid_01_ReK, compu {phys=raw for raw 0..1.84467440737096e+19; unit Unit_None}, range phys 0..18446744073709551615 Unit_None, raw 0..18446744073709551615, unit=Unit_None  # KS: Response KS-Slave Verschluesselung
          mapping SG_KS_Hybrid_01_Response_K_XIX_HCP5_CANFD01: i-signal-group=SG_KS_Hybrid_01_Response_K_XIX_HCP5_CANFD01, transfer-property=TRIGGERED-WITHOUT-REPETITION
      frame KS_Hybrid_01_Response_M_XIX_HCP5_CANFD01: id 0x1A5555DA, to BMC_HV, frame-length=12, can-addressing-mode=EXTENDED, can-frame-rx-behavior=CAN-FD, can-frame-tx-behavior=CAN-FD
        pdu KS_Hybrid_01_Response_M_XIX_HCP5_CANFD01: length=12, transmission-mode-true-timing=event-controlled-timing={number-of-repetitions=0, repetition-period=0}, unused-bit-pattern=0
          signal KS_Hybrid_01_ReM_SID_XIX_KS_Hybrid_01_Response_M_XIX_HCP5_CANFD01: start 0, 16 bit, little-endian, data-type-policy=OVERRIDE, i-signal-type=PRIMITIVE, init-value=0, base-type=BT_KS_Hybrid_01_ReM_SID, compu {phys=raw for raw 0..65535; unit Unit_None}, range phys 0..65535 Unit_None, raw 0..65535, unit=Unit_None, to BMC_HV  # KS: ServiceID Response_M
          signal KS_Hybrid_01_ReM_IKACtr_XIX_KS_Hybrid_01_Response_M_XIX_HCP5_CANFD01: start 16, 8 bit, little-endian, data-type-policy=OVERRIDE, i-signal-type=PRIMITIVE, init-value=0, base-type=BT_KS_Hybrid_01_ReM_IKACtr, compu {phys=raw for raw 0..255; unit Unit_None}, range phys 0..255 Unit_None, raw 0..255, unit=Unit_None, to BMC_HV  # KS: IKA-Counter zur Korrelation der Authentifikation
          signal KS_Hybrid_01_ReM_XIX_KS_Hybrid_01_Response_M_XIX_HCP5_CANFD01: start 24, 64 bit, opaque, data-type-policy=OVERRIDE, i-signal-type=ARRAY, init-value=8 x 0, base-type=BT_KS_Hybrid_01_ReM, compu {phys=raw for raw 0..1.84467440737096e+19; unit Unit_None}, range phys 0..18446744073709551615 Unit_None, raw 0..18446744073709551615, unit=Unit_None, to BMC_HV  # KS: Response KS-Master Verschluesselung
          mapping SG_KS_Hybrid_01_Response_M_XIX_HCP5_CANFD01: i-signal-group=SG_KS_Hybrid_01_Response_M_XIX_HCP5_CANFD01, transfer-property=TRIGGERED-WITHOUT-REPETITION
      frame NM_AWC_XIX_HCP5_CANFD01: id 0x1B00008F, to BMC_HV, frame-length=24, can-addressing-mode=EXTENDED, can-frame-rx-behavior=CAN-FD, can-frame-tx-behavior=CAN-FD, rx-identifier-range={lower-can-id=452984832, upper-can-id=452985855}
        nm pdu NM_AWC_XIX_HCP5_CANFD01: length=24, unused-bit-pattern=0
          signal NM_AWC_CBV_AWB_XIX_NM_AWC_XIX_HCP5_CANFD01: start 4, 1 bit, little-endian, data-type-policy=OVERRIDE, i-signal-type=PRIMITIVE, init-value=0, base-type=BT_NM_AWC_CBV_AWB, compu {0=Cx0_Passiver_WakeUp (CM_NM_AWC_CBV_AWB_Cx0_Passiver_WakeUp), 1=Cx1_Aktiver_WakeUp (CM_NM_AWC_CBV_AWB_Cx1_Aktiver_WakeUp)}, range raw 0..1, transfer-property=TRIGGERED  # Das Signal ist zu setzen, wenn das SG aktiv den Bus geweckt hat 0 = Passiver_WakeUp = SG hat das Netzwerk nicht aktiv geweckt 1 = Akitiver_WakeUp = SG hat das Netzwerk aktiv geweckt
          signal NM_AWC_CBV_CRI_XIX_NM_AWC_XIX_HCP5_CANFD01: start 6, 1 bit, little-endian, data-type-policy=OVERRIDE, i-signal-type=PRIMITIVE, init-value=1, base-type=BT_NM_AWC_CBV_CRI, compu {0=Cx0_NM_ohne_Clusteranforderungen (CM_NM_AWC_CBV_CRI_Cx0_NM_ohne_Clusteranforderungen), 1=Cx1_NM_mit_Clusteranforderungen (CM_NM_AWC_CBV_CRI_Cx1_NM_mit_Clusteranforderungen)}, range raw 0..1, transfer-property=TRIGGERED  # Das Signal ist dauerhaft gesetzt, wenn das NM-Layout Cluster- Anforderungen enthält
          signal NM_AWC_FCAB_XIX_NM_AWC_XIX_HCP5_CANFD01: start 8, 56 bit, opaque, data-type-policy=OVERRIDE, i-signal-type=ARRAY, init-value=7 x 0b00000000, base-type=BT_NM_AWC_FCAB, compu {0=Cx0_Init (CM_NM_AWC_FCAB_Cx0_Init), 1=Cx1_01_CarWakeUp (CM_NM_AWC_FCAB_Cx1_01_CarWakeUp), 2=Cx2_02_Basefunction_Powertrain (CM_NM_AWC_FCAB_Cx2_02_Basefunction_Powertrain), 4=Cx4_03_Basefunction_Chassis (CM_NM_AWC_FCAB_Cx4_03_Basefunction_Chassis), 8=Cx8_04_Basefunction_DrivingAssistance (CM_NM_AWC_FCAB_Cx8_04_Basefunction_DrivingAssistance), 16=Cx10_05_Basefunction_Infotainment (CM_NM_AWC_FCAB_Cx10_05_Basefunction_Infotainment), 32=Cx20_06_Basefunction_ComfortLight (CM_NM_AWC_FCAB_Cx20_06_Basefunction_ComfortLight), 64=Cx40_07_Basefunction_CrossSection (CM_NM_AWC_FCAB_Cx40_07_Basefunction_CrossSection), 128=Cx80_08_Basefunction_Connectivity (CM_NM_AWC_FCAB_Cx80_08_Basefunction_Connectivity), 256=Cx100_09_Basefunction_DrivingAssistanceCore (CM_NM_AWC_FCAB_Cx100_09_Basefunction_DrivingAssistanceCore), 512=Cx200_10_Powertrain (CM_NM_AWC_FCAB_Cx200_10_Powertrain), 1024=Cx400_11_Chassis (CM_NM_AWC_FCAB_Cx400_11_Chassis), 2048=Cx800_12_GearSelector (CM_NM_AWC_FCAB_Cx800_12_GearSelector), 4096=Cx1000_13_Airbag (CM_NM_AWC_FCAB_Cx1000_13_Airbag), 8192=Cx2000_14_InfotainmentExtensions (CM_NM_AWC_FCAB_Cx2000_14_InfotainmentExtensions), 16384=Cx4000_15_InstrumentclusterDisplay (CM_NM_AWC_FCAB_Cx4000_15_InstrumentclusterDisplay), 32768=Cx8000_16_InfotainmentDisplay (CM_NM_AWC_FCAB_Cx8000_16_InfotainmentDisplay), 65536=Cx10000_17_Audio (CM_NM_AWC_FCAB_Cx10000_17_Audio), 131072=Cx20000_18_VirtualSideMirrors (CM_NM_AWC_FCAB_Cx20000_18_VirtualSideMirrors), 262144=Cx40000_19_Doors_Hatches (CM_NM_AWC_FCAB_Cx40000_19_Doors_Hatches), 524288=Cx80000_20_OptionalComfort (CM_NM_AWC_FCAB_Cx80000_20_OptionalComfort), 1048576=Cx100000_21_AirSuspension (CM_NM_AWC_FCAB_Cx100000_21_AirSuspension), 2097152=Cx200000_22_ExteriorLights (CM_NM_AWC_FCAB_Cx200000_22_ExteriorLights), 4194304=Cx400000_23_Climate (CM_NM_AWC_FCAB_Cx400000_23_Climate), 8388608=Cx800000_24_ThermoManagement (CM_NM_AWC_FCAB_Cx800000_24_ThermoManagement), 16777216=Cx1000000_25_AccessSystemSensors (CM_NM_AWC_FCAB_Cx1000000_25_AccessSystemSensors), 33554432=Cx2000000_26_HighVoltage_Charging (CM_NM_AWC_FCAB_Cx2000000_26_HighVoltage_Charging), 67108864=Cx4000000_27_Timemaster_Timer (CM_NM_AWC_FCAB_Cx4000000_27_Timemaster_Timer), 134217728=Cx8000000_28_OnboardTester_DataCollector (CM_NM_AWC_FCAB_Cx8000000_28_OnboardTester_DataCollector), 268435456=Cx10000000_29_SteeringColumnLock (CM_NM_AWC_FCAB_Cx10000000_29_SteeringColumnLock), 536870912=Cx20000000_30_EnergyManagement (CM_NM_AWC_FCAB_Cx20000000_30_EnergyManagement), 1073741824=Cx40000000_31_MultifunctionalSteeringWheel (CM_NM_AWC_FCAB_Cx40000000_31_MultifunctionalSteeringWheel), 2147483648=Cx80000000_32_OnlineAccess (CM_NM_AWC_FCAB_Cx80000000_32_OnlineAccess), 4294967296=Cx100000000_33_ExternalWirelessCommunication (CM_NM_AWC_FCAB_Cx100000000_33_ExternalWirelessCommunication), 8589934592=Cx200000000_34_GPS_Localization (CM_NM_AWC_FCAB_Cx200000000_34_GPS_Localization), 17179869184=Cx400000000_35_ExteriorSound (CM_NM_AWC_FCAB_Cx400000000_35_ExteriorSound), 34359738368=Cx800000000_36_Preheater (CM_NM_AWC_FCAB_Cx800000000_36_Preheater), 68719476736=Cx1000000000_37_HighVoltage_WirelessChargingStation (CM_NM_AWC_FCAB_Cx1000000000_37_HighVoltage_WirelessChargingStation), 549755813888=Cx8000000000_40_Diagnosis_Energy (CM_NM_AWC_FCAB_Cx8000000000_40_Diagnosis_Energy), 1099511627776=Cx10000000000_41_Diagnosis_Powertrain (CM_NM_AWC_FCAB_Cx10000000000_41_Diagnosis_Powertrain), 2199023255552=Cx20000000000_42_Diagnosis_FlexRay (CM_NM_AWC_FCAB_Cx20000000000_42_Diagnosis_FlexRay), 4398046511104=Cx40000000000_43_Diagnosis_DrivingAssistance (CM_NM_AWC_FCAB_Cx40000000000_43_Diagnosis_DrivingAssistance), 8796093022208=Cx80000000000_44_Diagnosis_Infotainment (CM_NM_AWC_FCAB_Cx80000000000_44_Diagnosis_Infotainment), 17592186044416=Cx100000000000_45_Diagnosis_Comfort (CM_NM_AWC_FCAB_Cx100000000000_45_Diagnosis_Comfort), 35184372088832=Cx200000000000_46_Diagnosis_Light (CM_NM_AWC_FCAB_Cx200000000000_46_Diagnosis_Light), 70368744177664=Cx400000000000_47_Diagnosis_ComfortLINs (CM_NM_AWC_FCAB_Cx400000000000_47_Diagnosis_ComfortLINs), 140737488355328=Cx800000000000_48_Diagnosis_ClimateTmeLINs (CM_NM_AWC_FCAB_Cx800000000000_48_Diagnosis_ClimateTmeLINs), 281474976710656=Cx1000000000000_49_reserved (CM_NM_AWC_FCAB_Cx1000000000000_49_reserved) (49_<reserved>), 4503599627370500.0=Cx10000000000000_53_Lock_Unlock (CM_NM_AWC_FCAB_Cx10000000000000_53_Lock_Unlock), 9007199254740990.0=Cx20000000000000_54_reserved (CM_NM_AWC_FCAB_Cx20000000000000_54_reserved) (54_<reserved>), 1.8014398509482e+16=Cx40000000000000_55_Dimming (CM_NM_AWC_FCAB_Cx40000000000000_55_Dimming), 3.6028797018964e+16=Cx80000000000000_56_ChargingStatus (CM_NM_AWC_FCAB_Cx80000000000000_56_ChargingStatus)}, range raw 0..36028797018963968, transfer-property=TRIGGERED-ON-CHANGE, to BMC_HV(timeout 2 s)  # FCAB = Funktions-Cluster-Aktiv-Bits
          signal NM_AWC_SNI_10_XIX_NM_AWC_XIX_HCP5_CANFD01: start 128, 10 bit, little-endian, data-type-policy=OVERRIDE, i-signal-type=PRIMITIVE, init-value=143, base-type=BT_NM_AWC_SNI_10, compu {143=Cx8f_AWC_SNI (CM_NM_AWC_SNI_10_Cx8f_AWC_SNI)}, range raw 143, transfer-property=TRIGGERED  # Source Node-Identifier (SNI) identifiziert den Sender der NM-Botschaft (Knotenadresse) eindeutig im Fahrzeug
          signal NM_AWC_NM_State_XIX_NM_AWC_XIX_HCP5_CANFD01: start 144, 6 bit, little-endian, data-type-policy=OVERRIDE, i-signal-type=PRIMITIVE, init-value=0, base-type=BT_NM_AWC_NM_State, compu {0=Cx0_Init (CM_NM_AWC_NM_State_Cx0_Init), 1=Cx1_NM_RM_aus_BSM (CM_NM_AWC_NM_State_Cx1_NM_RM_aus_BSM), 2=Cx2_NM_RM_aus_PBSM (CM_NM_AWC_NM_State_Cx2_NM_RM_aus_PBSM), 4=Cx4_NM_NO_aus_RM (CM_NM_AWC_NM_State_Cx4_NM_NO_aus_RM), 8=Cx8_NM_NO_aus_RS (CM_NM_AWC_NM_State_Cx8_NM_NO_aus_RS), 16=Cx10_reserved (CM_NM_AWC_NM_State_Cx10_reserved), 32=Cx20_reserved (CM_NM_AWC_NM_State_Cx20_reserved)}, range raw 0..32, transfer-property=TRIGGERED  # 1 = Zustand Repeat Message (<-- Bus-Sleep Mode) 2 = Zustand Repeat Message (<-- Prepare Bus-Sleep Mode) 4 = Zustand Normal Operation (<-- Repeat Message) 8 = Zustand Normal Operation (<-- Ready Sleep)
          signal NM_AWC_UDS_CC_XIX_NM_AWC_XIX_HCP5_CANFD01: start 151, 1 bit, little-endian, data-type-policy=OVERRIDE, i-signal-type=PRIMITIVE, init-value=0, base-type=BT_NM_AWC_UDS_CC, compu {0=Cx0_Inaktiv (CM_NM_AWC_UDS_CC_Cx0_Inaktiv), 1=Cx1_CC_aktiv (CM_NM_AWC_UDS_CC_Cx1_CC_aktiv)}, range raw 0..1, transfer-property=TRIGGERED  # Funktionseinschränkung aufgrund aktivem UDS-Communication Control, siehe VW80124
          signal NM_AWC_Wakeup_V12_XIX_NM_AWC_XIX_HCP5_CANFD01: start 152, 8 bit, little-endian, data-type-policy=OVERRIDE, i-signal-type=PRIMITIVE, init-value=0, base-type=BT_NM_AWC_Wakeup_V12, compu {0=Cx0_Peripherie_Wakeup_Ursache_nicht_bekannt (CM_NM_AWC_Wakeup_V12_Cx0_Peripherie_Wakeup_Ursache_nicht_bekannt), 1=Cx1_Bus_Wakeup (CM_NM_AWC_Wakeup_V12_Cx1_Bus_Wakeup), 2=Cx2_KL15_HW (CM_NM_AWC_Wakeup_V12_Cx2_KL15_HW), 128=Cx80_RequestWirelessCharging (CM_NM_AWC_Wakeup_V12_Cx80_RequestWirelessCharging)}, range raw 0..128, transfer-property=TRIGGERED  # enthält die Weckursache; stehen mehrere Weckursachen parallel an, dann muss der kleinste Wert übertragen werden
          signal NM_AWC_NM_aktiv_KL15_XIX_NM_AWC_XIX_HCP5_CANFD01: start 160, 1 bit, little-endian, data-type-policy=OVERRIDE, i-signal-type=PRIMITIVE, init-value=0, base-type=BT_NM_AWC_NM_aktiv_KL15, compu {0=Cx0_Inaktiv (CM_NM_AWC_NM_aktiv_KL15_Cx0_Inaktiv), 1=Cx1_KL15_EIN (CM_NM_AWC_NM_aktiv_KL15_Cx1_KL15_EIN)}, range raw 0..1, transfer-property=TRIGGERED  # Steuergerät hat KL15-EIN erkannt
          signal NM_AWC_NM_aktiv_Diag_XIX_NM_AWC_XIX_HCP5_CANFD01: start 161, 1 bit, little-endian, data-type-policy=OVERRIDE, i-signal-type=PRIMITIVE, init-value=0, base-type=BT_NM_AWC_NM_aktiv_Diag, compu {0=Cx0_Inaktiv (CM_NM_AWC_NM_aktiv_Diag_Cx0_Inaktiv), 1=Cx1_Diagnose_aktiv (CM_NM_AWC_NM_aktiv_Diag_Cx1_Diagnose_aktiv)}, range raw 0..1, transfer-property=TRIGGERED  # Diagnose befindet sich nach VW80124 in einer NonDefaultDiagnostic-Session, z.B. ExtendedDiagnostic-Session
          signal NM_AWC_NM_aktiv_Tmin_XIX_NM_AWC_XIX_HCP5_CANFD01: start 162, 1 bit, little-endian, data-type-policy=OVERRIDE, i-signal-type=PRIMITIVE, init-value=0, base-type=BT_NM_AWC_NM_aktiv_Tmin, compu {0=Cx0_Inaktiv (CM_NM_AWC_NM_aktiv_Tmin_Cx0_Inaktiv), 1=Cx1_Mindestaktivzeit (CM_NM_AWC_NM_aktiv_Tmin_Cx1_Mindestaktivzeit)}, range raw 0..1, transfer-property=TRIGGERED  # Mindestaktivzeit ist noch nicht abgelaufen (bei jedem Weckereignis wird die Mindestaktivzeit neu gestartet)
          signal NM_aktiv_RequestWirelessCharging_XIX_NM_AWC_XIX_HCP5_CANFD01: start 163, 1 bit, little-endian, data-type-policy=OVERRIDE, i-signal-type=PRIMITIVE, init-value=0, base-type=BT_NM_aktiv_RequestWirelessCharging, compu {0=Cx0_Inaktiv (CM_NM_aktiv_RequestWirelessCharging_Cx0_Inaktiv), 1=Cx1_Aktiv (CM_NM_aktiv_RequestWirelessCharging_Cx1_Aktiv)}, range raw 0..1, transfer-property=TRIGGERED  # Das AWC muss den HVLM wecken um zu sagen, dass es Ladebereit wäre.
      frame NM_Gateway_XIX_HCP5_CANFD01: id 0x1B000010, to BMC_HV, frame-length=24, can-addressing-mode=EXTENDED, can-frame-rx-behavior=CAN-FD, can-frame-tx-behavior=CAN-FD, rx-identifier-range={lower-can-id=452984832, upper-can-id=452985855}
        nm pdu NM_Gateway_XIX_HCP5_CANFD01: length=24, unused-bit-pattern=0
          signal NM_Gateway_CBV_AWB_XIX_NM_Gateway_XIX_HCP5_CANFD01: start 4, 1 bit, little-endian, data-type-policy=OVERRIDE, i-signal-type=PRIMITIVE, init-value=0, base-type=BT_NM_Gateway_CBV_AWB, compu {0=Cx0_Passiver_WakeUp (CM_NM_Gateway_CBV_AWB_Cx0_Passiver_WakeUp), 1=Cx1_Aktiver_WakeUp (CM_NM_Gateway_CBV_AWB_Cx1_Aktiver_WakeUp)}, range raw 0..1, transfer-property=TRIGGERED  # Das Signal ist zu setzen, wenn das SG aktiv den Bus geweckt hat 0 = Passiver_WakeUp = SG hat das Netzwerk nicht aktiv geweckt 1 = Akitiver_WakeUp = SG hat das Netzwerk aktiv geweckt
          signal NM_Gateway_CBV_CRI_XIX_NM_Gateway_XIX_HCP5_CANFD01: start 6, 1 bit, little-endian, data-type-policy=OVERRIDE, i-signal-type=PRIMITIVE, init-value=1, base-type=BT_NM_Gateway_CBV_CRI, compu {0=Cx0_NM_ohne_Clusteranforderungen (CM_NM_Gateway_CBV_CRI_Cx0_NM_ohne_Clusteranforderungen), 1=Cx1_NM_mit_Clusteranforderungen (CM_NM_Gateway_CBV_CRI_Cx1_NM_mit_Clusteranforderungen)}, range raw 0..1, transfer-property=TRIGGERED  # Das Signal ist dauerhaft gesetzt, wenn das NM-Layout Cluster- Anforderungen enthält
          signal NM_Gateway_FCAB_XIX_NM_Gateway_XIX_HCP5_CANFD01: start 8, 56 bit, opaque, data-type-policy=OVERRIDE, i-signal-type=ARRAY, init-value=7 x 0b00000000, base-type=BT_NM_Gateway_FCAB, compu {0=Cx0_Init (CM_NM_Gateway_FCAB_Cx0_Init), 1=Cx1_01_CarWakeUp (CM_NM_Gateway_FCAB_Cx1_01_CarWakeUp), 2=Cx2_02_Basefunction_Powertrain (CM_NM_Gateway_FCAB_Cx2_02_Basefunction_Powertrain), 4=Cx4_03_Basefunction_Chassis (CM_NM_Gateway_FCAB_Cx4_03_Basefunction_Chassis), 8=Cx8_04_Basefunction_DrivingAssistance (CM_NM_Gateway_FCAB_Cx8_04_Basefunction_DrivingAssistance), 16=Cx10_05_Basefunction_Infotainment (CM_NM_Gateway_FCAB_Cx10_05_Basefunction_Infotainment), 32=Cx20_06_Basefunction_ComfortLight (CM_NM_Gateway_FCAB_Cx20_06_Basefunction_ComfortLight), 64=Cx40_07_Basefunction_CrossSection (CM_NM_Gateway_FCAB_Cx40_07_Basefunction_CrossSection), 128=Cx80_08_Basefunction_Connectivity (CM_NM_Gateway_FCAB_Cx80_08_Basefunction_Connectivity), 256=Cx100_09_Basefunction_DrivingAssistanceCore (CM_NM_Gateway_FCAB_Cx100_09_Basefunction_DrivingAssistanceCore), 512=Cx200_10_Powertrain (CM_NM_Gateway_FCAB_Cx200_10_Powertrain), 1024=Cx400_11_Chassis (CM_NM_Gateway_FCAB_Cx400_11_Chassis), 2048=Cx800_12_GearSelector (CM_NM_Gateway_FCAB_Cx800_12_GearSelector), 4096=Cx1000_13_Airbag (CM_NM_Gateway_FCAB_Cx1000_13_Airbag), 8192=Cx2000_14_InfotainmentExtensions (CM_NM_Gateway_FCAB_Cx2000_14_InfotainmentExtensions), 16384=Cx4000_15_InstrumentclusterDisplay (CM_NM_Gateway_FCAB_Cx4000_15_InstrumentclusterDisplay), 32768=Cx8000_16_InfotainmentDisplay (CM_NM_Gateway_FCAB_Cx8000_16_InfotainmentDisplay), 65536=Cx10000_17_Audio (CM_NM_Gateway_FCAB_Cx10000_17_Audio), 131072=Cx20000_18_VirtualSideMirrors (CM_NM_Gateway_FCAB_Cx20000_18_VirtualSideMirrors), 262144=Cx40000_19_Doors_Hatches (CM_NM_Gateway_FCAB_Cx40000_19_Doors_Hatches), 524288=Cx80000_20_OptionalComfort (CM_NM_Gateway_FCAB_Cx80000_20_OptionalComfort), 1048576=Cx100000_21_AirSuspension (CM_NM_Gateway_FCAB_Cx100000_21_AirSuspension), 2097152=Cx200000_22_ExteriorLights (CM_NM_Gateway_FCAB_Cx200000_22_ExteriorLights), 4194304=Cx400000_23_Climate (CM_NM_Gateway_FCAB_Cx400000_23_Climate), 8388608=Cx800000_24_ThermoManagement (CM_NM_Gateway_FCAB_Cx800000_24_ThermoManagement), 16777216=Cx1000000_25_AccessSystemSensors (CM_NM_Gateway_FCAB_Cx1000000_25_AccessSystemSensors), 33554432=Cx2000000_26_HighVoltage_Charging (CM_NM_Gateway_FCAB_Cx2000000_26_HighVoltage_Charging), 67108864=Cx4000000_27_Timemaster_Timer (CM_NM_Gateway_FCAB_Cx4000000_27_Timemaster_Timer), 134217728=Cx8000000_28_OnboardTester_DataCollector (CM_NM_Gateway_FCAB_Cx8000000_28_OnboardTester_DataCollector), 268435456=Cx10000000_29_SteeringColumnLock (CM_NM_Gateway_FCAB_Cx10000000_29_SteeringColumnLock), 536870912=Cx20000000_30_EnergyManagement (CM_NM_Gateway_FCAB_Cx20000000_30_EnergyManagement), 1073741824=Cx40000000_31_MultifunctionalSteeringWheel (CM_NM_Gateway_FCAB_Cx40000000_31_MultifunctionalSteeringWheel), 2147483648=Cx80000000_32_OnlineAccess (CM_NM_Gateway_FCAB_Cx80000000_32_OnlineAccess), 4294967296=Cx100000000_33_ExternalWirelessCommunication (CM_NM_Gateway_FCAB_Cx100000000_33_ExternalWirelessCommunication), 8589934592=Cx200000000_34_GPS_Localization (CM_NM_Gateway_FCAB_Cx200000000_34_GPS_Localization), 17179869184=Cx400000000_35_ExteriorSound (CM_NM_Gateway_FCAB_Cx400000000_35_ExteriorSound), 34359738368=Cx800000000_36_Preheater (CM_NM_Gateway_FCAB_Cx800000000_36_Preheater), 68719476736=Cx1000000000_37_HighVoltage_WirelessChargingStation (CM_NM_Gateway_FCAB_Cx1000000000_37_HighVoltage_WirelessChargingStation), 549755813888=Cx8000000000_40_Diagnosis_Energy (CM_NM_Gateway_FCAB_Cx8000000000_40_Diagnosis_Energy), 1099511627776=Cx10000000000_41_Diagnosis_Powertrain (CM_NM_Gateway_FCAB_Cx10000000000_41_Diagnosis_Powertrain), 2199023255552=Cx20000000000_42_Diagnosis_FlexRay (CM_NM_Gateway_FCAB_Cx20000000000_42_Diagnosis_FlexRay), 4398046511104=Cx40000000000_43_Diagnosis_DrivingAssistance (CM_NM_Gateway_FCAB_Cx40000000000_43_Diagnosis_DrivingAssistance), 8796093022208=Cx80000000000_44_Diagnosis_Infotainment (CM_NM_Gateway_FCAB_Cx80000000000_44_Diagnosis_Infotainment), 17592186044416=Cx100000000000_45_Diagnosis_Comfort (CM_NM_Gateway_FCAB_Cx100000000000_45_Diagnosis_Comfort), 35184372088832=Cx200000000000_46_Diagnosis_Light (CM_NM_Gateway_FCAB_Cx200000000000_46_Diagnosis_Light), 70368744177664=Cx400000000000_47_Diagnosis_ComfortLINs (CM_NM_Gateway_FCAB_Cx400000000000_47_Diagnosis_ComfortLINs), 140737488355328=Cx800000000000_48_Diagnosis_ClimateTmeLINs (CM_NM_Gateway_FCAB_Cx800000000000_48_Diagnosis_ClimateTmeLINs), 281474976710656=Cx1000000000000_49_reserved (CM_NM_Gateway_FCAB_Cx1000000000000_49_reserved) (49_<reserved>), 4503599627370500.0=Cx10000000000000_53_Lock_Unlock (CM_NM_Gateway_FCAB_Cx10000000000000_53_Lock_Unlock), 9007199254740990.0=Cx20000000000000_54_reserved (CM_NM_Gateway_FCAB_Cx20000000000000_54_reserved) (54_<reserved>), 1.8014398509482e+16=Cx40000000000000_55_Dimming (CM_NM_Gateway_FCAB_Cx40000000000000_55_Dimming), 3.6028797018964e+16=Cx80000000000000_56_ChargingStatus (CM_NM_Gateway_FCAB_Cx80000000000000_56_ChargingStatus)}, range raw 0..36028797018963968, transfer-property=TRIGGERED-ON-CHANGE, to BMC_HV(timeout 2 s)  # FCAB = Funktions-Cluster-Aktiv-Bits
          signal NM_aktiv_ConnectVerbund_UseCase1_XIX_NM_Gateway_XIX_HCP5_CANFD01: start 114, 1 bit, little-endian, data-type-policy=OVERRIDE, i-signal-type=PRIMITIVE, init-value=0, base-type=BT_NM_aktiv_ConnectVerbund_UseCase1, compu {0=Cx0_Inaktiv (CM_NM_aktiv_ConnectVerbund_UseCase1_Cx0_Inaktiv), 1=Cx1_Aktiv (CM_NM_aktiv_ConnectVerbund_UseCase1_Cx1_Aktiv)}, range raw 0..1, transfer-property=TRIGGERED  # Die Connect Steuergeräte HCP3, HCP5 und ConMod sind über einen zusätzlichen Wecknachlauf, inkl. Bus Kommunikation und Backend Verbindung aufgeweckt. Der Kunde hat davor die Funktion "Verlängerte Wachphase An" in der HCP3 Goodbye Screen bestätigt. Die Funktion hat Dauer und Max Werte Analog VoKo oder Prädektives VoKo Funktionalität und darf nur aktiv bleiben solange VoKo an ist (NM_aktiv_Scheibenheizung). Um diese Funktionalität zu ermöglichen sind bestehenden Funktionscluster zu steuern
          signal NM_aktiv_ConnectVerbund_UseCase2_XIX_NM_Gateway_XIX_HCP5_CANFD01: start 115, 1 bit, little-endian, data-type-policy=OVERRIDE, i-signal-type=PRIMITIVE, init-value=0, base-type=BT_NM_aktiv_ConnectVerbund_UseCase2, compu {0=Cx0_Inaktiv (CM_NM_aktiv_ConnectVerbund_UseCase2_Cx0_Inaktiv), 1=Cx1_Aktiv (CM_NM_aktiv_ConnectVerbund_UseCase2_Cx1_Aktiv)}, range raw 0..1, transfer-property=TRIGGERED  # Die Connect Steuergeräte HCP3, HCP5 und ConMod bleiben über einen zusätzlichen Wecknachlauf wach, inkl. Bus Kommunikation und Backend Verbindung wenn der Kunde die Funktion "Verlängerte Wachphase An" in der HU Goodbye Screen die Funktion bestätigt. Um diese Funktionalität zu ermöglichen sind bestehenden Funktionscluster zu steuern Die HVEM soll zwischen 5-10 Minuten nachlaufen damit die Connect Verbund die NVEM Batterie optimal ausnutzt
          signal NM_aktiv_ConnectVerbund_UseCase3_XIX_NM_Gateway_XIX_HCP5_CANFD01: start 116, 1 bit, little-endian, data-type-policy=OVERRIDE, i-signal-type=PRIMITIVE, init-value=0, base-type=BT_NM_aktiv_ConnectVerbund_UseCase3, compu {0=Cx0_Inaktiv (CM_NM_aktiv_ConnectVerbund_UseCase3_Cx0_Inaktiv), 1=Cx1_Aktiv (CM_NM_aktiv_ConnectVerbund_UseCase3_Cx1_Aktiv)}, range raw 0..1, transfer-property=TRIGGERED  # Die ORU Steuergeräte sind länger wach inkl. Bus Kommunikation und Backend Verbindung wenn der Kunde die Funktion in der HU Goodbye Screen die Funktion "Verlängerte Wachphase An" bestätigt hat. Flash Umfänge bei denen den HV-System aus sein muss, darf nicht länger als 30 Minuten ORU Flashzeit. Andere Umfänge dürfen längere ORU Flashzeit (bis 180 Minuten) anfodern. NM_aktivgrund verfügbar NM_aktiv_OnlineRemoteUpdate
          signal NM_aktiv_ConnectVerbund_UseCase4_XIX_NM_Gateway_XIX_HCP5_CANFD01: start 117, 1 bit, little-endian, data-type-policy=OVERRIDE, i-signal-type=PRIMITIVE, init-value=0, base-type=BT_NM_aktiv_ConnectVerbund_UseCase4, compu {0=Cx0_Inaktiv (CM_NM_aktiv_ConnectVerbund_UseCase4_Cx0_Inaktiv), 1=Cx1_Aktiv (CM_NM_aktiv_ConnectVerbund_UseCase4_Cx1_Aktiv)}, range raw 0..1, transfer-property=TRIGGERED  # Die Connect Steuergeräte HCP3, HCP5, HCP4 und ConMod werden geweckt und bleiben wach, inkl. Bus Kommunikation und Backend Verbindung wenn der Kunde die Funktion "Verlängerte Wachphase An" in der Head Unit Goodbye Screen bestätigt hat während das Fahrzeug am DC Ladesäule geladen wird. Um diese Funktionalität zu ermöglichen sind bestehenden Funktionscluster zu steuern
          signal NM_aktiv_ConnectVerbund_UseCase5_XIX_NM_Gateway_XIX_HCP5_CANFD01: start 118, 1 bit, little-endian, data-type-policy=OVERRIDE, i-signal-type=PRIMITIVE, init-value=0, base-type=BT_NM_aktiv_ConnectVerbund_UseCase5, compu {0=Cx0_Inaktiv (CM_NM_aktiv_ConnectVerbund_UseCase5_Cx0_Inaktiv), 1=Cx1_Aktiv (CM_NM_aktiv_ConnectVerbund_UseCase5_Cx1_Aktiv)}, range raw 0..1, transfer-property=TRIGGERED  # Die Connect Steuergeräte HCP3, HCP5 und ConMod sind über einen zusätzlichen Wecknachlauf, inkl. Bus Kommunikation und Backend Verbindung aufgeweckt. Der Kunde hat davor die Funktion "Verlängerte Wachphase An" in der HCP3 Goodbye Screen bestätigt. Um diese Funktionalität zu ermöglichen sind bestehenden Funktionscluster zu steuern
          signal NM_aktiv_ConnectVerbund_UseCase6_XIX_NM_Gateway_XIX_HCP5_CANFD01: start 119, 1 bit, little-endian, data-type-policy=OVERRIDE, i-signal-type=PRIMITIVE, init-value=0, base-type=BT_NM_aktiv_ConnectVerbund_UseCase6, compu {0=Cx0_Inaktiv (CM_NM_aktiv_ConnectVerbund_UseCase6_Cx0_Inaktiv), 1=Cx1_Aktiv (CM_NM_aktiv_ConnectVerbund_UseCase6_Cx1_Aktiv)}, range raw 0..1, transfer-property=TRIGGERED  # Die Connect Steuergeräte HCP3, HCP5 und ConMod sind über einen zusätzlichen Wecknachlauf, inkl. Bus Kommunikation und Backend Verbindung aufgeweckt während das Fahrzeug am AC Ladesäule geladen wird. Trigger ist eine Anfrage über die App/Backend ins Auto. Der Kunde hat davor die Funktion "Verlängerte Wachphase An" in der HCP3 Goodbye Screen bestätigt. Um diese Funktionalität zu ermöglichen sind bestehenden Funktionscluster zu steuern
          signal NM_aktiv_AutomotiveEdge_1_XIX_NM_Gateway_XIX_HCP5_CANFD01: start 120, 1 bit, little-endian, data-type-policy=OVERRIDE, i-signal-type=PRIMITIVE, init-value=0, base-type=BT_NM_aktiv_AutomotiveEdge_1, compu {0=Cx0_Inaktiv (CM_NM_aktiv_AutomotiveEdge_1_Cx0_Inaktiv), 1=Cx1_Aktiv (CM_NM_aktiv_AutomotiveEdge_1_Cx1_Aktiv)}, range raw 0..1, transfer-property=TRIGGERED  # Vorhalt VNSM_UsrId und NM-Aktivgrund-Signal für künftig möglichen Funktionshub ohne erforderlichen K-Matrix Update
          signal NM_aktiv_AutomotiveEdge_2_XIX_NM_Gateway_XIX_HCP5_CANFD01: start 121, 1 bit, little-endian, data-type-policy=OVERRIDE, i-signal-type=PRIMITIVE, init-value=0, base-type=BT_NM_aktiv_AutomotiveEdge_2, compu {0=Cx0_Inaktiv (CM_NM_aktiv_AutomotiveEdge_2_Cx0_Inaktiv), 1=Cx1_Aktiv (CM_NM_aktiv_AutomotiveEdge_2_Cx1_Aktiv)}, range raw 0..1, transfer-property=TRIGGERED  # Vorhalt VNSM_UsrId und NM-Aktivgrund-Signal für künftig möglichen Funktionshub ohne erforderlichen K-Matrix Update
          signal NM_aktiv_AutomotiveEdge_3_XIX_NM_Gateway_XIX_HCP5_CANFD01: start 122, 1 bit, little-endian, data-type-policy=OVERRIDE, i-signal-type=PRIMITIVE, init-value=0, base-type=BT_NM_aktiv_AutomotiveEdge_3, compu {0=Cx0_Inaktiv (CM_NM_aktiv_AutomotiveEdge_3_Cx0_Inaktiv), 1=Cx1_Aktiv (CM_NM_aktiv_AutomotiveEdge_3_Cx1_Aktiv)}, range raw 0..1, transfer-property=TRIGGERED  # Vorhalt VNSM_UsrId und NM-Aktivgrund-Signal für künftig möglichen Funktionshub ohne erforderlichen K-Matrix Update
          signal NM_aktiv_AutomotiveEdge_4_XIX_NM_Gateway_XIX_HCP5_CANFD01: start 123, 1 bit, little-endian, data-type-policy=OVERRIDE, i-signal-type=PRIMITIVE, init-value=0, base-type=BT_NM_aktiv_AutomotiveEdge_4, compu {0=Cx0_Inaktiv (CM_NM_aktiv_AutomotiveEdge_4_Cx0_Inaktiv), 1=Cx1_Aktiv (CM_NM_aktiv_AutomotiveEdge_4_Cx1_Aktiv)}, range raw 0..1, transfer-property=TRIGGERED  # Vorhalt VNSM_UsrId und NM-Aktivgrund-Signal für künftig möglichen Funktionshub ohne erforderlichen K-Matrix Update
          signal NM_aktiv_AutomotiveEdge_5_XIX_NM_Gateway_XIX_HCP5_CANFD01: start 124, 1 bit, little-endian, data-type-policy=OVERRIDE, i-signal-type=PRIMITIVE, init-value=0, base-type=BT_NM_aktiv_AutomotiveEdge_5, compu {0=Cx0_Inaktiv (CM_NM_aktiv_AutomotiveEdge_5_Cx0_Inaktiv), 1=Cx1_Aktiv (CM_NM_aktiv_AutomotiveEdge_5_Cx1_Aktiv)}, range raw 0..1, transfer-property=TRIGGERED  # Vorhalt VNSM_UsrId und NM-Aktivgrund-Signal für künftig möglichen Funktionshub ohne erforderlichen K-Matrix Update
          signal NM_aktiv_MVEM_Fremdladung_XIX_NM_Gateway_XIX_HCP5_CANFD01: start 125, 1 bit, little-endian, data-type-policy=OVERRIDE, i-signal-type=PRIMITIVE, init-value=0, base-type=BT_NM_aktiv_MVEM_Fremdladung, compu {0=Cx0_Inaktiv (CM_NM_aktiv_MVEM_Fremdladung_Cx0_Inaktiv), 1=Cx1_Aktiv (CM_NM_aktiv_MVEM_Fremdladung_Cx1_Aktiv)}, range raw 0..1, transfer-property=TRIGGERED  # Nach Ausschalten der Kl.15 soll bei 12V-Fremdladungsfreigabe durch das NvEM das MV-Netz noch aktiv gehalten werden oder bei ausgeschalteter Kl.15 aktiviert werden, dazu muss der HCP5 wach sein, der DcDc-Wandler und das BMS mit den jeweiligen Bussen. - 12V-Fremdladung (Fremdladegerät an der 12V-Batterie), damit die 48V-Batterie über den DcDc-Wandler noch geladen werden kann => wachhalten/aufwecken
          signal NM_aktiv_Konditionierung_Track_XIX_NM_Gateway_XIX_HCP5_CANFD01: start 126, 1 bit, little-endian, data-type-policy=OVERRIDE, i-signal-type=PRIMITIVE, init-value=0, base-type=BT_NM_aktiv_Konditionierung_Track, compu {0=Cx0_Inaktiv (CM_NM_aktiv_Konditionierung_Track_Cx0_Inaktiv), 1=Cx1_Aktiv (CM_NM_aktiv_Konditionierung_Track_Cx1_Aktiv)}, range raw 0..1, transfer-property=TRIGGERED  # Ist die Teilfunktion "Vorkonditionierung" der Funktion Make Me Track Ready (MMTR) aktiv und das Fahrzeug wird dann abgestellt (HVEM_MMTR_State = 2 ||3 UND DANN KL15 Ein -> KL15 Aus), soll der Konditioniervorgang für eine applizierbare Maximalzeit weiter laufen und die betroffenen Steuergeräte wach gehalten werden. Der Kunde kann die Option mittels Display-Anzeige (HCP3) aktivieren. Anschließend wird der Konditionierungsstatus im Display angezeigt.
          signal NM_aktiv_Remote_Repair_XIX_NM_Gateway_XIX_HCP5_CANFD01: start 127, 1 bit, little-endian, data-type-policy=OVERRIDE, i-signal-type=PRIMITIVE, init-value=0, base-type=BT_NM_aktiv_Remote_Repair, compu {0=Cx0_Inaktiv (CM_NM_aktiv_Remote_Repair_Cx0_Inaktiv), 1=Cx1_Aktiv (CM_NM_aktiv_Remote_Repair_Cx1_Aktiv)}, range raw 0..1, transfer-property=TRIGGERED  # Wird aus den Aftersalessystemen (VW/Audi, Porsche) eine Remote Repair Verbindung zum Fahrzeug aufgebaut, so soll das HCP5 und zur Durchführung von Fehlerbehebungsmaßnahmen das gesamte Fahrzeug aufgeweckt bzw. Wachgehalten werden können. Die Verbindung aus den Aftersalessystemen soll hauptsächlich bei Liegenbleibern zur Anwendung kommen. Des Weiteren wenn die Fahrzeuge auf dem Werkstattgelände stehen, um ohne externen Tester DTCs auslesen zu können.
          signal NM_Gateway_SNI_10_XIX_NM_Gateway_XIX_HCP5_CANFD01: start 128, 10 bit, little-endian, data-type-policy=OVERRIDE, i-signal-type=PRIMITIVE, init-value=16, base-type=BT_NM_Gateway_SNI_10, compu {16=Cx10_Gateway_SNI (CM_NM_Gateway_SNI_10_Cx10_Gateway_SNI)}, range raw 16, transfer-property=TRIGGERED  # Source Node-Identifier (SNI) identifiziert den Sender der NM-Botschaft (Knotenadresse) eindeutig im Fahrzeug
          signal NM_Gateway_NM_State_XIX_NM_Gateway_XIX_HCP5_CANFD01: start 144, 6 bit, little-endian, data-type-policy=OVERRIDE, i-signal-type=PRIMITIVE, init-value=0, base-type=BT_NM_Gateway_NM_State, compu {0=Cx0_Init (CM_NM_Gateway_NM_State_Cx0_Init), 1=Cx1_NM_RM_aus_BSM (CM_NM_Gateway_NM_State_Cx1_NM_RM_aus_BSM), 2=Cx2_NM_RM_aus_PBSM (CM_NM_Gateway_NM_State_Cx2_NM_RM_aus_PBSM), 4=Cx4_NM_NO_aus_RM (CM_NM_Gateway_NM_State_Cx4_NM_NO_aus_RM), 8=Cx8_NM_NO_aus_RS (CM_NM_Gateway_NM_State_Cx8_NM_NO_aus_RS), 16=Cx10_reserved (CM_NM_Gateway_NM_State_Cx10_reserved), 32=Cx20_reserved (CM_NM_Gateway_NM_State_Cx20_reserved)}, range raw 0..32, transfer-property=TRIGGERED  # 1 = Zustand Repeat Message (<-- Bus-Sleep Mode) 2 = Zustand Repeat Message (<-- Prepare Bus-Sleep Mode) 4 = Zustand Normal Operation (<-- Repeat Message) 8 = Zustand Normal Operation (<-- Ready Sleep)
          signal NM_Gateway_UDS_CC_XIX_NM_Gateway_XIX_HCP5_CANFD01: start 151, 1 bit, little-endian, data-type-policy=OVERRIDE, i-signal-type=PRIMITIVE, init-value=0, base-type=BT_NM_Gateway_UDS_CC, compu {0=Cx0_Inaktiv (CM_NM_Gateway_UDS_CC_Cx0_Inaktiv), 1=Cx1_CC_aktiv (CM_NM_Gateway_UDS_CC_Cx1_CC_aktiv)}, range raw 0..1, transfer-property=TRIGGERED  # Funktionseinschränkung aufgrund aktivem UDS-Communication Control, siehe VW80124
          signal NM_Gateway_Wakeup_V12_XIX_NM_Gateway_XIX_HCP5_CANFD01: start 152, 8 bit, little-endian, data-type-policy=OVERRIDE, i-signal-type=PRIMITIVE, init-value=0, base-type=BT_NM_Gateway_Wakeup_V12, compu {0=Cx0_Peripherie_Wakeup_Ursache_nicht_bekannt (CM_NM_Gateway_Wakeup_V12_Cx0_Peripherie_Wakeup_Ursache_nicht_bekannt), 1=Cx1_Bus_Wakeup (CM_NM_Gateway_Wakeup_V12_Cx1_Bus_Wakeup), 2=Cx2_KL15_HW (CM_NM_Gateway_Wakeup_V12_Cx2_KL15_HW), 3=Cx3_KL30_Reset (CM_NM_Gateway_Wakeup_V12_Cx3_KL30_Reset), 4=Cx4_Buswakeup_WU_HCP1_CANFD (CM_NM_Gateway_Wakeup_V12_Cx4_Buswakeup_WU_HCP1_CANFD), 5=Cx5_Buswakeup_WU_HCP2_CANFD (CM_NM_Gateway_Wakeup_V12_Cx5_Buswakeup_WU_HCP2_CANFD), 6=Cx6_Buswakeup_WU_HCP3_CANFD (CM_NM_Gateway_Wakeup_V12_Cx6_Buswakeup_WU_HCP3_CANFD), 7=Cx7_Buswakeup_WU_HCP4_CANFD (CM_NM_Gateway_Wakeup_V12_Cx7_Buswakeup_WU_HCP4_CANFD), 8=Cx8_Buswakeup_HCP5_CANFD01 (CM_NM_Gateway_Wakeup_V12_Cx8_Buswakeup_HCP5_CANFD01), 9=Cx9_Buswakeup_HCP5_CANFD02 (CM_NM_Gateway_Wakeup_V12_Cx9_Buswakeup_HCP5_CANFD02), 10=Cxa_Buswakeup_HCP5_CAN03 (CM_NM_Gateway_Wakeup_V12_Cxa_Buswakeup_HCP5_CAN03), 11=Cxb_Buswakeup_HCP5_CANFD04 (CM_NM_Gateway_Wakeup_V12_Cxb_Buswakeup_HCP5_CANFD04), 12=Cxc_Buswakeup_HCP5_CANFD05 (CM_NM_Gateway_Wakeup_V12_Cxc_Buswakeup_HCP5_CANFD05), 13=Cxd_Buswakeup_HCP5_CANFD06 (CM_NM_Gateway_Wakeup_V12_Cxd_Buswakeup_HCP5_CANFD06), 14=Cxe_reserviert (CM_NM_Gateway_Wakeup_V12_Cxe_reserviert), 16=Cx10_WU_ConMod_CANFD (CM_NM_Gateway_Wakeup_V12_Cx10_WU_ConMod_CANFD), 17=Cx11_Buswakeup_Diag_CANFD (CM_NM_Gateway_Wakeup_V12_Cx11_Buswakeup_Diag_CANFD), 18=Cx12_Buswakeup_Diag_ETH (CM_NM_Gateway_Wakeup_V12_Cx12_Buswakeup_Diag_ETH), 128=Cx80_VNSM_Anforderung (CM_NM_Gateway_Wakeup_V12_Cx80_VNSM_Anforderung), 129=Cx81_Timer_TME_abgelaufen (CM_NM_Gateway_Wakeup_V12_Cx81_Timer_TME_abgelaufen), 130=Cx82_Timer_ELF_abgelaufen (CM_NM_Gateway_Wakeup_V12_Cx82_Timer_ELF_abgelaufen), 131=Cx83_Timer_pTMM_abgelaufen (CM_NM_Gateway_Wakeup_V12_Cx83_Timer_pTMM_abgelaufen), 132=Cx84_Batteriekonditionierung (CM_NM_Gateway_Wakeup_V12_Cx84_Batteriekonditionierung), 133=Cx85_Ladezustand (CM_NM_Gateway_Wakeup_V12_Cx85_Ladezustand), 134=Cx86_Start_HV_Grundladen (CM_NM_Gateway_Wakeup_V12_Cx86_Start_HV_Grundladen), 135=Cx87_Erw_HV_Laden_Anfordern (CM_NM_Gateway_Wakeup_V12_Cx87_Erw_HV_Laden_Anfordern), 136=Cx88_Erw_HV_Laden_Planen (CM_NM_Gateway_Wakeup_V12_Cx88_Erw_HV_Laden_Planen), 137=Cx89_Niveauverstellung_Anfordern (CM_NM_Gateway_Wakeup_V12_Cx89_Niveauverstellung_Anfordern), 138=Cx8a_MOD_Update_Ladevorgang (CM_NM_Gateway_Wakeup_V12_Cx8a_MOD_Update_Ladevorgang), 139=Cx8b_Ladevorbedingung_pruefen (CM_NM_Gateway_Wakeup_V12_Cx8b_Ladevorbedingung_pruefen), 140=Cx8c_NiedervoltEnergieMgmt (CM_NM_Gateway_Wakeup_V12_Cx8c_NiedervoltEnergieMgmt), 141=Cx8d_Timer_HVLM_abgelaufen (CM_NM_Gateway_Wakeup_V12_Cx8d_Timer_HVLM_abgelaufen), 142=Cx8e_SubbusSteuerung_HCP5 (CM_NM_Gateway_Wakeup_V12_Cx8e_SubbusSteuerung_HCP5), 143=Cx8f_CommunicationControl (CM_NM_Gateway_Wakeup_V12_Cx8f_CommunicationControl), 144=Cx90_Ladezugang_ansteuern (CM_NM_Gateway_Wakeup_V12_Cx90_Ladezugang_ansteuern), 145=Cx91_HV_Anforderung (CM_NM_Gateway_Wakeup_V12_Cx91_HV_Anforderung), 146=Cx92_Ladeanforderung (CM_NM_Gateway_Wakeup_V12_Cx92_Ladeanforderung), 147=Cx93_HV_Aktivieren (CM_NM_Gateway_Wakeup_V12_Cx93_HV_Aktivieren), 148=Cx94_Key_Authentifiz_SMS (CM_NM_Gateway_Wakeup_V12_Cx94_Key_Authentifiz_SMS), 150=Cx96_E3_SW_Plattform_1 (CM_NM_Gateway_Wakeup_V12_Cx96_E3_SW_Plattform_1), 151=Cx97_E3_SW_Plattform_2 (CM_NM_Gateway_Wakeup_V12_Cx97_E3_SW_Plattform_2), 152=Cx98_E3_SW_Plattform_3 (CM_NM_Gateway_Wakeup_V12_Cx98_E3_SW_Plattform_3), 153=Cx99_E3_SW_Plattform_4 (CM_NM_Gateway_Wakeup_V12_Cx99_E3_SW_Plattform_4), 154=Cx9a_E3_SW_Plattform_5 (CM_NM_Gateway_Wakeup_V12_Cx9a_E3_SW_Plattform_5), 155=Cx9b_Remote_Honk_Flash (CM_NM_Gateway_Wakeup_V12_Cx9b_Remote_Honk_Flash), 156=Cx9c_Remote_Lock_Unlock (CM_NM_Gateway_Wakeup_V12_Cx9c_Remote_Lock_Unlock), 157=Cx9d_Remote_PreKlimatisierung (CM_NM_Gateway_Wakeup_V12_Cx9d_Remote_PreKlimatisierung), 158=Cx9e_OnlineRemoteUpdate (CM_NM_Gateway_Wakeup_V12_Cx9e_OnlineRemoteUpdate), 159=Cx9f_OnlineRemoteUpdate_PrePost (CM_NM_Gateway_Wakeup_V12_Cx9f_OnlineRemoteUpdate_PrePost), 160=Cxa0_Displayanzeige (CM_NM_Gateway_Wakeup_V12_Cxa0_Displayanzeige), 161=Cxa1_VehicleStatusReport_Daten_Erfassen (CM_NM_Gateway_Wakeup_V12_Cxa1_VehicleStatusReport_Daten_Erfassen), 162=Cxa2_SOC_Abfrage (CM_NM_Gateway_Wakeup_V12_Cxa2_SOC_Abfrage), 163=Cxa3_LHW_eventAirBagDeployment (CM_NM_Gateway_Wakeup_V12_Cxa3_LHW_eventAirBagDeployment), 164=Cxa4_Ladeanforderung_Erweitert (CM_NM_Gateway_Wakeup_V12_Cxa4_Ladeanforderung_Erweitert), 165=Cxa5_Abschaltstufe (CM_NM_Gateway_Wakeup_V12_Cxa5_Abschaltstufe), 166=Cxa6_RemoteStart (CM_NM_Gateway_Wakeup_V12_Cxa6_RemoteStart), 167=Cxa7_Gefahreninfo (CM_NM_Gateway_Wakeup_V12_Cxa7_Gefahreninfo), 168=Cxa8_AutomotiveEdge_1 (CM_NM_Gateway_Wakeup_V12_Cxa8_AutomotiveEdge_1), 169=Cxa9_AutomotiveEdge_2 (CM_NM_Gateway_Wakeup_V12_Cxa9_AutomotiveEdge_2), 170=Cxaa_AutomotiveEdge_3 (CM_NM_Gateway_Wakeup_V12_Cxaa_AutomotiveEdge_3), 171=Cxab_AutomotiveEdge_4 (CM_NM_Gateway_Wakeup_V12_Cxab_AutomotiveEdge_4), 172=Cxac_AutomotiveEdge_5 (CM_NM_Gateway_Wakeup_V12_Cxac_AutomotiveEdge_5), 173=Cxad_RemoteVehicleTracking (CM_NM_Gateway_Wakeup_V12_Cxad_RemoteVehicleTracking), 174=Cxae_OnlinePannenruf (CM_NM_Gateway_Wakeup_V12_Cxae_OnlinePannenruf), 175=Cxaf_WarnblinkerStatusAenderung (CM_NM_Gateway_Wakeup_V12_Cxaf_WarnblinkerStatusAenderung), 176=Cxb0_ConnectVerbund_UseCase1 (CM_NM_Gateway_Wakeup_V12_Cxb0_ConnectVerbund_UseCase1), 177=Cxb1_ConnectVerbund_UseCase2 (CM_NM_Gateway_Wakeup_V12_Cxb1_ConnectVerbund_UseCase2), 178=Cxb2_ConnectVerbund_UseCase3 (CM_NM_Gateway_Wakeup_V12_Cxb2_ConnectVerbund_UseCase3), 179=Cxb3_ConnectVerbund_UseCase4 (CM_NM_Gateway_Wakeup_V12_Cxb3_ConnectVerbund_UseCase4), 180=Cxb4_ConnectVerbund_UseCase5 (CM_NM_Gateway_Wakeup_V12_Cxb4_ConnectVerbund_UseCase5), 181=Cxb5_ConnectVerbund_UseCase6 (CM_NM_Gateway_Wakeup_V12_Cxb5_ConnectVerbund_UseCase6), 182=Cxb6_Timer_ORU_abgelaufen (CM_NM_Gateway_Wakeup_V12_Cxb6_Timer_ORU_abgelaufen), 183=Cxb7_Remote_Repair (CM_NM_Gateway_Wakeup_V12_Cxb7_Remote_Repair)}, range raw 0..183, transfer-property=TRIGGERED  # enthält die Weckursache; stehen mehrere Weckursachen parallel an, dann muss der kleinste Wert übertragen werden
          signal NM_Gateway_NM_aktiv_KL15_XIX_NM_Gateway_XIX_HCP5_CANFD01: start 160, 1 bit, little-endian, data-type-policy=OVERRIDE, i-signal-type=PRIMITIVE, init-value=0, base-type=BT_NM_Gateway_NM_aktiv_KL15, compu {0=Cx0_Inaktiv (CM_NM_Gateway_NM_aktiv_KL15_Cx0_Inaktiv), 1=Cx1_KL15_EIN (CM_NM_Gateway_NM_aktiv_KL15_Cx1_KL15_EIN)}, range raw 0..1, transfer-property=TRIGGERED  # Steuergerät hat KL15-EIN erkannt
          signal NM_Gateway_NM_aktiv_Diag_XIX_NM_Gateway_XIX_HCP5_CANFD01: start 161, 1 bit, little-endian, data-type-policy=OVERRIDE, i-signal-type=PRIMITIVE, init-value=0, base-type=BT_NM_Gateway_NM_aktiv_Diag, compu {0=Cx0_Inaktiv (CM_NM_Gateway_NM_aktiv_Diag_Cx0_Inaktiv), 1=Cx1_Diagnose_aktiv (CM_NM_Gateway_NM_aktiv_Diag_Cx1_Diagnose_aktiv)}, range raw 0..1, transfer-property=TRIGGERED  # Diagnose befindet sich nach VW80124 in einer NonDefaultDiagnostic-Session, z.B. ExtendedDiagnostic-Session
          signal NM_Gateway_NM_aktiv_Tmin_XIX_NM_Gateway_XIX_HCP5_CANFD01: start 162, 1 bit, little-endian, data-type-policy=OVERRIDE, i-signal-type=PRIMITIVE, init-value=0, base-type=BT_NM_Gateway_NM_aktiv_Tmin, compu {0=Cx0_Inaktiv (CM_NM_Gateway_NM_aktiv_Tmin_Cx0_Inaktiv), 1=Cx1_Mindestaktivzeit (CM_NM_Gateway_NM_aktiv_Tmin_Cx1_Mindestaktivzeit)}, range raw 0..1, transfer-property=TRIGGERED  # Mindestaktivzeit ist noch nicht abgelaufen (bei jedem Weckereignis wird die Mindestaktivzeit neu gestartet)
          signal NM_Gateway_NM_aktiv_CABaktiv_XIX_NM_Gateway_XIX_HCP5_CANFD01: start 163, 1 bit, little-endian, data-type-policy=OVERRIDE, i-signal-type=PRIMITIVE, init-value=0, base-type=BT_NM_Gateway_NM_aktiv_CABaktiv, compu {0=Cx0_Inaktiv (CM_NM_Gateway_NM_aktiv_CABaktiv_Cx0_Inaktiv), 1=Cx1_Cluster_Min_Req_TimeOfVNSM (CM_NM_Gateway_NM_aktiv_CABaktiv_Cx1_Cluster_Min_Req_TimeOfVNSM)}, range raw 0..1, transfer-property=TRIGGERED  # Nachlauf aufgrund Funktionscluster Anforderung
          signal NM_aktiv_Gefahreninfo_XIX_NM_Gateway_XIX_HCP5_CANFD01: start 164, 1 bit, little-endian, data-type-policy=OVERRIDE, i-signal-type=PRIMITIVE, init-value=0, base-type=BT_NM_aktiv_Gefahreninfo, compu {0=Cx0_inaktiv (CM_NM_aktiv_Gefahreninfo_Cx0_inaktiv), 1=Cx1_aktiv (CM_NM_aktiv_Gefahreninfo_Cx1_aktiv)}, range raw 0..1, transfer-property=TRIGGERED  # Nach dem Ausschalten der Zündung soll eine Veränderung der Position des FZGs, bzw. eine Bewegung des FZGs erkannt werden und ein zuvor detektiertes Pannen oder Unfall Event gecanncelt werden. Das versenden des Cancel-Events ans Backend muss noch sichergestellt sein. Allerdings tritt der Fall nur auf, wenn davor ein Unfall oder eine Panne detektiert wurde, also sehr selten.
          signal NM_aktiv_MVEM_Pos_RSG_XIX_NM_Gateway_XIX_HCP5_CANFD01: start 165, 1 bit, little-endian, data-type-policy=OVERRIDE, i-signal-type=PRIMITIVE, init-value=0, base-type=BT_NM_aktiv_MVEM_Pos_RSG, compu {0=Cx0_Inaktiv (CM_NM_aktiv_MVEM_Pos_RSG_Cx0_Inaktiv), 1=Cx1_Aktiv (CM_NM_aktiv_MVEM_Pos_RSG_Cx1_Aktiv)}, range raw 0..1, transfer-property=TRIGGERED  # Nach Ausschalten der Kl.15 soll der HCP5 noch für eine gewisse Zeit wachgehalten werden für Stalling Help/Positionierung vom RSG .
          signal NM_aktiv_Timer_abgelaufen_XIX_NM_Gateway_XIX_HCP5_CANFD01: start 166, 1 bit, little-endian, data-type-policy=OVERRIDE, i-signal-type=PRIMITIVE, init-value=0, base-type=BT_NM_aktiv_Timer_abgelaufen, compu {0=Cx0_Inaktiv (CM_NM_aktiv_Timer_abgelaufen_Cx0_Inaktiv), 1=Cx1_Aktiv (CM_NM_aktiv_Timer_abgelaufen_Cx1_Aktiv)}, range raw 0..1, transfer-property=TRIGGERED  # Timer des Basisdienst Zeitmaster::Timemaster_OBD hat ausgelöst
          signal NM_aktiv_Batteriekonditionierung_XIX_NM_Gateway_XIX_HCP5_CANFD01: start 167, 1 bit, little-endian, data-type-policy=OVERRIDE, i-signal-type=PRIMITIVE, init-value=0, base-type=BT_NM_aktiv_Batteriekonditionierung, compu {0=Cx0_Inaktiv (CM_NM_aktiv_Batteriekonditionierung_Cx0_Inaktiv), 1=Cx1_Aktiv (CM_NM_aktiv_Batteriekonditionierung_Cx1_Aktiv)}, range raw 0..1, transfer-property=TRIGGERED  # Zur Reduzierung der Ladezeit, Steigerung der Abfahrtsperfomance und Erhöhung der Reichweite durch Nutzung der HV-Batterie als Wärmequelle muss die HV-Batterie in einen Temperaturbereich konditioniert werden. Das prädiktive Thermomanagement ermittelt mittels Ladeplanung bzw. Abfahrtimer die notwendige Konditionierungsdauer und stellt in der Timerverwaltung einen Weckevorgang ein.
          signal NM_aktiv_HV_Laden_XIX_NM_Gateway_XIX_HCP5_CANFD01: start 168, 1 bit, little-endian, data-type-policy=OVERRIDE, i-signal-type=PRIMITIVE, init-value=0, base-type=BT_NM_aktiv_HV_Laden, compu {0=Cx0_Inaktiv (CM_NM_aktiv_HV_Laden_Cx0_Inaktiv), 1=Cx1_Aktiv (CM_NM_aktiv_HV_Laden_Cx1_Aktiv)}, range raw 0..1, transfer-property=TRIGGERED  # CMS-SWC fordert AC/DC-Laden
          signal NM_aktiv_Backend_KomGW_XIX_NM_Gateway_XIX_HCP5_CANFD01: start 169, 1 bit, little-endian, data-type-policy=OVERRIDE, i-signal-type=PRIMITIVE, init-value=0, base-type=BT_NM_aktiv_Backend_KomGW, compu {0=Cx0_Inaktiv (CM_NM_aktiv_Backend_KomGW_Cx0_Inaktiv), 1=Cx1_Aktiv (CM_NM_aktiv_Backend_KomGW_Cx1_Aktiv)}, range raw 0..1, transfer-property=TRIGGERED  # Der Nachlauf wird benötigt um eine Online Kommunikation zwischen dem Fahrzeug und dem Backend zu ermöglichen.
          signal NM_aktiv_Erw_HV_Ladefunktion_XIX_NM_Gateway_XIX_HCP5_CANFD01: start 170, 1 bit, little-endian, data-type-policy=OVERRIDE, i-signal-type=PRIMITIVE, init-value=0, base-type=BT_NM_aktiv_Erw_HV_Ladefunktion, compu {0=Cx0_Inaktiv (CM_NM_aktiv_Erw_HV_Ladefunktion_Cx0_Inaktiv), 1=Cx1_Aktiv (CM_NM_aktiv_Erw_HV_Ladefunktion_Cx1_Aktiv)}, range raw 0..1, transfer-property=TRIGGERED  # Anhand von Eingaben durch den Kunden wie z.b. einer Abfahrtszeit oder aufgrund von Preisleistungsinformationen werden Ladepläne berechnet und Zeitversetzt ggf. mit Unterbrechungen geladen.
          signal NM_aktiv_E3_SW_Plattform_1_XIX_NM_Gateway_XIX_HCP5_CANFD01: start 171, 1 bit, little-endian, data-type-policy=OVERRIDE, i-signal-type=PRIMITIVE, init-value=0, base-type=BT_NM_aktiv_E3_SW_Plattform_1, compu {0=Cx0_Inaktiv (CM_NM_aktiv_E3_SW_Plattform_1_Cx0_Inaktiv), 1=Cx1_Aktiv (CM_NM_aktiv_E3_SW_Plattform_1_Cx1_Aktiv)}, range raw 0..1, transfer-property=TRIGGERED  # Busaktivität wird durch Applikation 1 auf der E3 SW Plattform angefordert
          signal NM_aktiv_E3_SW_Plattform_2_XIX_NM_Gateway_XIX_HCP5_CANFD01: start 172, 1 bit, little-endian, data-type-policy=OVERRIDE, i-signal-type=PRIMITIVE, init-value=0, base-type=BT_NM_aktiv_E3_SW_Plattform_2, compu {0=Cx0_Inaktiv (CM_NM_aktiv_E3_SW_Plattform_2_Cx0_Inaktiv), 1=Cx1_Aktiv (CM_NM_aktiv_E3_SW_Plattform_2_Cx1_Aktiv)}, range raw 0..1, transfer-property=TRIGGERED  # Busaktivität wird durch Applikation 2 auf der E3 SW Plattform angefordert
          signal NM_aktiv_E3_SW_Plattform_3_XIX_NM_Gateway_XIX_HCP5_CANFD01: start 173, 1 bit, little-endian, data-type-policy=OVERRIDE, i-signal-type=PRIMITIVE, init-value=0, base-type=BT_NM_aktiv_E3_SW_Plattform_3, compu {0=Cx0_Inaktiv (CM_NM_aktiv_E3_SW_Plattform_3_Cx0_Inaktiv), 1=Cx1_Aktiv (CM_NM_aktiv_E3_SW_Plattform_3_Cx1_Aktiv)}, range raw 0..1, transfer-property=TRIGGERED  # Busaktivität wird durch Applikation 3 auf der E3 SW Plattform angefordert
          signal NM_aktiv_E3_SW_Plattform_4_XIX_NM_Gateway_XIX_HCP5_CANFD01: start 174, 1 bit, little-endian, data-type-policy=OVERRIDE, i-signal-type=PRIMITIVE, init-value=0, base-type=BT_NM_aktiv_E3_SW_Plattform_4, compu {0=Cx0_Inaktiv (CM_NM_aktiv_E3_SW_Plattform_4_Cx0_Inaktiv), 1=Cx1_Aktiv (CM_NM_aktiv_E3_SW_Plattform_4_Cx1_Aktiv)}, range raw 0..1, transfer-property=TRIGGERED  # Busaktivität wird durch Applikation 4 auf der E3 SW Plattform angefordert
          signal NM_aktiv_E3_SW_Plattform_5_XIX_NM_Gateway_XIX_HCP5_CANFD01: start 175, 1 bit, little-endian, data-type-policy=OVERRIDE, i-signal-type=PRIMITIVE, init-value=0, base-type=BT_NM_aktiv_E3_SW_Plattform_5, compu {0=Cx0_Inaktiv (CM_NM_aktiv_E3_SW_Plattform_5_Cx0_Inaktiv), 1=Cx1_Aktiv (CM_NM_aktiv_E3_SW_Plattform_5_Cx1_Aktiv)}, range raw 0..1, transfer-property=TRIGGERED  # Busaktivität wird durch Applikation 5 auf der E3 SW Plattform angefordert
          signal NM_aktiv_Key_Authentifiz_SMS_XIX_NM_Gateway_XIX_HCP5_CANFD01: start 176, 1 bit, little-endian, data-type-policy=OVERRIDE, i-signal-type=PRIMITIVE, init-value=0, base-type=BT_NM_aktiv_Key_Authentifiz_SMS, compu {0=Cx0_Inaktiv (CM_NM_aktiv_Key_Authentifiz_SMS_Cx0_Inaktiv), 1=Cx1_Aktiv (CM_NM_aktiv_Key_Authentifiz_SMS_Cx1_Aktiv)}, range raw 0..1, transfer-property=TRIGGERED  # Im Rahmen der Funktion MDK 2.0 müssen zu bestimmten Zeitpunkten Daten mit dem Backend ausgetauscht werden, um z.B. digitale Schlüssel im Fahrzeug zu löschen oder Zertifikate und Konfigurationsdaten zu aktualisieren
          signal NM_aktiv_HVK_XIX_NM_Gateway_XIX_HCP5_CANFD01: start 177, 1 bit, little-endian, data-type-policy=OVERRIDE, i-signal-type=PRIMITIVE, init-value=0, base-type=BT_NM_aktiv_HVK, compu {0=Cx0_Inaktiv (CM_NM_aktiv_HVK_Cx0_Inaktiv), 1=Cx1_Aktiv (CM_NM_aktiv_HVK_Cx1_Aktiv)}, range raw 0..1, transfer-property=TRIGGERED  # Der HV-Koordinator stellt den Fahrzeugfunktionen ein aktives HV-System im benötigten Betriebszustand zur Verfügung. Da es insbesondere für HV-Laden und für die Vorkonditionierung HV-Betriebszustände ohne KL15 Ein gibt, muss der Hochvolt-Koordinator benötigte Funktionen und HV-Komponenten aktiv anfordern.
          signal NM_aktiv_HVLM_XIX_NM_Gateway_XIX_HCP5_CANFD01: start 178, 1 bit, little-endian, data-type-policy=OVERRIDE, i-signal-type=PRIMITIVE, init-value=0, base-type=BT_NM_aktiv_HVLM, compu {0=Cx0_Inaktiv (CM_NM_aktiv_HVLM_Cx0_Inaktiv), 1=Cx1_Aktiv (CM_NM_aktiv_HVLM_Cx1_Aktiv)}, range raw 0..1, transfer-property=TRIGGERED  # HV-Lademanager bzw CMS-SWC fordert AC/DC-Laden
          signal NM_aktiv_NVEM_XIX_NM_Gateway_XIX_HCP5_CANFD01: start 179, 1 bit, little-endian, data-type-policy=OVERRIDE, i-signal-type=PRIMITIVE, init-value=0, base-type=BT_NM_aktiv_NVEM, compu {0=Cx0_Inaktiv (CM_NM_aktiv_NVEM_Cx0_Inaktiv), 1=Cx1_Aktiv (CM_NM_aktiv_NVEM_Cx1_Aktiv)}, range raw 0..1, transfer-property=TRIGGERED  # Niedervolt-Energiemanagement startet bei Unterschreitung eines bestimmten Ladungsinhalts der Niedervoltbatteri selbstständig den Nachlade-Prozess.
          signal NM_aktiv_OnlineRemoteUpdate_XIX_NM_Gateway_XIX_HCP5_CANFD01: start 180, 1 bit, little-endian, data-type-policy=OVERRIDE, i-signal-type=PRIMITIVE, init-value=0, base-type=BT_NM_aktiv_OnlineRemoteUpdate, compu {0=Cx0_Inaktiv (CM_NM_aktiv_OnlineRemoteUpdate_Cx0_Inaktiv), 1=Cx1_Aktiv (CM_NM_aktiv_OnlineRemoteUpdate_Cx1_Aktiv)}, range raw 0..1, transfer-property=TRIGGERED  # Im ORU Fall muss nach Kundenzustimmung des Updates geweckt wecken, um Vorbedinungungen für das Update zu prüfen sowie die Verbindung zu den betroffenen Steuergeräten aufzubauen und aufrechtzuerhalten.
          signal NM_aktiv_RemoteDiensteGW_XIX_NM_Gateway_XIX_HCP5_CANFD01: start 181, 1 bit, little-endian, data-type-policy=OVERRIDE, i-signal-type=PRIMITIVE, init-value=0, base-type=BT_NM_aktiv_RemoteDiensteGW, compu {0=Cx0_Inaktiv (CM_NM_aktiv_RemoteDiensteGW_Cx0_Inaktiv), 1=Cx1_Aktiv (CM_NM_aktiv_RemoteDiensteGW_Cx1_Aktiv)}, range raw 0..1, transfer-property=TRIGGERED  # Das Fahrzeug wird bei einem Smart-Phone-App Aufruf über die ConMod für einen Job geweckt. Der empfangene Job wird an das BCM bzw TME gesendet, welche die weiteren Services anbieten.
          signal NM_aktiv_SubbusSteuerung_HCP5_XIX_NM_Gateway_XIX_HCP5_CANFD01: start 182, 1 bit, little-endian, data-type-policy=OVERRIDE, i-signal-type=PRIMITIVE, init-value=0, base-type=BT_NM_aktiv_SubbusSteuerung_HCP5, compu {0=Cx0_Inaktiv (CM_NM_aktiv_SubbusSteuerung_HCP5_Cx0_Inaktiv), 1=Cx1_Aktiv (CM_NM_aktiv_SubbusSteuerung_HCP5_Cx1_Aktiv)}, range raw 0..1, transfer-property=TRIGGERED  # Steuerung des MFL_CAN sowie der Ethernet-Links HCP5_MFK_ETH, HCP5_MRR_ETH und HCP5_xView_ETH
          signal NM_aktiv_VehicleStatReport_Main_XIX_NM_Gateway_XIX_HCP5_CANFD01: start 183, 1 bit, little-endian, data-type-policy=OVERRIDE, i-signal-type=PRIMITIVE, init-value=0, base-type=BT_NM_aktiv_VehicleStatReport_Main, compu {0=Cx0_Inaktiv (CM_NM_aktiv_VehicleStatReport_Main_Cx0_Inaktiv), 1=Cx1_Aktiv (CM_NM_aktiv_VehicleStatReport_Main_Cx1_Aktiv)}, range raw 0..1, transfer-property=TRIGGERED  # Die Funktion zeigt Daten wie Türen und Fensterstatus oder Reichweiten in der App oder dem Portal an.
          signal NM_aktiv_Remote_Unlock_Lock_XIX_NM_Gateway_XIX_HCP5_CANFD01: start 184, 1 bit, little-endian, data-type-policy=OVERRIDE, i-signal-type=PRIMITIVE, init-value=0, base-type=BT_NM_aktiv_Remote_Unlock_Lock, compu {0=Cx0_Inaktiv (CM_NM_aktiv_Remote_Unlock_Lock_Cx0_Inaktiv), 1=Cx1_Aktiv (CM_NM_aktiv_Remote_Unlock_Lock_Cx1_Aktiv)}, range raw 0..1, transfer-property=TRIGGERED  # Über Smartphone App kann Nutzer ferngesteuert die Türen ver- und entriegeln: Fahrzeug wird für einen solchen Job geweckt über Online-Verbindung (conMod > HCP5; abgedeckt durch CoreServices Wakeup 85.3); empfangener Job wird von HCP5 an HCP4 gesendet (dieser Weck-/ Nachlaufgrund); HCP4 führt die Lock/Unlock Funktionalität dann aus, braucht dazu Backend-Kommunikation (HCP5 + ConMod), Türsteuergeräte, Zentralverriegelung und Powertrain (HCP1 + Gearbox) (weiterer Antrag/ Update von 67.2 )
          signal NM_aktiv_HVEM_XIX_NM_Gateway_XIX_HCP5_CANFD01: start 185, 1 bit, little-endian, data-type-policy=OVERRIDE, i-signal-type=PRIMITIVE, init-value=0, base-type=BT_NM_aktiv_HVEM, compu {0=Cx0_Inaktiv (CM_NM_aktiv_HVEM_Cx0_Inaktiv), 1=Cx1_Aktiv (CM_NM_aktiv_HVEM_Cx1_Aktiv)}, range raw 0..1, transfer-property=TRIGGERED  # Das Hochvolt-Energiemanagement (HVEM) ist für die Verteilung von Leistung und Energie in allen Betriebszuständen im HV-System zuständig.
          signal NM_aktiv_Call_XIX_NM_Gateway_XIX_HCP5_CANFD01: start 186, 1 bit, little-endian, data-type-policy=OVERRIDE, i-signal-type=PRIMITIVE, init-value=0, base-type=BT_NM_aktiv_Call, compu {0=Cx0_Inaktiv (CM_NM_aktiv_Call_Cx0_Inaktiv), 1=Cx1_Aktiv (CM_NM_aktiv_Call_Cx1_Aktiv)}, range raw 0..1, transfer-property=TRIGGERED  # Wird ein eCall oder Online Pannenruf durchgeführt und ist der Anruf zum Notruf oder Pannenruf Callcenter bereits aufgebaut, darf beim Ausschalten der KL15 der HCP3, ConMod und HCP5 nicht schlafen gehen
          signal NM_aktiv_RemoteStart_XIX_NM_Gateway_XIX_HCP5_CANFD01: start 187, 1 bit, little-endian, data-type-policy=OVERRIDE, i-signal-type=PRIMITIVE, init-value=0, base-type=BT_NM_aktiv_RemoteStart, compu {0=Cx0_Inaktiv (CM_NM_aktiv_RemoteStart_Cx0_Inaktiv), 1=Cx1_Aktiv (CM_NM_aktiv_RemoteStart_Cx1_Aktiv)}, range raw 0..1, transfer-property=TRIGGERED  # Zur Ausführung des Remote Motorstarts wird über den MOD eine Aktivierung durch den Fahrzeughalter über Smartphone getriggert
          signal NM_aktiv_Ladezustand_XIX_NM_Gateway_XIX_HCP5_CANFD01: start 188, 1 bit, little-endian, data-type-policy=OVERRIDE, i-signal-type=PRIMITIVE, init-value=0, base-type=BT_NM_aktiv_Ladezustand, compu {0=Cx0_Inaktiv (CM_NM_aktiv_Ladezustand_Cx0_Inaktiv), 1=Cx1_Aktiv (CM_NM_aktiv_Ladezustand_Cx1_Aktiv)}, range raw 0..1, transfer-property=TRIGGERED  # Über die App kann der Nutzer ferngesteuert zwischen Sofort und Zeitversetzten Laden wechseln. Weiterhin sendet das Fahrzeug wärend aktivem Ladevorgang zyklisch Updates zum Ladeverlauf.
          signal NM_aktiv_RemoteVehicleTracking_XIX_NM_Gateway_XIX_HCP5_CANFD01: start 189, 1 bit, little-endian, data-type-policy=OVERRIDE, i-signal-type=PRIMITIVE, init-value=0, base-type=BT_NM_aktiv_RemoteVehicleTracking, compu {0=Cx0_Inaktiv (CM_NM_aktiv_RemoteVehicleTracking_Cx0_Inaktiv), 1=Cx1_Aktiv (CM_NM_aktiv_RemoteVehicleTracking_Cx1_Aktiv)}, range raw 0..1, transfer-property=TRIGGERED  # Der RVT ist ein Diebstahlschutz, der remote das gestohlene Fahrzeug von einem Callcenter tracken kann. Dazu muss der Bus aufgeweckt werden.
          signal NM_aktiv_WarnblinkerInfo_XIX_NM_Gateway_XIX_HCP5_CANFD01: start 190, 1 bit, little-endian, data-type-policy=OVERRIDE, i-signal-type=PRIMITIVE, init-value=0, base-type=BT_NM_aktiv_WarnblinkerInfo, compu {0=Cx0_Inaktiv (CM_NM_aktiv_WarnblinkerInfo_Cx0_Inaktiv), 1=Cx1_Aktiv (CM_NM_aktiv_WarnblinkerInfo_Cx1_Aktiv)}, range raw 0..1, transfer-property=TRIGGERED  # - Der chinesische LTE-V2X Standard erfordert BSM Nachrichten. Das "Vehicle event flag" ist ein verpflichtender Teil dieser BSM Nachricht. Da die ConMod das nicht befüllen kann, soll diese SWC "LHWSenderChinaVehicleEventFlags" die Berechnung dieser Vehicle Event Flags übernehmen. Die Zusammensetzung und das Aussenden der vollständigen BSM-Nachrichten erfolgt nachgehend in der ConMod. - Eines dieser Vehicle Event Flags beschreibt das Verhalten bei aktiviertem Warnblinker. Ist der Warnblinker aktiviert sollen BSMs mit entsprechenden event flags auch bei inaktiver Klemme15 versendet werden. Hierfür ist ein Wecken der ConMod notwendig.
          signal NM_aktiv_NVEM2_XIX_NM_Gateway_XIX_HCP5_CANFD01: start 191, 1 bit, little-endian, data-type-policy=OVERRIDE, i-signal-type=PRIMITIVE, init-value=0, base-type=BT_NM_aktiv_NVEM2, compu {0=Cx0_Inaktiv (CM_NM_aktiv_NVEM2_Cx0_Inaktiv), 1=Cx1_Aktiv (CM_NM_aktiv_NVEM2_Cx1_Aktiv)}, range raw 0..1, transfer-property=TRIGGERED  # Niedervoltenergiemanagement 2 zur Sicherstellung der Versorgung sicherheitsrelevanter Verbraucher.
      frame NM_HVZB_XIX_HCP5_CANFD01: id 0x1B00011D, to BMC_HV, frame-length=24, can-addressing-mode=EXTENDED, can-frame-rx-behavior=CAN-FD, can-frame-tx-behavior=CAN-FD, rx-identifier-range={lower-can-id=452984832, upper-can-id=452985855}
        nm pdu NM_HVZB_XIX_HCP5_CANFD01: length=24, unused-bit-pattern=0
          signal NM_HVZB_CBV_AWB_XIX_NM_HVZB_XIX_HCP5_CANFD01: start 4, 1 bit, little-endian, data-type-policy=OVERRIDE, i-signal-type=PRIMITIVE, init-value=0, base-type=BT_NM_HVZB_CBV_AWB, compu {0=Cx0_Passiver_WakeUp (CM_NM_HVZB_CBV_AWB_Cx0_Passiver_WakeUp), 1=Cx1_Aktiver_WakeUp (CM_NM_HVZB_CBV_AWB_Cx1_Aktiver_WakeUp)}, range raw 0..1, transfer-property=TRIGGERED  # Das Signal ist zu setzen, wenn das SG aktiv den Bus geweckt hat 0 = Passiver_WakeUp = SG hat das Netzwerk nicht aktiv geweckt 1 = Akitiver_WakeUp = SG hat das Netzwerk aktiv geweckt
          signal NM_HVZB_CBV_CRI_XIX_NM_HVZB_XIX_HCP5_CANFD01: start 6, 1 bit, little-endian, data-type-policy=OVERRIDE, i-signal-type=PRIMITIVE, init-value=1, base-type=BT_NM_HVZB_CBV_CRI, compu {0=Cx0_NM_ohne_Clusteranforderungen (CM_NM_HVZB_CBV_CRI_Cx0_NM_ohne_Clusteranforderungen), 1=Cx1_NM_mit_Clusteranforderungen (CM_NM_HVZB_CBV_CRI_Cx1_NM_mit_Clusteranforderungen)}, range raw 0..1, transfer-property=TRIGGERED  # Das Signal ist dauerhaft gesetzt, wenn das NM-Layout Cluster- Anforderungen enthält
          signal NM_HVZB_FCAB_XIX_NM_HVZB_XIX_HCP5_CANFD01: start 8, 56 bit, opaque, data-type-policy=OVERRIDE, i-signal-type=ARRAY, init-value=7 x 0b00000000, base-type=BT_NM_HVZB_FCAB, compu {0=Cx0_Init (CM_NM_HVZB_FCAB_Cx0_Init), 1=Cx1_01_CarWakeUp (CM_NM_HVZB_FCAB_Cx1_01_CarWakeUp), 2=Cx2_02_Basefunction_Powertrain (CM_NM_HVZB_FCAB_Cx2_02_Basefunction_Powertrain), 4=Cx4_03_Basefunction_Chassis (CM_NM_HVZB_FCAB_Cx4_03_Basefunction_Chassis), 8=Cx8_04_Basefunction_DrivingAssistance (CM_NM_HVZB_FCAB_Cx8_04_Basefunction_DrivingAssistance), 16=Cx10_05_Basefunction_Infotainment (CM_NM_HVZB_FCAB_Cx10_05_Basefunction_Infotainment), 32=Cx20_06_Basefunction_ComfortLight (CM_NM_HVZB_FCAB_Cx20_06_Basefunction_ComfortLight), 64=Cx40_07_Basefunction_CrossSection (CM_NM_HVZB_FCAB_Cx40_07_Basefunction_CrossSection), 128=Cx80_08_Basefunction_Connectivity (CM_NM_HVZB_FCAB_Cx80_08_Basefunction_Connectivity), 256=Cx100_09_Basefunction_DrivingAssistanceCore (CM_NM_HVZB_FCAB_Cx100_09_Basefunction_DrivingAssistanceCore), 512=Cx200_10_Powertrain (CM_NM_HVZB_FCAB_Cx200_10_Powertrain), 1024=Cx400_11_Chassis (CM_NM_HVZB_FCAB_Cx400_11_Chassis), 2048=Cx800_12_GearSelector (CM_NM_HVZB_FCAB_Cx800_12_GearSelector), 4096=Cx1000_13_Airbag (CM_NM_HVZB_FCAB_Cx1000_13_Airbag), 8192=Cx2000_14_InfotainmentExtensions (CM_NM_HVZB_FCAB_Cx2000_14_InfotainmentExtensions), 16384=Cx4000_15_InstrumentclusterDisplay (CM_NM_HVZB_FCAB_Cx4000_15_InstrumentclusterDisplay), 32768=Cx8000_16_InfotainmentDisplay (CM_NM_HVZB_FCAB_Cx8000_16_InfotainmentDisplay), 65536=Cx10000_17_Audio (CM_NM_HVZB_FCAB_Cx10000_17_Audio), 131072=Cx20000_18_VirtualSideMirrors (CM_NM_HVZB_FCAB_Cx20000_18_VirtualSideMirrors), 262144=Cx40000_19_Doors_Hatches (CM_NM_HVZB_FCAB_Cx40000_19_Doors_Hatches), 524288=Cx80000_20_OptionalComfort (CM_NM_HVZB_FCAB_Cx80000_20_OptionalComfort), 1048576=Cx100000_21_AirSuspension (CM_NM_HVZB_FCAB_Cx100000_21_AirSuspension), 2097152=Cx200000_22_ExteriorLights (CM_NM_HVZB_FCAB_Cx200000_22_ExteriorLights), 4194304=Cx400000_23_Climate (CM_NM_HVZB_FCAB_Cx400000_23_Climate), 8388608=Cx800000_24_ThermoManagement (CM_NM_HVZB_FCAB_Cx800000_24_ThermoManagement), 16777216=Cx1000000_25_AccessSystemSensors (CM_NM_HVZB_FCAB_Cx1000000_25_AccessSystemSensors), 33554432=Cx2000000_26_HighVoltage_Charging (CM_NM_HVZB_FCAB_Cx2000000_26_HighVoltage_Charging), 67108864=Cx4000000_27_Timemaster_Timer (CM_NM_HVZB_FCAB_Cx4000000_27_Timemaster_Timer), 134217728=Cx8000000_28_OnboardTester_DataCollector (CM_NM_HVZB_FCAB_Cx8000000_28_OnboardTester_DataCollector), 268435456=Cx10000000_29_SteeringColumnLock (CM_NM_HVZB_FCAB_Cx10000000_29_SteeringColumnLock), 536870912=Cx20000000_30_EnergyManagement (CM_NM_HVZB_FCAB_Cx20000000_30_EnergyManagement), 1073741824=Cx40000000_31_MultifunctionalSteeringWheel (CM_NM_HVZB_FCAB_Cx40000000_31_MultifunctionalSteeringWheel), 2147483648=Cx80000000_32_OnlineAccess (CM_NM_HVZB_FCAB_Cx80000000_32_OnlineAccess), 4294967296=Cx100000000_33_ExternalWirelessCommunication (CM_NM_HVZB_FCAB_Cx100000000_33_ExternalWirelessCommunication), 8589934592=Cx200000000_34_GPS_Localization (CM_NM_HVZB_FCAB_Cx200000000_34_GPS_Localization), 17179869184=Cx400000000_35_ExteriorSound (CM_NM_HVZB_FCAB_Cx400000000_35_ExteriorSound), 34359738368=Cx800000000_36_Preheater (CM_NM_HVZB_FCAB_Cx800000000_36_Preheater), 68719476736=Cx1000000000_37_HighVoltage_WirelessChargingStation (CM_NM_HVZB_FCAB_Cx1000000000_37_HighVoltage_WirelessChargingStation), 549755813888=Cx8000000000_40_Diagnosis_Energy (CM_NM_HVZB_FCAB_Cx8000000000_40_Diagnosis_Energy), 1099511627776=Cx10000000000_41_Diagnosis_Powertrain (CM_NM_HVZB_FCAB_Cx10000000000_41_Diagnosis_Powertrain), 2199023255552=Cx20000000000_42_Diagnosis_FlexRay (CM_NM_HVZB_FCAB_Cx20000000000_42_Diagnosis_FlexRay), 4398046511104=Cx40000000000_43_Diagnosis_DrivingAssistance (CM_NM_HVZB_FCAB_Cx40000000000_43_Diagnosis_DrivingAssistance), 8796093022208=Cx80000000000_44_Diagnosis_Infotainment (CM_NM_HVZB_FCAB_Cx80000000000_44_Diagnosis_Infotainment), 17592186044416=Cx100000000000_45_Diagnosis_Comfort (CM_NM_HVZB_FCAB_Cx100000000000_45_Diagnosis_Comfort), 35184372088832=Cx200000000000_46_Diagnosis_Light (CM_NM_HVZB_FCAB_Cx200000000000_46_Diagnosis_Light), 70368744177664=Cx400000000000_47_Diagnosis_ComfortLINs (CM_NM_HVZB_FCAB_Cx400000000000_47_Diagnosis_ComfortLINs), 140737488355328=Cx800000000000_48_Diagnosis_ClimateTmeLINs (CM_NM_HVZB_FCAB_Cx800000000000_48_Diagnosis_ClimateTmeLINs), 281474976710656=Cx1000000000000_49_reserved (CM_NM_HVZB_FCAB_Cx1000000000000_49_reserved) (49_<reserved>), 4503599627370500.0=Cx10000000000000_53_Lock_Unlock (CM_NM_HVZB_FCAB_Cx10000000000000_53_Lock_Unlock), 9007199254740990.0=Cx20000000000000_54_reserved (CM_NM_HVZB_FCAB_Cx20000000000000_54_reserved) (54_<reserved>), 1.8014398509482e+16=Cx40000000000000_55_Dimming (CM_NM_HVZB_FCAB_Cx40000000000000_55_Dimming), 3.6028797018964e+16=Cx80000000000000_56_ChargingStatus (CM_NM_HVZB_FCAB_Cx80000000000000_56_ChargingStatus)}, range raw 0..36028797018963968, transfer-property=TRIGGERED-ON-CHANGE, to BMC_HV(timeout 2 s)  # FCAB = Funktions-Cluster-Aktiv-Bits
          signal NM_HVZB_SNI_10_XIX_NM_HVZB_XIX_HCP5_CANFD01: start 128, 10 bit, little-endian, data-type-policy=OVERRIDE, i-signal-type=PRIMITIVE, init-value=285, base-type=BT_NM_HVZB_SNI_10, compu {285=Cx11d_HVZB_SNI (CM_NM_HVZB_SNI_10_Cx11d_HVZB_SNI)}, range raw 285, transfer-property=TRIGGERED  # Source Node-Identifier (SNI) identifiziert den Sender der NM-Botschaft (Knotenadresse) eindeutig im Fahrzeug
          signal NM_HVZB_NM_State_XIX_NM_HVZB_XIX_HCP5_CANFD01: start 144, 6 bit, little-endian, data-type-policy=OVERRIDE, i-signal-type=PRIMITIVE, init-value=0, base-type=BT_NM_HVZB_NM_State, compu {0=Cx0_Init (CM_NM_HVZB_NM_State_Cx0_Init), 1=Cx1_NM_RM_aus_BSM (CM_NM_HVZB_NM_State_Cx1_NM_RM_aus_BSM), 2=Cx2_NM_RM_aus_PBSM (CM_NM_HVZB_NM_State_Cx2_NM_RM_aus_PBSM), 4=Cx4_NM_NO_aus_RM (CM_NM_HVZB_NM_State_Cx4_NM_NO_aus_RM), 8=Cx8_NM_NO_aus_RS (CM_NM_HVZB_NM_State_Cx8_NM_NO_aus_RS), 16=Cx10_reserved (CM_NM_HVZB_NM_State_Cx10_reserved), 32=Cx20_reserved (CM_NM_HVZB_NM_State_Cx20_reserved)}, range raw 0..32, transfer-property=TRIGGERED  # 1 = Zustand Repeat Message (<-- Bus-Sleep Mode) 2 = Zustand Repeat Message (<-- Prepare Bus-Sleep Mode) 4 = Zustand Normal Operation (<-- Repeat Message) 8 = Zustand Normal Operation (<-- Ready Sleep)
          signal NM_HVZB_UDS_CC_XIX_NM_HVZB_XIX_HCP5_CANFD01: start 151, 1 bit, little-endian, data-type-policy=OVERRIDE, i-signal-type=PRIMITIVE, init-value=0, base-type=BT_NM_HVZB_UDS_CC, compu {0=Cx0_Inaktiv (CM_NM_HVZB_UDS_CC_Cx0_Inaktiv), 1=Cx1_CC_aktiv (CM_NM_HVZB_UDS_CC_Cx1_CC_aktiv)}, range raw 0..1, transfer-property=TRIGGERED  # Funktionseinschränkung aufgrund aktivem UDS-Communication Control, siehe VW80124
          signal NM_HVZB_Wakeup_V12_XIX_NM_HVZB_XIX_HCP5_CANFD01: start 152, 8 bit, little-endian, data-type-policy=OVERRIDE, i-signal-type=PRIMITIVE, init-value=0, base-type=BT_NM_HVZB_Wakeup_V12, compu {0=Cx0_Peripherie_Wakeup_Ursache_nicht_bekannt (CM_NM_HVZB_Wakeup_V12_Cx0_Peripherie_Wakeup_Ursache_nicht_bekannt), 1=Cx1_Bus_Wakeup (CM_NM_HVZB_Wakeup_V12_Cx1_Bus_Wakeup), 2=Cx2_KL15_HW (CM_NM_HVZB_Wakeup_V12_Cx2_KL15_HW)}, range raw 0..2, transfer-property=TRIGGERED  # enthält die Weckursache; stehen mehrere Weckursachen parallel an, dann muss der kleinste Wert übertragen werden
          signal NM_HVZB_NM_aktiv_KL15_XIX_NM_HVZB_XIX_HCP5_CANFD01: start 160, 1 bit, little-endian, data-type-policy=OVERRIDE, i-signal-type=PRIMITIVE, init-value=0, base-type=BT_NM_HVZB_NM_aktiv_KL15, compu {0=Cx0_Inaktiv (CM_NM_HVZB_NM_aktiv_KL15_Cx0_Inaktiv), 1=Cx1_KL15_EIN (CM_NM_HVZB_NM_aktiv_KL15_Cx1_KL15_EIN)}, range raw 0..1, transfer-property=TRIGGERED  # Steuergerät hat KL15-EIN erkannt
          signal NM_HVZB_NM_aktiv_Diag_XIX_NM_HVZB_XIX_HCP5_CANFD01: start 161, 1 bit, little-endian, data-type-policy=OVERRIDE, i-signal-type=PRIMITIVE, init-value=0, base-type=BT_NM_HVZB_NM_aktiv_Diag, compu {0=Cx0_Inaktiv (CM_NM_HVZB_NM_aktiv_Diag_Cx0_Inaktiv), 1=Cx1_Diagnose_aktiv (CM_NM_HVZB_NM_aktiv_Diag_Cx1_Diagnose_aktiv)}, range raw 0..1, transfer-property=TRIGGERED  # Diagnose befindet sich nach VW80124 in einer NonDefaultDiagnostic-Session, z.B. ExtendedDiagnostic-Session
          signal NM_HVZB_NM_aktiv_Tmin_XIX_NM_HVZB_XIX_HCP5_CANFD01: start 162, 1 bit, little-endian, data-type-policy=OVERRIDE, i-signal-type=PRIMITIVE, init-value=0, base-type=BT_NM_HVZB_NM_aktiv_Tmin, compu {0=Cx0_Inaktiv (CM_NM_HVZB_NM_aktiv_Tmin_Cx0_Inaktiv), 1=Cx1_Mindestaktivzeit (CM_NM_HVZB_NM_aktiv_Tmin_Cx1_Mindestaktivzeit)}, range raw 0..1, transfer-property=TRIGGERED  # Mindestaktivzeit ist noch nicht abgelaufen (bei jedem Weckereignis wird die Mindestaktivzeit neu gestartet)
      frame NM_Hybrid_01_XIX_HCP5_CANFD01: id 0x1B00007B, from BMC_HV, frame-length=24, can-addressing-mode=EXTENDED, can-frame-rx-behavior=CAN-FD, can-frame-tx-behavior=CAN-FD, rx-identifier-range={lower-can-id=452984832, upper-can-id=452985855}
        nm pdu NM_Hybrid_01_XIX_HCP5_CANFD01: length=24, unused-bit-pattern=0
          signal NM_Hybrid_01_CBV_AWB_XIX_NM_Hybrid_01_XIX_HCP5_CANFD01: start 4, 1 bit, little-endian, data-type-policy=OVERRIDE, i-signal-type=PRIMITIVE, init-value=0, base-type=BT_NM_Hybrid_01_CBV_AWB, compu {0=Cx0_Passiver_WakeUp (CM_NM_Hybrid_01_CBV_AWB_Cx0_Passiver_WakeUp), 1=Cx1_Aktiver_WakeUp (CM_NM_Hybrid_01_CBV_AWB_Cx1_Aktiver_WakeUp)}, range raw 0..1, transfer-property=TRIGGERED  # Das Signal ist zu setzen, wenn das SG aktiv den Bus geweckt hat 0 = Passiver_WakeUp = SG hat das Netzwerk nicht aktiv geweckt 1 = Akitiver_WakeUp = SG hat das Netzwerk aktiv geweckt
          signal NM_Hybrid_01_CBV_CRI_XIX_NM_Hybrid_01_XIX_HCP5_CANFD01: start 6, 1 bit, little-endian, data-type-policy=OVERRIDE, i-signal-type=PRIMITIVE, init-value=1, base-type=BT_NM_Hybrid_01_CBV_CRI, compu {0=Cx0_NM_ohne_Clusteranforderungen (CM_NM_Hybrid_01_CBV_CRI_Cx0_NM_ohne_Clusteranforderungen), 1=Cx1_NM_mit_Clusteranforderungen (CM_NM_Hybrid_01_CBV_CRI_Cx1_NM_mit_Clusteranforderungen)}, range raw 0..1, transfer-property=TRIGGERED  # Das Signal ist dauerhaft gesetzt, wenn das NM-Layout Cluster- Anforderungen enthält
          signal NM_Hybrid_01_FCAB_XIX_NM_Hybrid_01_XIX_HCP5_CANFD01: start 8, 56 bit, opaque, data-type-policy=OVERRIDE, i-signal-type=ARRAY, init-value=7 x 0b00000000, base-type=BT_NM_Hybrid_01_FCAB, compu {0=Cx0_Init (CM_NM_Hybrid_01_FCAB_Cx0_Init), 1=Cx1_01_CarWakeUp (CM_NM_Hybrid_01_FCAB_Cx1_01_CarWakeUp), 2=Cx2_02_Basefunction_Powertrain (CM_NM_Hybrid_01_FCAB_Cx2_02_Basefunction_Powertrain), 4=Cx4_03_Basefunction_Chassis (CM_NM_Hybrid_01_FCAB_Cx4_03_Basefunction_Chassis), 8=Cx8_04_Basefunction_DrivingAssistance (CM_NM_Hybrid_01_FCAB_Cx8_04_Basefunction_DrivingAssistance), 16=Cx10_05_Basefunction_Infotainment (CM_NM_Hybrid_01_FCAB_Cx10_05_Basefunction_Infotainment), 32=Cx20_06_Basefunction_ComfortLight (CM_NM_Hybrid_01_FCAB_Cx20_06_Basefunction_ComfortLight), 64=Cx40_07_Basefunction_CrossSection (CM_NM_Hybrid_01_FCAB_Cx40_07_Basefunction_CrossSection), 128=Cx80_08_Basefunction_Connectivity (CM_NM_Hybrid_01_FCAB_Cx80_08_Basefunction_Connectivity), 256=Cx100_09_Basefunction_DrivingAssistanceCore (CM_NM_Hybrid_01_FCAB_Cx100_09_Basefunction_DrivingAssistanceCore), 512=Cx200_10_Powertrain (CM_NM_Hybrid_01_FCAB_Cx200_10_Powertrain), 1024=Cx400_11_Chassis (CM_NM_Hybrid_01_FCAB_Cx400_11_Chassis), 2048=Cx800_12_GearSelector (CM_NM_Hybrid_01_FCAB_Cx800_12_GearSelector), 4096=Cx1000_13_Airbag (CM_NM_Hybrid_01_FCAB_Cx1000_13_Airbag), 8192=Cx2000_14_InfotainmentExtensions (CM_NM_Hybrid_01_FCAB_Cx2000_14_InfotainmentExtensions), 16384=Cx4000_15_InstrumentclusterDisplay (CM_NM_Hybrid_01_FCAB_Cx4000_15_InstrumentclusterDisplay), 32768=Cx8000_16_InfotainmentDisplay (CM_NM_Hybrid_01_FCAB_Cx8000_16_InfotainmentDisplay), 65536=Cx10000_17_Audio (CM_NM_Hybrid_01_FCAB_Cx10000_17_Audio), 131072=Cx20000_18_VirtualSideMirrors (CM_NM_Hybrid_01_FCAB_Cx20000_18_VirtualSideMirrors), 262144=Cx40000_19_Doors_Hatches (CM_NM_Hybrid_01_FCAB_Cx40000_19_Doors_Hatches), 524288=Cx80000_20_OptionalComfort (CM_NM_Hybrid_01_FCAB_Cx80000_20_OptionalComfort), 1048576=Cx100000_21_AirSuspension (CM_NM_Hybrid_01_FCAB_Cx100000_21_AirSuspension), 2097152=Cx200000_22_ExteriorLights (CM_NM_Hybrid_01_FCAB_Cx200000_22_ExteriorLights), 4194304=Cx400000_23_Climate (CM_NM_Hybrid_01_FCAB_Cx400000_23_Climate), 8388608=Cx800000_24_ThermoManagement (CM_NM_Hybrid_01_FCAB_Cx800000_24_ThermoManagement), 16777216=Cx1000000_25_AccessSystemSensors (CM_NM_Hybrid_01_FCAB_Cx1000000_25_AccessSystemSensors), 33554432=Cx2000000_26_HighVoltage_Charging (CM_NM_Hybrid_01_FCAB_Cx2000000_26_HighVoltage_Charging), 67108864=Cx4000000_27_Timemaster_Timer (CM_NM_Hybrid_01_FCAB_Cx4000000_27_Timemaster_Timer), 134217728=Cx8000000_28_OnboardTester_DataCollector (CM_NM_Hybrid_01_FCAB_Cx8000000_28_OnboardTester_DataCollector), 268435456=Cx10000000_29_SteeringColumnLock (CM_NM_Hybrid_01_FCAB_Cx10000000_29_SteeringColumnLock), 536870912=Cx20000000_30_EnergyManagement (CM_NM_Hybrid_01_FCAB_Cx20000000_30_EnergyManagement), 1073741824=Cx40000000_31_MultifunctionalSteeringWheel (CM_NM_Hybrid_01_FCAB_Cx40000000_31_MultifunctionalSteeringWheel), 2147483648=Cx80000000_32_OnlineAccess (CM_NM_Hybrid_01_FCAB_Cx80000000_32_OnlineAccess), 4294967296=Cx100000000_33_ExternalWirelessCommunication (CM_NM_Hybrid_01_FCAB_Cx100000000_33_ExternalWirelessCommunication), 8589934592=Cx200000000_34_GPS_Localization (CM_NM_Hybrid_01_FCAB_Cx200000000_34_GPS_Localization), 17179869184=Cx400000000_35_ExteriorSound (CM_NM_Hybrid_01_FCAB_Cx400000000_35_ExteriorSound), 34359738368=Cx800000000_36_Preheater (CM_NM_Hybrid_01_FCAB_Cx800000000_36_Preheater), 68719476736=Cx1000000000_37_HighVoltage_WirelessChargingStation (CM_NM_Hybrid_01_FCAB_Cx1000000000_37_HighVoltage_WirelessChargingStation), 549755813888=Cx8000000000_40_Diagnosis_Energy (CM_NM_Hybrid_01_FCAB_Cx8000000000_40_Diagnosis_Energy), 1099511627776=Cx10000000000_41_Diagnosis_Powertrain (CM_NM_Hybrid_01_FCAB_Cx10000000000_41_Diagnosis_Powertrain), 2199023255552=Cx20000000000_42_Diagnosis_FlexRay (CM_NM_Hybrid_01_FCAB_Cx20000000000_42_Diagnosis_FlexRay), 4398046511104=Cx40000000000_43_Diagnosis_DrivingAssistance (CM_NM_Hybrid_01_FCAB_Cx40000000000_43_Diagnosis_DrivingAssistance), 8796093022208=Cx80000000000_44_Diagnosis_Infotainment (CM_NM_Hybrid_01_FCAB_Cx80000000000_44_Diagnosis_Infotainment), 17592186044416=Cx100000000000_45_Diagnosis_Comfort (CM_NM_Hybrid_01_FCAB_Cx100000000000_45_Diagnosis_Comfort), 35184372088832=Cx200000000000_46_Diagnosis_Light (CM_NM_Hybrid_01_FCAB_Cx200000000000_46_Diagnosis_Light), 70368744177664=Cx400000000000_47_Diagnosis_ComfortLINs (CM_NM_Hybrid_01_FCAB_Cx400000000000_47_Diagnosis_ComfortLINs), 140737488355328=Cx800000000000_48_Diagnosis_ClimateTmeLINs (CM_NM_Hybrid_01_FCAB_Cx800000000000_48_Diagnosis_ClimateTmeLINs), 281474976710656=Cx1000000000000_49_reserved (CM_NM_Hybrid_01_FCAB_Cx1000000000000_49_reserved) (49_<reserved>), 4503599627370500.0=Cx10000000000000_53_Lock_Unlock (CM_NM_Hybrid_01_FCAB_Cx10000000000000_53_Lock_Unlock), 9007199254740990.0=Cx20000000000000_54_reserved (CM_NM_Hybrid_01_FCAB_Cx20000000000000_54_reserved) (54_<reserved>), 1.8014398509482e+16=Cx40000000000000_55_Dimming (CM_NM_Hybrid_01_FCAB_Cx40000000000000_55_Dimming), 3.6028797018964e+16=Cx80000000000000_56_ChargingStatus (CM_NM_Hybrid_01_FCAB_Cx80000000000000_56_ChargingStatus)}, range raw 0..36028797018963968, transfer-property=TRIGGERED-ON-CHANGE  # FCAB = Funktions-Cluster-Aktiv-Bits
          signal NM_Hybrid_01_SNI_10_XIX_NM_Hybrid_01_XIX_HCP5_CANFD01: start 128, 10 bit, little-endian, data-type-policy=OVERRIDE, i-signal-type=PRIMITIVE, init-value=123, base-type=BT_NM_Hybrid_01_SNI_10, compu {123=Cx7b_Hybrid_01_SNI (CM_NM_Hybrid_01_SNI_10_Cx7b_Hybrid_01_SNI)}, range raw 123, transfer-property=TRIGGERED  # Source Node-Identifier (SNI) identifiziert den Sender der NM-Botschaft (Knotenadresse) eindeutig im Fahrzeug
          signal NM_Hybrid_01_NM_State_XIX_NM_Hybrid_01_XIX_HCP5_CANFD01: start 144, 6 bit, little-endian, data-type-policy=OVERRIDE, i-signal-type=PRIMITIVE, init-value=0, base-type=BT_NM_Hybrid_01_NM_State, compu {0=Cx0_Init (CM_NM_Hybrid_01_NM_State_Cx0_Init), 1=Cx1_NM_RM_aus_BSM (CM_NM_Hybrid_01_NM_State_Cx1_NM_RM_aus_BSM), 2=Cx2_NM_RM_aus_PBSM (CM_NM_Hybrid_01_NM_State_Cx2_NM_RM_aus_PBSM), 4=Cx4_NM_NO_aus_RM (CM_NM_Hybrid_01_NM_State_Cx4_NM_NO_aus_RM), 8=Cx8_NM_NO_aus_RS (CM_NM_Hybrid_01_NM_State_Cx8_NM_NO_aus_RS), 16=Cx10_reserved (CM_NM_Hybrid_01_NM_State_Cx10_reserved), 32=Cx20_reserved (CM_NM_Hybrid_01_NM_State_Cx20_reserved)}, range raw 0..32, transfer-property=TRIGGERED  # 1 = Zustand Repeat Message (<-- Bus-Sleep Mode) 2 = Zustand Repeat Message (<-- Prepare Bus-Sleep Mode) 4 = Zustand Normal Operation (<-- Repeat Message) 8 = Zustand Normal Operation (<-- Ready Sleep)
          signal NM_Hybrid_01_UDS_CC_XIX_NM_Hybrid_01_XIX_HCP5_CANFD01: start 151, 1 bit, little-endian, data-type-policy=OVERRIDE, i-signal-type=PRIMITIVE, init-value=0, base-type=BT_NM_Hybrid_01_UDS_CC, compu {0=Cx0_Inaktiv (CM_NM_Hybrid_01_UDS_CC_Cx0_Inaktiv), 1=Cx1_CC_aktiv (CM_NM_Hybrid_01_UDS_CC_Cx1_CC_aktiv)}, range raw 0..1, transfer-property=TRIGGERED  # Funktionseinschränkung aufgrund aktivem UDS-Communication Control, siehe VW80124
          signal NM_Hybrid_01_Wakeup_V12_XIX_NM_Hybrid_01_XIX_HCP5_CANFD01: start 152, 8 bit, little-endian, data-type-policy=OVERRIDE, i-signal-type=PRIMITIVE, init-value=0, base-type=BT_NM_Hybrid_01_Wakeup_V12, compu {0=Cx0_Peripherie_Wakeup_Ursache_nicht_bekannt (CM_NM_Hybrid_01_Wakeup_V12_Cx0_Peripherie_Wakeup_Ursache_nicht_bekannt), 1=Cx1_Bus_Wakeup (CM_NM_Hybrid_01_Wakeup_V12_Cx1_Bus_Wakeup), 2=Cx2_KL15_HW (CM_NM_Hybrid_01_Wakeup_V12_Cx2_KL15_HW), 128=Cx80_Konditionierungsbedarf (CM_NM_Hybrid_01_Wakeup_V12_Cx80_Konditionierungsbedarf)}, range raw 0..128, transfer-property=TRIGGERED  # enthält die Weckursache; stehen mehrere Weckursachen parallel an, dann muss der kleinste Wert übertragen werden
          signal NM_Hybrid_01_NM_aktiv_KL15_XIX_NM_Hybrid_01_XIX_HCP5_CANFD01: start 160, 1 bit, little-endian, data-type-policy=OVERRIDE, i-signal-type=PRIMITIVE, init-value=0, base-type=BT_NM_Hybrid_01_NM_aktiv_KL15, compu {0=Cx0_Inaktiv (CM_NM_Hybrid_01_NM_aktiv_KL15_Cx0_Inaktiv), 1=Cx1_KL15_EIN (CM_NM_Hybrid_01_NM_aktiv_KL15_Cx1_KL15_EIN)}, range raw 0..1, transfer-property=TRIGGERED  # Steuergerät hat KL15-EIN erkannt
          signal NM_Hybrid_01_NM_aktiv_Diag_XIX_NM_Hybrid_01_XIX_HCP5_CANFD01: start 161, 1 bit, little-endian, data-type-policy=OVERRIDE, i-signal-type=PRIMITIVE, init-value=0, base-type=BT_NM_Hybrid_01_NM_aktiv_Diag, compu {0=Cx0_Inaktiv (CM_NM_Hybrid_01_NM_aktiv_Diag_Cx0_Inaktiv), 1=Cx1_Diagnose_aktiv (CM_NM_Hybrid_01_NM_aktiv_Diag_Cx1_Diagnose_aktiv)}, range raw 0..1, transfer-property=TRIGGERED  # Diagnose befindet sich nach VW80124 in einer NonDefaultDiagnostic-Session, z.B. ExtendedDiagnostic-Session
          signal NM_Hybrid_01_NM_aktiv_Tmin_XIX_NM_Hybrid_01_XIX_HCP5_CANFD01: start 162, 1 bit, little-endian, data-type-policy=OVERRIDE, i-signal-type=PRIMITIVE, init-value=0, base-type=BT_NM_Hybrid_01_NM_aktiv_Tmin, compu {0=Cx0_Inaktiv (CM_NM_Hybrid_01_NM_aktiv_Tmin_Cx0_Inaktiv), 1=Cx1_Mindestaktivzeit (CM_NM_Hybrid_01_NM_aktiv_Tmin_Cx1_Mindestaktivzeit)}, range raw 0..1, transfer-property=TRIGGERED  # Mindestaktivzeit ist noch nicht abgelaufen (bei jedem Weckereignis wird die Mindestaktivzeit neu gestartet)
          signal NM_aktiv_Konditionierungsbedarf_XIX_NM_Hybrid_01_XIX_HCP5_CANFD01: start 163, 1 bit, little-endian, data-type-policy=OVERRIDE, i-signal-type=PRIMITIVE, init-value=0, base-type=BT_NM_aktiv_Konditionierungsbedarf, compu {0=Cx0_Inaktiv (CM_NM_aktiv_Konditionierungsbedarf_Cx0_Inaktiv), 1=Cx1_Aktiv (CM_NM_aktiv_Konditionierungsbedarf_Cx1_Aktiv)}, range raw 0..1, transfer-property=TRIGGERED  # Die Batterie überwacht die Temperatur der Batterie und kann eine Konditionierung fordern.
          signal NM_aktiv_SubbusSteuerung_BMC_HV_XIX_NM_Hybrid_01_XIX_HCP5_CANFD01: start 164, 1 bit, little-endian, data-type-policy=OVERRIDE, i-signal-type=PRIMITIVE, init-value=0, base-type=BT_NM_aktiv_SubbusSteuerung_BMC_HV, compu {0=Cx0_Inaktiv (CM_NM_aktiv_SubbusSteuerung_BMC_HV_Cx0_Inaktiv), 1=Cx1_Aktiv (CM_NM_aktiv_SubbusSteuerung_BMC_HV_Cx1_Aktiv)}, range raw 0..1, transfer-property=TRIGGERED  # Wird für die Weiterleitung der Weckanforderungen an den SubCAN benötigt.
      frame NM_Ladegeraet_XIX_HCP5_CANFD01: id 0x1B000044, to BMC_HV, frame-length=24, can-addressing-mode=EXTENDED, can-frame-rx-behavior=CAN-FD, can-frame-tx-behavior=CAN-FD, rx-identifier-range={lower-can-id=452984832, upper-can-id=452985855}
        nm pdu NM_Ladegeraet_XIX_HCP5_CANFD01: length=24, unused-bit-pattern=0
          signal NM_Ladegeraet_CBV_AWB_XIX_NM_Ladegeraet_XIX_HCP5_CANFD01: start 4, 1 bit, little-endian, data-type-policy=OVERRIDE, i-signal-type=PRIMITIVE, init-value=0, base-type=BT_NM_Ladegeraet_CBV_AWB, compu {0=Cx0_Passiver_WakeUp (CM_NM_Ladegeraet_CBV_AWB_Cx0_Passiver_WakeUp), 1=Cx1_Aktiver_WakeUp (CM_NM_Ladegeraet_CBV_AWB_Cx1_Aktiver_WakeUp)}, range raw 0..1, transfer-property=TRIGGERED  # Das Signal ist zu setzen, wenn das SG aktiv den Bus geweckt hat 0 = Passiver_WakeUp = SG hat das Netzwerk nicht aktiv geweckt 1 = Akitiver_WakeUp = SG hat das Netzwerk aktiv geweckt
          signal NM_Ladegeraet_CBV_CRI_XIX_NM_Ladegeraet_XIX_HCP5_CANFD01: start 6, 1 bit, little-endian, data-type-policy=OVERRIDE, i-signal-type=PRIMITIVE, init-value=0, base-type=BT_NM_Ladegeraet_CBV_CRI, compu {0=Cx0_Standard_Layout (CM_NM_Ladegeraet_CBV_CRI_Cx0_Standard_Layout), 1=Cx1_TNB_Layout (CM_NM_Ladegeraet_CBV_CRI_Cx1_TNB_Layout)}, range raw 0..1, transfer-property=TRIGGERED  # Das Signal ist dauerhaft gesetzt, wenn das NM-Layout dem neuen NM-Layout für Teilnetzbetrieb entspricht
          signal NM_Ladegeraet_FCAB_XIX_NM_Ladegeraet_XIX_HCP5_CANFD01: start 8, 56 bit, opaque, data-type-policy=OVERRIDE, i-signal-type=ARRAY, init-value=7 x 0, base-type=BT_NM_Ladegeraet_FCAB, compu {0=Cx0_Init (CM_NM_Ladegeraet_FCAB_Cx0_Init), 1=Cx1_01_CarWakeUp (CM_NM_Ladegeraet_FCAB_Cx1_01_CarWakeUp), 2=Cx2_02_Basefunction_Powertrain (CM_NM_Ladegeraet_FCAB_Cx2_02_Basefunction_Powertrain), 4=Cx4_03_Basefunction_Chassis (CM_NM_Ladegeraet_FCAB_Cx4_03_Basefunction_Chassis), 8=Cx8_04_Basefunction_DrivingAssistance (CM_NM_Ladegeraet_FCAB_Cx8_04_Basefunction_DrivingAssistance), 16=Cx10_05_Basefunction_Infotainment (CM_NM_Ladegeraet_FCAB_Cx10_05_Basefunction_Infotainment), 32=Cx20_06_Basefunction_ComfortLight (CM_NM_Ladegeraet_FCAB_Cx20_06_Basefunction_ComfortLight), 64=Cx40_07_Basefunction_CrossSection (CM_NM_Ladegeraet_FCAB_Cx40_07_Basefunction_CrossSection), 128=Cx80_08_Basefunction_Connectivity (CM_NM_Ladegeraet_FCAB_Cx80_08_Basefunction_Connectivity), 256=Cx100_09_Basefunction_DrivingAssistanceCore (CM_NM_Ladegeraet_FCAB_Cx100_09_Basefunction_DrivingAssistanceCore), 512=Cx200_10_Powertrain (CM_NM_Ladegeraet_FCAB_Cx200_10_Powertrain), 1024=Cx400_11_Chassis (CM_NM_Ladegeraet_FCAB_Cx400_11_Chassis), 2048=Cx800_12_GearSelector (CM_NM_Ladegeraet_FCAB_Cx800_12_GearSelector), 4096=Cx1000_13_Airbag (CM_NM_Ladegeraet_FCAB_Cx1000_13_Airbag), 8192=Cx2000_14_InfotainmentExtensions (CM_NM_Ladegeraet_FCAB_Cx2000_14_InfotainmentExtensions), 16384=Cx4000_15_InstrumentclusterDisplay (CM_NM_Ladegeraet_FCAB_Cx4000_15_InstrumentclusterDisplay), 32768=Cx8000_16_InfotainmentDisplay (CM_NM_Ladegeraet_FCAB_Cx8000_16_InfotainmentDisplay), 65536=Cx10000_17_Audio (CM_NM_Ladegeraet_FCAB_Cx10000_17_Audio), 131072=Cx20000_18_VirtualSideMirrors (CM_NM_Ladegeraet_FCAB_Cx20000_18_VirtualSideMirrors), 262144=Cx40000_19_Doors_Hatches (CM_NM_Ladegeraet_FCAB_Cx40000_19_Doors_Hatches), 524288=Cx80000_20_OptionalComfort (CM_NM_Ladegeraet_FCAB_Cx80000_20_OptionalComfort), 1048576=Cx100000_21_AirSuspension (CM_NM_Ladegeraet_FCAB_Cx100000_21_AirSuspension), 2097152=Cx200000_22_ExteriorLights (CM_NM_Ladegeraet_FCAB_Cx200000_22_ExteriorLights), 4194304=Cx400000_23_Climate (CM_NM_Ladegeraet_FCAB_Cx400000_23_Climate), 8388608=Cx800000_24_ThermoManagement (CM_NM_Ladegeraet_FCAB_Cx800000_24_ThermoManagement), 16777216=Cx1000000_25_AccessSystemSensors (CM_NM_Ladegeraet_FCAB_Cx1000000_25_AccessSystemSensors), 33554432=Cx2000000_26_HighVoltage_Charging (CM_NM_Ladegeraet_FCAB_Cx2000000_26_HighVoltage_Charging), 67108864=Cx4000000_27_Timemaster_Timer (CM_NM_Ladegeraet_FCAB_Cx4000000_27_Timemaster_Timer), 134217728=Cx8000000_28_OnboardTester_DataCollector (CM_NM_Ladegeraet_FCAB_Cx8000000_28_OnboardTester_DataCollector), 268435456=Cx10000000_29_SteeringColumnLock (CM_NM_Ladegeraet_FCAB_Cx10000000_29_SteeringColumnLock), 536870912=Cx20000000_30_EnergyManagement (CM_NM_Ladegeraet_FCAB_Cx20000000_30_EnergyManagement), 1073741824=Cx40000000_31_MultifunctionalSteeringWheel (CM_NM_Ladegeraet_FCAB_Cx40000000_31_MultifunctionalSteeringWheel), 2147483648=Cx80000000_32_OnlineAccess (CM_NM_Ladegeraet_FCAB_Cx80000000_32_OnlineAccess), 4294967296=Cx100000000_33_ExternalWirelessCommunication (CM_NM_Ladegeraet_FCAB_Cx100000000_33_ExternalWirelessCommunication), 8589934592=Cx200000000_34_GPS_Localization (CM_NM_Ladegeraet_FCAB_Cx200000000_34_GPS_Localization), 17179869184=Cx400000000_35_ExteriorSound (CM_NM_Ladegeraet_FCAB_Cx400000000_35_ExteriorSound), 34359738368=Cx800000000_36_Preheater (CM_NM_Ladegeraet_FCAB_Cx800000000_36_Preheater), 68719476736=Cx1000000000_37_HighVoltage_WirelessChargingStation (CM_NM_Ladegeraet_FCAB_Cx1000000000_37_HighVoltage_WirelessChargingStation), 549755813888=Cx8000000000_40_Diagnosis_Energy (CM_NM_Ladegeraet_FCAB_Cx8000000000_40_Diagnosis_Energy), 1099511627776=Cx10000000000_41_Diagnosis_Powertrain (CM_NM_Ladegeraet_FCAB_Cx10000000000_41_Diagnosis_Powertrain), 2199023255552=Cx20000000000_42_Diagnosis_FlexRay (CM_NM_Ladegeraet_FCAB_Cx20000000000_42_Diagnosis_FlexRay), 4398046511104=Cx40000000000_43_Diagnosis_DrivingAssistance (CM_NM_Ladegeraet_FCAB_Cx40000000000_43_Diagnosis_DrivingAssistance), 8796093022208=Cx80000000000_44_Diagnosis_Infotainment (CM_NM_Ladegeraet_FCAB_Cx80000000000_44_Diagnosis_Infotainment), 17592186044416=Cx100000000000_45_Diagnosis_Comfort (CM_NM_Ladegeraet_FCAB_Cx100000000000_45_Diagnosis_Comfort), 35184372088832=Cx200000000000_46_Diagnosis_Light (CM_NM_Ladegeraet_FCAB_Cx200000000000_46_Diagnosis_Light), 70368744177664=Cx400000000000_47_Diagnosis_ComfortLINs (CM_NM_Ladegeraet_FCAB_Cx400000000000_47_Diagnosis_ComfortLINs), 140737488355328=Cx800000000000_48_Diagnosis_ClimateTmeLINs (CM_NM_Ladegeraet_FCAB_Cx800000000000_48_Diagnosis_ClimateTmeLINs), 281474976710656=Cx1000000000000_49_reserved (CM_NM_Ladegeraet_FCAB_Cx1000000000000_49_reserved) (49_<reserved>), 4503599627370500.0=Cx10000000000000_53_Lock_Unlock (CM_NM_Ladegeraet_FCAB_Cx10000000000000_53_Lock_Unlock), 9007199254740990.0=Cx20000000000000_54_reserved (CM_NM_Ladegeraet_FCAB_Cx20000000000000_54_reserved) (54_<reserved>), 1.8014398509482e+16=Cx40000000000000_55_Dimming (CM_NM_Ladegeraet_FCAB_Cx40000000000000_55_Dimming), 3.6028797018964e+16=Cx80000000000000_56_ChargingStatus (CM_NM_Ladegeraet_FCAB_Cx80000000000000_56_ChargingStatus)}, range raw 0..36028797018963968, transfer-property=TRIGGERED-ON-CHANGE, to BMC_HV(timeout 2 s)  # FCAB = Funktions-Cluster-Aktiv-Bits
          signal NM_Ladegeraet_SNI_10_XIX_NM_Ladegeraet_XIX_HCP5_CANFD01: start 128, 10 bit, little-endian, data-type-policy=OVERRIDE, i-signal-type=PRIMITIVE, init-value=68, base-type=BT_NM_Ladegeraet_SNI_10, compu {68=Cx44_Ladegeraet_SNI (CM_NM_Ladegeraet_SNI_10_Cx44_Ladegeraet_SNI)}, range raw 68, transfer-property=TRIGGERED  # Source Node-Identifier (SNI) identifiziert den Sender der NM-Botschaft (Knotenadresse) eindeutig im Fahrzeug
          signal NM_Ladegeraet_NM_State_XIX_NM_Ladegeraet_XIX_HCP5_CANFD01: start 144, 6 bit, little-endian, data-type-policy=OVERRIDE, i-signal-type=PRIMITIVE, init-value=0, base-type=BT_NM_Ladegeraet_NM_State, compu {0=Cx0_Init (CM_NM_Ladegeraet_NM_State_Cx0_Init), 1=Cx1_NM_RM_aus_BSM (CM_NM_Ladegeraet_NM_State_Cx1_NM_RM_aus_BSM), 2=Cx2_NM_RM_aus_PBSM (CM_NM_Ladegeraet_NM_State_Cx2_NM_RM_aus_PBSM), 4=Cx4_NM_NO_aus_RM (CM_NM_Ladegeraet_NM_State_Cx4_NM_NO_aus_RM), 8=Cx8_NM_NO_aus_RS (CM_NM_Ladegeraet_NM_State_Cx8_NM_NO_aus_RS), 16=Cx10_reserved (CM_NM_Ladegeraet_NM_State_Cx10_reserved), 32=Cx20_reserved (CM_NM_Ladegeraet_NM_State_Cx20_reserved)}, range raw 0..32, transfer-property=TRIGGERED  # 1 = Zustand Repeat Message (<-- Bus-Sleep Mode) 2 = Zustand Repeat Message (<-- Prepare Bus-Sleep Mode) 4 = Zustand Normal Operation (<-- Repeat Message) 8 = Zustand Normal Operation (<-- Ready Sleep)
          signal NM_Ladegeraet_UDS_CC_XIX_NM_Ladegeraet_XIX_HCP5_CANFD01: start 151, 1 bit, little-endian, data-type-policy=OVERRIDE, i-signal-type=PRIMITIVE, init-value=0, base-type=BT_NM_Ladegeraet_UDS_CC, compu {0=Cx0_Init (CM_NM_Ladegeraet_UDS_CC_Cx0_Init), 1=Cx1_CC_aktiv (CM_NM_Ladegeraet_UDS_CC_Cx1_CC_aktiv)}, range raw 0..1, transfer-property=TRIGGERED  # Funktionseinschränkung aufgrund aktivem UDS-Communication Control; siehe VW80124
          signal NM_Ladegeraet_Wakeup_V12_XIX_NM_Ladegeraet_XIX_HCP5_CANFD01: start 152, 8 bit, little-endian, data-type-policy=OVERRIDE, i-signal-type=PRIMITIVE, init-value=0, base-type=BT_NM_Ladegeraet_Wakeup_V12, compu {0=Cx0_Peripherie_Wakeup_Ursache_nicht_bekannt (CM_NM_Ladegeraet_Wakeup_V12_Cx0_Peripherie_Wakeup_Ursache_nicht_bekannt), 1=Cx1_Bus_Wakeup (CM_NM_Ladegeraet_Wakeup_V12_Cx1_Bus_Wakeup), 2=Cx2_KL15_HW (CM_NM_Ladegeraet_Wakeup_V12_Cx2_KL15_HW)}, range raw 0..2, transfer-property=TRIGGERED  # enthält die Weckursache; stehen mehrere Weckursachen parallel an, dann muss der kleinste Wert übertragen werden
          signal NM_Ladegeraet_NM_aktiv_KL15_XIX_NM_Ladegeraet_XIX_HCP5_CANFD01: start 160, 1 bit, little-endian, data-type-policy=OVERRIDE, i-signal-type=PRIMITIVE, init-value=0, base-type=BT_NM_Ladegeraet_NM_aktiv_KL15, compu {0=Cx0_Inaktiv (CM_NM_Ladegeraet_NM_aktiv_KL15_Cx0_Inaktiv), 1=Cx1_KL15_EIN (CM_NM_Ladegeraet_NM_aktiv_KL15_Cx1_KL15_EIN)}, range raw 0..1, transfer-property=TRIGGERED  # Steuergerät hat KL15-EIN erkannt
          signal NM_Ladegeraet_NM_aktiv_Diag_XIX_NM_Ladegeraet_XIX_HCP5_CANFD01: start 161, 1 bit, little-endian, data-type-policy=OVERRIDE, i-signal-type=PRIMITIVE, init-value=0, base-type=BT_NM_Ladegeraet_NM_aktiv_Diag, compu {0=Cx0_Inaktiv (CM_NM_Ladegeraet_NM_aktiv_Diag_Cx0_Inaktiv), 1=Cx1_Diagnose_aktiv (CM_NM_Ladegeraet_NM_aktiv_Diag_Cx1_Diagnose_aktiv)}, range raw 0..1, transfer-property=TRIGGERED  # Diagnose befindet sich nach VW80124 in einer NonDefaultDiagnostic-Session, z.B. ExtendedDiagnostic-Session
          signal NM_Ladegeraet_NM_aktiv_Tmin_XIX_NM_Ladegeraet_XIX_HCP5_CANFD01: start 162, 1 bit, little-endian, data-type-policy=OVERRIDE, i-signal-type=PRIMITIVE, init-value=0, base-type=BT_NM_Ladegeraet_NM_aktiv_Tmin, compu {0=Cx0_Inaktiv (CM_NM_Ladegeraet_NM_aktiv_Tmin_Cx0_Inaktiv), 1=Cx1_Mindestaktivzeit (CM_NM_Ladegeraet_NM_aktiv_Tmin_Cx1_Mindestaktivzeit)}, range raw 0..1, transfer-property=TRIGGERED  # Mindestaktivzeit ist noch nicht abgelaufen (bei jedem Weckereignis wird die Mindestaktivzeit neu gestartet)
